VERSION "HNNBNNNYNNNNNNNNNNNNNNNNNNNNNNNNNNNNNNNNNN/4/%%%/4/'%**4NNN///"

NS_ :

BS_:

BU_: ADR_PAG_X2 BAP_Tester GW_App_PAG_PF GW_Routing_PAG_PF Klima_PAG_PF Klimakomp_Dash_PAG_PF Kombi_PAG_PF Miko_PAG_X2 OCU_PAG_PF RDK_High_PAG_PF

BO_ 1706 Kombi_12_PAG: 8 Kombi_PAG_PF
 SG_ KBI_STH_Std : 0|5@1+ (1,0) [0|23] "Unit_Hours"  GW_App_PAG_PF
 SG_ KBI_STH_Min : 5|6@1+ (1,0) [0|59] "Unit_Minut"  GW_App_PAG_PF
 SG_ KBI_STH_TT : 11|5@1+ (1,0) [1|31] "Unit_Day"  GW_App_PAG_PF
 SG_ KBI_STH_MM : 16|4@1+ (1,0) [1|12] "Unit_Month"  GW_App_PAG_PF
 SG_ KBI_STH_JJ : 20|7@1+ (1,0) [0|127] "Unit_Year"  GW_App_PAG_PF
 SG_ KBI_STH_Status : 27|2@1+ (1,0) [0|3] "" Vector__XXX
 SG_ KBI_STH_Timer_Status : 29|1@1+ (1,0) [0|1] ""  GW_App_PAG_PF
 SG_ KBI_STH_Betriebsdauer : 30|6@1+ (1,0) [0|60] "Unit_Minut" Vector__XXX
 SG_ KBI_Menu1_Pos1 : 40|1@1+ (1,0) [0|1] ""  Klima_PAG_PF
 SG_ KBI_Menu1_Pos2 : 41|1@1+ (1,0) [0|1] ""  Klima_PAG_PF
 SG_ KBI_Menu1_Pos3 : 42|1@1+ (1,0) [0|1] ""  Klima_PAG_PF
 SG_ KBI_Menu1_Pos4 : 43|1@1+ (1,0) [0|1] ""  Klima_PAG_PF
 SG_ KBI_Menu1_Pos5 : 44|1@1+ (1,0) [0|1] ""  Klima_PAG_PF
 SG_ KBI_Menu1_Pos6 : 45|1@1+ (1,0) [0|1] ""  Klima_PAG_PF
 SG_ KBI_Menu1_Pos7 : 46|1@1+ (1,0) [0|1] ""  Klima_PAG_PF
 SG_ KBI_Menu1_Pos8 : 47|1@1+ (1,0) [0|1] ""  Klima_PAG_PF
 SG_ KBI_Menu2_Pos1 : 48|1@1+ (1,0) [0|1] ""  Klima_PAG_PF
 SG_ KBI_Menu2_Pos2 : 49|1@1+ (1,0) [0|1] ""  Klima_PAG_PF
 SG_ KBI_Menu2_Pos3 : 50|1@1+ (1,0) [0|1] ""  Klima_PAG_PF
 SG_ KBI_Menu2_Pos4 : 51|1@1+ (1,0) [0|1] ""  Klima_PAG_PF
 SG_ KBI_Menu2_Pos5 : 52|1@1+ (1,0) [0|1] ""  Klima_PAG_PF
 SG_ KBI_Menu2_Pos6 : 53|1@1+ (1,0) [0|1] ""  Klima_PAG_PF
 SG_ KBI_Menu2_Pos7 : 54|1@1+ (1,0) [0|1] ""  Klima_PAG_PF
 SG_ KBI_Menu2_Pos8 : 55|1@1+ (1,0) [0|1] ""  Klima_PAG_PF
 SG_ KBI_Menu3_Pos1 : 56|1@1+ (1,0) [0|1] ""  Klima_PAG_PF
 SG_ KBI_Menu3_Pos2 : 57|1@1+ (1,0) [0|1] ""  Klima_PAG_PF
 SG_ KBI_Menu3_Pos3 : 58|1@1+ (1,0) [0|1] ""  Klima_PAG_PF
 SG_ KBI_Menu3_Pos4 : 59|1@1+ (1,0) [0|1] ""  Klima_PAG_PF
 SG_ KBI_Menu3_Pos5 : 60|1@1+ (1,0) [0|1] ""  Klima_PAG_PF
 SG_ KBI_Menu3_Pos6 : 61|1@1+ (1,0) [0|1] ""  Klima_PAG_PF
 SG_ KBI_Menu3_Pos7 : 62|1@1+ (1,0) [0|1] ""  Klima_PAG_PF
 SG_ KBI_Menu3_Pos8 : 63|1@1+ (1,0) [0|1] ""  Klima_PAG_PF

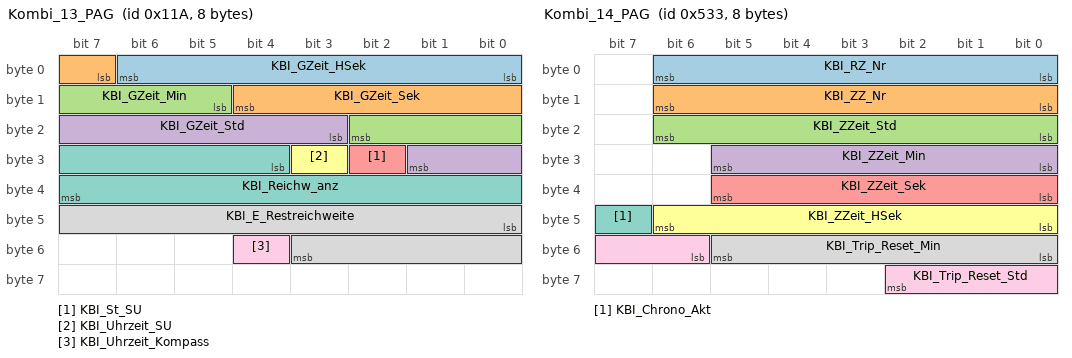
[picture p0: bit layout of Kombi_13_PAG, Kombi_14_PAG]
BO_ 282 Kombi_13_PAG: 8 Kombi_PAG_PF
 SG_ KBI_GZeit_HSek : 0|7@1+ (1,0) [0|99] ""  GW_Routing_PAG_PF
 SG_ KBI_GZeit_Sek : 7|6@1+ (1,0) [0|59] "Unit_Secon"  GW_Routing_PAG_PF
 SG_ KBI_GZeit_Min : 13|6@1+ (1,0) [0|59] "Unit_Minut"  GW_Routing_PAG_PF
 SG_ KBI_GZeit_Std : 19|7@1+ (1,0) [0|99] "Unit_Hours"  GW_Routing_PAG_PF
 SG_ KBI_St_SU : 26|1@1+ (1,0) [0|1] ""  GW_Routing_PAG_PF
 SG_ KBI_Uhrzeit_SU : 27|1@1+ (1,0) [0|1] ""  GW_Routing_PAG_PF
 SG_ KBI_Reichw_anz : 28|12@1+ (1,0) [0|4095] "Unit_KiloMeter"  ADR_PAG_X2,GW_Routing_PAG_PF,OCU_PAG_PF
 SG_ KBI_E_Restreichweite : 40|12@1+ (1,0) [0|4093] "Unit_KiloMeter"  ADR_PAG_X2,GW_Routing_PAG_PF,OCU_PAG_PF
 SG_ KBI_Uhrzeit_Kompass : 52|1@1+ (1,0) [0|1] ""  GW_Routing_PAG_PF

BO_ 1331 Kombi_14_PAG: 8 Kombi_PAG_PF
 SG_ KBI_RZ_Nr : 0|7@1+ (1,0) [0|99] ""  GW_Routing_PAG_PF
 SG_ KBI_ZZ_Nr : 8|7@1+ (1,0) [0|99] ""  GW_Routing_PAG_PF
 SG_ KBI_ZZeit_Std : 16|7@1+ (1,0) [0|99] "Unit_Hours"  GW_Routing_PAG_PF
 SG_ KBI_ZZeit_Min : 24|6@1+ (1,0) [0|59] "Unit_Minut"  GW_Routing_PAG_PF
 SG_ KBI_ZZeit_Sek : 32|6@1+ (1,0) [0|59] "Unit_Secon"  GW_Routing_PAG_PF
 SG_ KBI_ZZeit_HSek : 40|7@1+ (1,0) [0|99] ""  GW_Routing_PAG_PF
 SG_ KBI_Chrono_Akt : 47|1@1+ (1,0) [0|1] ""  GW_Routing_PAG_PF
 SG_ KBI_Trip_Reset_Min : 48|6@1+ (1,0) [0|63] ""  ADR_PAG_X2,GW_Routing_PAG_PF,OCU_PAG_PF
 SG_ KBI_Trip_Reset_Std : 54|5@1+ (1,0) [0|31] ""  ADR_PAG_X2,GW_Routing_PAG_PF,OCU_PAG_PF

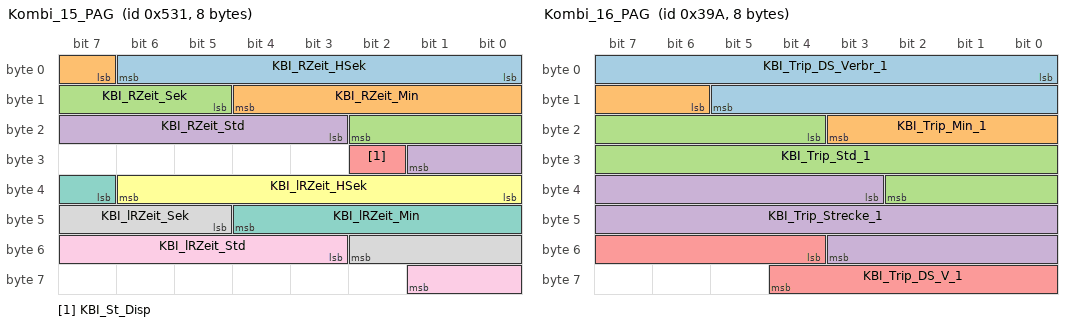
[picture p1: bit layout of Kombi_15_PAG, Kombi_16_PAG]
BO_ 1329 Kombi_15_PAG: 8 Kombi_PAG_PF
 SG_ KBI_RZeit_HSek : 0|7@1+ (1,0) [0|99] "" Vector__XXX
 SG_ KBI_RZeit_Min : 7|6@1+ (1,0) [0|59] "Unit_Minut" Vector__XXX
 SG_ KBI_RZeit_Sek : 13|6@1+ (1,0) [0|59] "Unit_Secon" Vector__XXX
 SG_ KBI_RZeit_Std : 19|7@1+ (1,0) [0|99] "Unit_Hours" Vector__XXX
 SG_ KBI_St_Disp : 26|1@1+ (1,0) [0|1] "" Vector__XXX
 SG_ KBI_lRZeit_HSek : 32|7@1+ (1,0) [0|99] "" Vector__XXX
 SG_ KBI_lRZeit_Min : 39|6@1+ (1,0) [0|59] "" Vector__XXX
 SG_ KBI_lRZeit_Sek : 45|6@1+ (1,0) [0|59] "" Vector__XXX
 SG_ KBI_lRZeit_Std : 51|7@1+ (1,0) [0|99] "Unit_Hours" Vector__XXX

BO_ 922 Kombi_16_PAG: 8 Kombi_PAG_PF
 SG_ KBI_Trip_DS_Verbr_1 : 0|14@1+ (0.01,0) [0|99.99] "Unit_LiterPer100Kilometer"  ADR_PAG_X2,GW_Routing_PAG_PF,OCU_PAG_PF
 SG_ KBI_Trip_Min_1 : 14|6@1+ (1,0) [0|59] "Unit_Minut"  ADR_PAG_X2,GW_Routing_PAG_PF,OCU_PAG_PF
 SG_ KBI_Trip_Std_1 : 20|15@1+ (1,0) [0|9999] "Unit_Hours"  ADR_PAG_X2,GW_Routing_PAG_PF,OCU_PAG_PF
 SG_ KBI_Trip_Strecke_1 : 35|17@1+ (0.1,0) [0|9999.9] "Unit_KiloMeter"  ADR_PAG_X2,GW_Routing_PAG_PF,OCU_PAG_PF
 SG_ KBI_Trip_DS_V_1 : 52|9@1+ (1,0) [0|399] "Unit_KiloMeterPerHour"  ADR_PAG_X2,GW_Routing_PAG_PF,OCU_PAG_PF

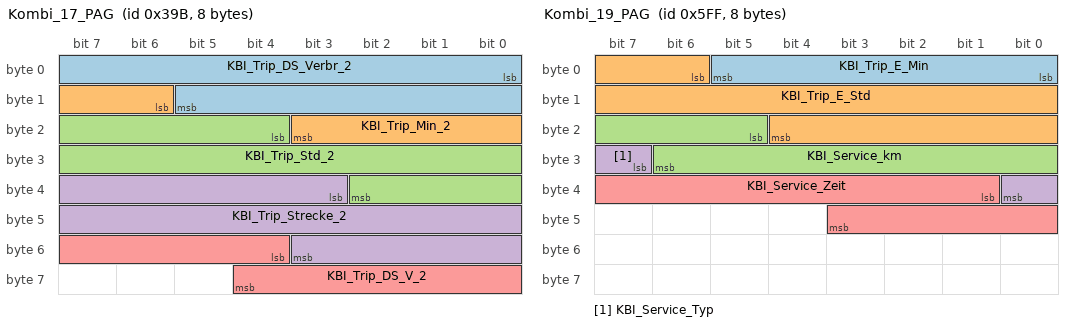
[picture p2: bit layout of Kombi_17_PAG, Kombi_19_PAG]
BO_ 923 Kombi_17_PAG: 8 Kombi_PAG_PF
 SG_ KBI_Trip_DS_Verbr_2 : 0|14@1+ (0.01,0) [0|99.99] "Unit_LiterPer100Kilometer"  ADR_PAG_X2,GW_Routing_PAG_PF,OCU_PAG_PF
 SG_ KBI_Trip_Min_2 : 14|6@1+ (1,0) [0|59] "Unit_Minut"  ADR_PAG_X2,GW_Routing_PAG_PF,OCU_PAG_PF
 SG_ KBI_Trip_Std_2 : 20|15@1+ (1,0) [0|9999] "Unit_Hours"  ADR_PAG_X2,GW_Routing_PAG_PF,OCU_PAG_PF
 SG_ KBI_Trip_Strecke_2 : 35|17@1+ (0.1,0) [0|9999.9] "Unit_KiloMeter"  ADR_PAG_X2,GW_Routing_PAG_PF,OCU_PAG_PF
 SG_ KBI_Trip_DS_V_2 : 52|9@1+ (1,0) [0|399] "Unit_KiloMeterPerHour"  ADR_PAG_X2,GW_Routing_PAG_PF,OCU_PAG_PF

BO_ 1534 Kombi_18_PAG: 8 ADR_PAG_X2
 SG_ KBI_Set_Timer_MUX M : 0|3@1+ (1,0) [0|7] ""  GW_Routing_PAG_PF
 SG_ KBI_Set_Timer_1_Jahr m1 : 3|7@1+ (1,2000) [2000|2125] "Unit_Year"  GW_Routing_PAG_PF
 SG_ KBI_Set_Timer_2_Jahr m2 : 3|7@1+ (1,2000) [2000|2125] "Unit_Year"  GW_Routing_PAG_PF
 SG_ KBI_Set_Timer_3_Jahr m3 : 3|7@1+ (1,2000) [2000|2125] "Unit_Year"  GW_Routing_PAG_PF
 SG_ KBI_Set_Timer_4_Jahr m4 : 3|7@1+ (1,2000) [2000|2125] "Unit_Year"  GW_Routing_PAG_PF
 SG_ KBI_Set_Timer_1_Minute m1 : 10|6@1+ (1,0) [0|59] "Unit_Minut"  GW_Routing_PAG_PF
 SG_ KBI_Set_Timer_2_Minute m2 : 10|6@1+ (1,0) [0|59] "Unit_Minut"  GW_Routing_PAG_PF
 SG_ KBI_Set_Timer_3_Minute m3 : 10|6@1+ (1,0) [0|0] "Unit_Minut"  GW_Routing_PAG_PF
 SG_ KBI_Set_Timer_4_Minute m4 : 10|6@1+ (1,0) [0|0] "Unit_Minut"  GW_Routing_PAG_PF
 SG_ KBI_Set_Timer_1_Monat m1 : 16|4@1+ (1,0) [1|12] "Unit_Month"  GW_Routing_PAG_PF
 SG_ KBI_Set_Timer_2_Monat m2 : 16|4@1+ (1,0) [1|12] "Unit_Month"  GW_Routing_PAG_PF
 SG_ KBI_Set_Timer_3_Monat m3 : 16|4@1+ (1,0) [1|12] "Unit_Month"  GW_Routing_PAG_PF
 SG_ KBI_Set_Timer_4_Monat m4 : 16|4@1+ (1,0) [1|12] "Unit_Month"  GW_Routing_PAG_PF
 SG_ KBI_Set_Timer_1_Stunde m1 : 20|5@1+ (1,0) [0|23] "Unit_Hours"  GW_Routing_PAG_PF
 SG_ KBI_Set_Timer_2_Stunde m2 : 20|5@1+ (1,0) [0|23] "Unit_Hours"  GW_Routing_PAG_PF
 SG_ KBI_Set_Timer_3_Stunde m3 : 20|5@1+ (1,0) [0|23] "Unit_Hours"  GW_Routing_PAG_PF
 SG_ KBI_Set_Timer_4_Stunde m4 : 20|5@1+ (1,0) [0|23] "Unit_Hours"  GW_Routing_PAG_PF
 SG_ KBI_Set_Timer_1_Tag m1 : 25|5@1+ (1,0) [1|31] "Unit_Day"  GW_Routing_PAG_PF
 SG_ KBI_Set_Timer_2_Tag m2 : 25|5@1+ (1,0) [1|31] "Unit_Day"  GW_Routing_PAG_PF
 SG_ KBI_Set_Timer_3_Tag m3 : 25|5@1+ (1,0) [1|31] "Unit_Day"  GW_Routing_PAG_PF
 SG_ KBI_Set_Timer_4_Tag m4 : 25|5@1+ (1,0) [1|31] "Unit_Day"  GW_Routing_PAG_PF
 SG_ KBI_Set_Timer_1_Laden m1 : 30|1@1+ (1,0) [0|1] ""  GW_Routing_PAG_PF
 SG_ KBI_Set_Timer_2_Laden m2 : 30|1@1+ (1,0) [0|1] ""  GW_Routing_PAG_PF
 SG_ KBI_Set_Timer_3_Laden m3 : 30|1@1+ (1,0) [0|1] ""  GW_Routing_PAG_PF
 SG_ KBI_Set_Timer_4_Laden m4 : 30|1@1+ (1,0) [0|1] ""  GW_Routing_PAG_PF
 SG_ KBI_Set_Timer_1_Vorklima m1 : 31|1@1+ (1,0) [0|1] ""  GW_Routing_PAG_PF
 SG_ KBI_Set_Timer_2_Vorklima m2 : 31|1@1+ (1,0) [0|1] ""  GW_Routing_PAG_PF
 SG_ KBI_Set_Timer_3_Vorklima m3 : 31|1@1+ (1,0) [0|1] ""  GW_Routing_PAG_PF
 SG_ KBI_Set_Timer_4_Vorklima m4 : 31|1@1+ (1,0) [0|1] ""  GW_Routing_PAG_PF
 SG_ KBI_Set_Timer_1_Zyklus_Mo m1 : 32|1@1+ (1,0) [0|1] ""  GW_Routing_PAG_PF
 SG_ KBI_Set_Timer_2_Zyklus_Mo m2 : 32|1@1+ (1,0) [0|1] ""  GW_Routing_PAG_PF
 SG_ KBI_Set_Timer_3_Zyklus_Mo m3 : 32|1@1+ (1,0) [0|1] ""  GW_Routing_PAG_PF
 SG_ KBI_Set_Timer_4_Zyklus_Mo m4 : 32|1@1+ (1,0) [0|1] ""  GW_Routing_PAG_PF
 SG_ KBI_Set_Timer_1_Zyklus_Di m1 : 33|1@1+ (1,0) [0|1] ""  GW_Routing_PAG_PF
 SG_ KBI_Set_Timer_2_Zyklus_Di m2 : 33|1@1+ (1,0) [0|1] ""  GW_Routing_PAG_PF
 SG_ KBI_Set_Timer_3_Zyklus_Di m3 : 33|1@1+ (1,0) [0|1] ""  GW_Routing_PAG_PF
 SG_ KBI_Set_Timer_4_Zyklus_Di m4 : 33|1@1+ (1,0) [0|1] ""  GW_Routing_PAG_PF
 SG_ KBI_Set_Timer_1_Zyklus_Mi m1 : 34|1@1+ (1,0) [0|1] ""  GW_Routing_PAG_PF
 SG_ KBI_Set_Timer_2_Zyklus_Mi m2 : 34|1@1+ (1,0) [0|1] ""  GW_Routing_PAG_PF
 SG_ KBI_Set_Timer_3_Zyklus_Mi m3 : 34|1@1+ (1,0) [0|1] ""  GW_Routing_PAG_PF
 SG_ KBI_Set_Timer_4_Zyklus_Mi m4 : 34|1@1+ (1,0) [0|1] ""  GW_Routing_PAG_PF
 SG_ KBI_Set_Timer_1_Zyklus_Do m1 : 35|1@1+ (1,0) [0|1] ""  GW_Routing_PAG_PF
 SG_ KBI_Set_Timer_2_Zyklus_Do m2 : 35|1@1+ (1,0) [0|1] ""  GW_Routing_PAG_PF
 SG_ KBI_Set_Timer_3_Zyklus_Do m3 : 35|1@1+ (1,0) [0|1] ""  GW_Routing_PAG_PF
 SG_ KBI_Set_Timer_4_Zyklus_Do m4 : 35|1@1+ (1,0) [0|1] ""  GW_Routing_PAG_PF
 SG_ KBI_Set_Timer_1_Zyklus_Fr m1 : 36|1@1+ (1,0) [0|1] ""  GW_Routing_PAG_PF
 SG_ KBI_Set_Timer_2_Zyklus_Fr m2 : 36|1@1+ (1,0) [0|1] ""  GW_Routing_PAG_PF
 SG_ KBI_Set_Timer_3_Zyklus_Fr m3 : 36|1@1+ (1,0) [0|1] ""  GW_Routing_PAG_PF
 SG_ KBI_Set_Timer_4_Zyklus_Fr m4 : 36|1@1+ (1,0) [0|1] ""  GW_Routing_PAG_PF
 SG_ KBI_Set_Timer_1_Zyklus_Sa m1 : 37|1@1+ (1,0) [0|1] ""  GW_Routing_PAG_PF
 SG_ KBI_Set_Timer_2_Zyklus_Sa m2 : 37|1@1+ (1,0) [0|1] ""  GW_Routing_PAG_PF
 SG_ KBI_Set_Timer_3_Zyklus_Sa m3 : 37|1@1+ (1,0) [0|1] ""  GW_Routing_PAG_PF
 SG_ KBI_Set_Timer_4_Zyklus_Sa m4 : 37|1@1+ (1,0) [0|1] ""  GW_Routing_PAG_PF
 SG_ KBI_Set_Timer_1_Zyklus_So m1 : 38|1@1+ (1,0) [0|1] ""  GW_Routing_PAG_PF
 SG_ KBI_Set_Timer_2_Zyklus_So m2 : 38|1@1+ (1,0) [0|1] ""  GW_Routing_PAG_PF
 SG_ KBI_Set_Timer_3_Zyklus_So m3 : 38|1@1+ (1,0) [0|1] ""  GW_Routing_PAG_PF
 SG_ KBI_Set_Timer_4_Zyklus_So m4 : 38|1@1+ (1,0) [0|1] ""  GW_Routing_PAG_PF
 SG_ KBI_Set_Timer_1_Zyklus_WH m1 : 39|1@1+ (1,0) [0|1] ""  GW_Routing_PAG_PF
 SG_ KBI_Set_Timer_2_Zyklus_WH m2 : 39|1@1+ (1,0) [0|1] ""  GW_Routing_PAG_PF
 SG_ KBI_Set_Timer_3_Zyklus_WH m3 : 39|1@1+ (1,0) [0|1] ""  GW_Routing_PAG_PF
 SG_ KBI_Set_Timer_4_Zyklus_WH m4 : 39|1@1+ (1,0) [0|1] ""  GW_Routing_PAG_PF

BO_ 1535 Kombi_19_PAG: 8 Kombi_PAG_PF
 SG_ KBI_Trip_E_Min : 0|6@1+ (1,0) [0|59] "Unit_Minut"  ADR_PAG_X2,GW_Routing_PAG_PF
 SG_ KBI_Trip_E_Std : 6|15@1+ (1,0) [0|9999] "Unit_Hours"  ADR_PAG_X2,GW_Routing_PAG_PF
 SG_ KBI_Service_km : 21|10@1+ (100,0) [0|102100] ""  GW_Routing_PAG_PF
 SG_ KBI_Service_Typ : 31|2@1+ (1,0) [0|3] ""  GW_Routing_PAG_PF
 SG_ KBI_Service_Zeit : 33|11@1+ (1,0) [0|2045] ""  GW_Routing_PAG_PF

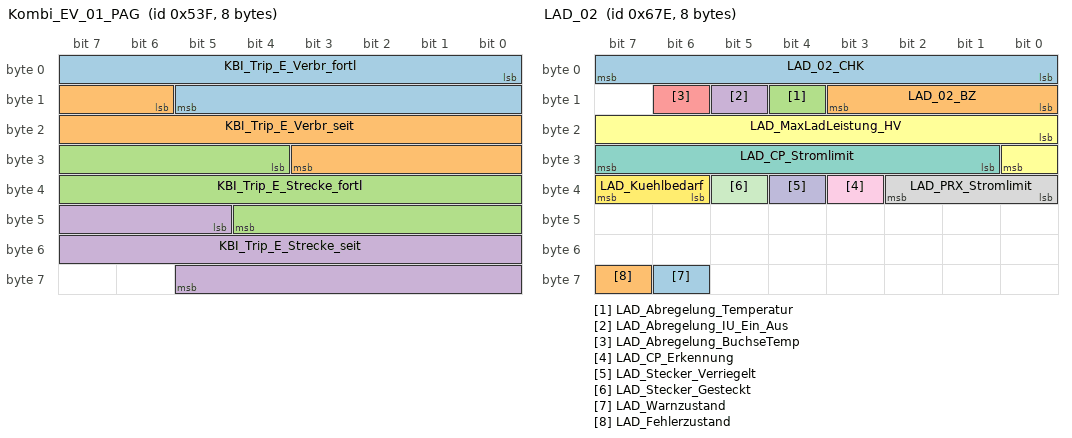
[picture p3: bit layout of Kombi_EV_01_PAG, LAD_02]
BO_ 1343 Kombi_EV_01_PAG: 8 Kombi_PAG_PF
 SG_ KBI_Trip_E_Verbr_fortl : 0|14@1+ (0.01,0) [0|100] "Unit_KiloWattHourPer100Kilometer"  ADR_PAG_X2,GW_Routing_PAG_PF,OCU_PAG_PF
 SG_ KBI_Trip_E_Verbr_seit : 14|14@1+ (0.01,0) [0|100] "Unit_KiloWattHourPer100Kilometer"  ADR_PAG_X2,GW_Routing_PAG_PF,OCU_PAG_PF
 SG_ KBI_Trip_E_Strecke_fortl : 28|17@1+ (0.1,0) [0|9999.9] "Unit_KiloMeter"  ADR_PAG_X2,GW_Routing_PAG_PF,OCU_PAG_PF
 SG_ KBI_Trip_E_Strecke_seit : 45|17@1+ (0.1,0) [0|9999.9] "Unit_KiloMeter"  ADR_PAG_X2,GW_Routing_PAG_PF,OCU_PAG_PF

BO_ 1662 LAD_02: 8 GW_Routing_PAG_PF
 SG_ LAD_02_CHK : 0|8@1+ (1,0) [0|255] "" Vector__XXX
 SG_ LAD_02_BZ : 8|4@1+ (1,0) [0|15] "" Vector__XXX
 SG_ LAD_Abregelung_Temperatur : 12|1@1+ (1,0) [0|1] "" Vector__XXX
 SG_ LAD_Abregelung_IU_Ein_Aus : 13|1@1+ (1,0) [0|1] "" Vector__XXX
 SG_ LAD_Abregelung_BuchseTemp : 14|1@1+ (1,0) [0|1] "" Vector__XXX
 SG_ LAD_MaxLadLeistung_HV : 16|9@1+ (100,0) [0|50900] "Unit_Watt" Vector__XXX
 SG_ LAD_CP_Stromlimit : 25|7@1+ (0.5,0) [0|62.5] "Unit_Amper" Vector__XXX
 SG_ LAD_PRX_Stromlimit : 32|3@1+ (1,0) [0|7] "" Vector__XXX
 SG_ LAD_CP_Erkennung : 35|1@1+ (1,0) [0|1] "" Vector__XXX
 SG_ LAD_Stecker_Verriegelt : 36|1@1+ (1,0) [0|1] "" Vector__XXX
 SG_ LAD_Stecker_Gesteckt : 37|1@1+ (1,0) [0|1] "" Vector__XXX
 SG_ LAD_Kuehlbedarf : 38|2@1+ (1,0) [0|3] "" Vector__XXX
 SG_ LAD_Warnzustand : 62|1@1+ (1,0) [0|1] ""  ADR_PAG_X2,Kombi_PAG_PF
 SG_ LAD_Fehlerzustand : 63|1@1+ (1,0) [0|1] ""  ADR_PAG_X2,Kombi_PAG_PF

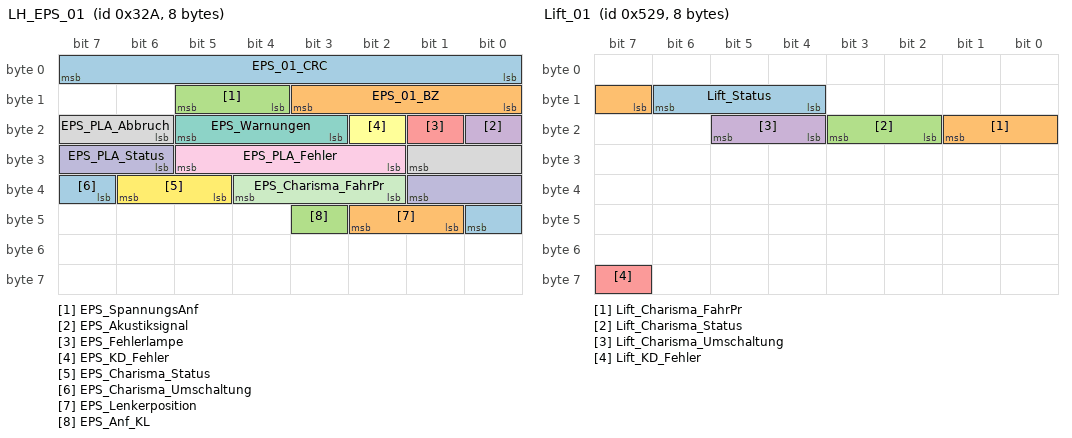
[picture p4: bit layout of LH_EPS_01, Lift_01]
BO_ 810 LH_EPS_01: 8 GW_Routing_PAG_PF
 SG_ EPS_01_CRC : 0|8@1+ (1,0) [0|255] "" Vector__XXX
 SG_ EPS_01_BZ : 8|4@1+ (1,0) [0|15] "" Vector__XXX
 SG_ EPS_SpannungsAnf : 12|2@1+ (1,0) [0|3] "" Vector__XXX
 SG_ EPS_Akustiksignal : 16|1@1+ (1,0) [0|1] "" Vector__XXX
 SG_ EPS_Fehlerlampe : 17|1@1+ (1,0) [0|1] "" Vector__XXX
 SG_ EPS_KD_Fehler : 18|1@1+ (1,0) [0|1] "" Vector__XXX
 SG_ EPS_Warnungen : 19|3@1+ (1,0) [0|7] ""  Kombi_PAG_PF
 SG_ EPS_PLA_Abbruch : 22|4@1+ (1,0) [0|15] "" Vector__XXX
 SG_ EPS_PLA_Fehler : 26|4@1+ (1,0) [0|15] "" Vector__XXX
 SG_ EPS_PLA_Status : 30|4@1+ (1,0) [0|15] "" Vector__XXX
 SG_ EPS_Charisma_FahrPr : 34|3@1+ (1,0) [0|7] "" Vector__XXX
 SG_ EPS_Charisma_Status : 37|2@1+ (1,0) [0|3] "" Vector__XXX
 SG_ EPS_Charisma_Umschaltung : 39|2@1+ (1,0) [0|3] "" Vector__XXX
 SG_ EPS_Lenkerposition : 41|2@1+ (1,0) [0|3] "" Vector__XXX
 SG_ EPS_Anf_KL : 43|1@1+ (1,0) [0|1] "" Vector__XXX

BO_ 1137 Licht_hinten_01: 8 GW_Routing_PAG_PF
 SG_ Licht_hinten_01_BZ : 0|4@1+ (1,0) [0|15] "" Vector__XXX
 SG_ BCM2_Bremsl_durch_ECD : 5|1@1+ (1,0) [0|1] "" Vector__XXX
 SG_ LH_Aussenlicht_def : 7|1@1+ (1,0) [0|1] "" Vector__XXX
 SG_ LH_Standlicht_H_aktiv : 8|1@1+ (1,0) [0|1] "" Vector__XXX
 SG_ LH_Parklicht_HL_aktiv : 9|1@1+ (1,0) [0|1] "" Vector__XXX
 SG_ LH_Parklicht_HR_aktiv : 10|1@1+ (1,0) [0|1] "" Vector__XXX
 SG_ LH_Bremslicht_H_aktiv : 11|1@1+ (1,0) [0|1] "" Vector__XXX
 SG_ LH_Nebelschluss_aktiv : 12|1@1+ (1,0) [0|1] "" Vector__XXX
 SG_ LH_Rueckfahrlicht_aktiv : 13|1@1+ (1,0) [0|1] "" Vector__XXX
 SG_ LH_Blinker_HL_akt : 14|1@1+ (1,0) [0|1] "" Vector__XXX
 SG_ LH_Blinker_HR_akt : 15|1@1+ (1,0) [0|1] "" Vector__XXX
 SG_ LH_Blinker_li_def : 16|1@1+ (1,0) [0|1] "" Vector__XXX
 SG_ LH_Bremsl_li_def : 17|1@1+ (1,0) [0|1] ""  Kombi_PAG_PF
 SG_ LH_Schlusslicht_li_def : 18|1@1+ (1,0) [0|1] ""  Kombi_PAG_PF
 SG_ LH_Rueckf_li_def : 19|1@1+ (1,0) [0|1] ""  Kombi_PAG_PF
 SG_ LH_Nebel_li_def : 20|1@1+ (1,0) [0|1] ""  Kombi_PAG_PF
 SG_ LH_Schluss_Brems_Nebel_li_def : 21|1@1+ (1,0) [0|1] ""  Kombi_PAG_PF
 SG_ LH_Schluss_Brems_Nebel_re_def : 22|1@1+ (1,0) [0|1] ""  Kombi_PAG_PF
 SG_ LH_Schluss_Brems_li_def : 24|1@1+ (1,0) [0|1] "" Vector__XXX
 SG_ LH_Schluss_Nebel_li_def : 25|1@1+ (1,0) [0|1] "" Vector__XXX
 SG_ LH_SL_BRL_BLK_li_def : 26|1@1+ (1,0) [0|1] "" Vector__XXX
 SG_ LH_Brems_Blk_li_def : 27|1@1+ (1,0) [0|1] "" Vector__XXX
 SG_ LH_Blinker_re_def : 32|1@1+ (1,0) [0|1] "" Vector__XXX
 SG_ LH_Bremsl_re_def : 33|1@1+ (1,0) [0|1] ""  Kombi_PAG_PF
 SG_ LH_Schlusslicht_re_def : 34|1@1+ (1,0) [0|1] ""  Kombi_PAG_PF
 SG_ LH_Rueckf_re_def : 35|1@1+ (1,0) [0|1] ""  Kombi_PAG_PF
 SG_ LH_Nebel_re_def : 36|1@1+ (1,0) [0|1] ""  Kombi_PAG_PF
 SG_ LH_Schluss_Brems_re_def : 40|1@1+ (1,0) [0|1] "" Vector__XXX
 SG_ LH_Schluss_Nebel_re_def : 41|1@1+ (1,0) [0|1] "" Vector__XXX
 SG_ LH_SL_BRL_BLK_re_def : 42|1@1+ (1,0) [0|1] "" Vector__XXX
 SG_ LH_Brems_Blk_re_def : 43|1@1+ (1,0) [0|1] "" Vector__XXX
 SG_ LH_Kennzl_def : 48|1@1+ (1,0) [0|1] ""  Kombi_PAG_PF
 SG_ LH_3_Bremsl_def : 49|1@1+ (1,0) [0|1] ""  Kombi_PAG_PF
 SG_ LH_Nebel_mi_def : 50|1@1+ (1,0) [0|1] "" Vector__XXX
 SG_ LH_Rueckf_mi_def : 51|1@1+ (1,0) [0|1] "" Vector__XXX
 SG_ LH_Bremsl_li_ges_def : 54|1@1+ (1,0) [0|1] "" Vector__XXX
 SG_ LH_Bremsl_re_ges_def : 55|1@1+ (1,0) [0|1] "" Vector__XXX

BO_ 1321 Lift_01: 8 GW_Routing_PAG_PF
 SG_ Lift_Status : 12|3@1+ (1,0) [0|7] ""  ADR_PAG_X2,Kombi_PAG_PF
 SG_ Lift_Charisma_FahrPr : 15|3@1+ (1,0) [0|7] "" Vector__XXX
 SG_ Lift_Charisma_Status : 18|2@1+ (1,0) [0|3] "" Vector__XXX
 SG_ Lift_Charisma_Umschaltung : 20|2@1+ (1,0) [0|3] "" Vector__XXX
 SG_ Lift_KD_Fehler : 63|1@1+ (1,0) [0|1] "" Vector__XXX

BO_ 917 LWR_AFS_01: 8 GW_Routing_PAG_PF
 SG_ AFS_Abbiegelicht_li_Anf : 0|1@1+ (1,0) [0|1] "" Vector__XXX
 SG_ AFS_Abbiegelicht_re_Anf : 1|1@1+ (1,0) [0|1] "" Vector__XXX
 SG_ AFS_Abbiegelicht_Dimm_Anf : 2|1@1+ (1,0) [0|1] "" Vector__XXX
 SG_ AFS_Verfuegbarkeit_GLW : 3|1@1+ (1,0) [0|1] "" Vector__XXX
 SG_ AFS_Status_adaptive_LV : 4|1@1+ (1,0) [0|1] "" Vector__XXX
 SG_ AFS_Fernlicht_li_defekt : 5|1@1+ (1,0) [0|1] "" Vector__XXX
 SG_ AFS_Fernlicht_re_defekt : 6|1@1+ (1,0) [0|1] "" Vector__XXX
 SG_ AFS_Fernlicht_Status : 7|1@1+ (1,0) [0|1] "" Vector__XXX
 SG_ LWR_AFS_01_BZ : 8|4@1+ (1,0) [0|15] "" Vector__XXX
 SG_ AFS_Lampe : 12|1@1+ (1,0) [0|1] "" Vector__XXX
 SG_ LWR_Lampe : 13|1@1+ (1,0) [0|1] "" Vector__XXX
 SG_ AFS_Fehlertext : 14|1@1+ (1,0) [0|1] "" Vector__XXX
 SG_ AFS_LED_Blinkmode : 15|1@1+ (1,0) [0|1] "" Vector__XXX
 SG_ LWR_Touristenmodus_aktiv : 16|1@1+ (1,0) [0|1] "" Vector__XXX
 SG_ AFS_Charisma_FahrPr : 17|3@1+ (1,0) [0|7] "" Vector__XXX
 SG_ AFS_Charisma_Status : 20|2@1+ (1,0) [0|3] "" Vector__XXX
 SG_ AFS_Charisma_Umschaltung : 22|2@1+ (1,0) [0|3] "" Vector__XXX
 SG_ AFS_Allwetterlicht : 24|1@1+ (1,0) [0|1] "" Vector__XXX
 SG_ LWR_Touristenmodus_verbaut : 25|1@1+ (1,0) [0|1] "" Vector__XXX
 SG_ AFS_adaptive_LV_verbaut : 26|1@1+ (1,0) [0|1] "" Vector__XXX
 SG_ LWR_Reisemodus_Texte : 27|2@1+ (1,0) [0|3] "" Vector__XXX
 SG_ GLW_Sensor_blockiert : 29|1@1+ (1,0) [0|1] "" Vector__XXX
 SG_ LWR_Pos_Schrittmotor : 32|8@1+ (0.4,0) [0|100] "Unit_PerCent" Vector__XXX
 SG_ LWR_Hoehenwert_VL : 40|8@1+ (1,-127) [-127|126] "" Vector__XXX
 SG_ LWR_Hoehenwert_HL : 48|8@1+ (1,-127) [-127|126] "" Vector__XXX
 SG_ AFS_Ersatzlicht_Links : 56|1@1+ (1,0) [0|1] "" Vector__XXX
 SG_ AFS_Ersatzlicht_Rechts : 57|1@1+ (1,0) [0|1] "" Vector__XXX
 SG_ LWR_AFS_Grundeinstellung : 58|1@1+ (1,0) [0|1] "" Vector__XXX
 SG_ LWR_AFS_Parametrisierung : 59|1@1+ (1,0) [0|1] "" Vector__XXX
 SG_ LWR_Initialisierungslauf : 60|1@1+ (1,0) [0|1] "" Vector__XXX
 SG_ LWR_Sicherheitsposition : 61|1@1+ (1,0) [0|1] "" Vector__XXX
 SG_ LWR_Modus : 62|1@1+ (1,0) [0|1] "" Vector__XXX
 SG_ LWR_KD_Fehler : 63|1@1+ (1,0) [0|1] ""  Kombi_PAG_PF

BO_ 1704 Mem_Kombi_01_PAG: 8 ADR_PAG_X2
 SG_ KBI_Aussenspiegel_absenken_auto : 0|1@1+ (1,0) [0|1] ""  GW_Routing_PAG_PF
 SG_ KBI_Aussenspiegel_einklapp_auto : 1|1@1+ (1,0) [0|1] ""  GW_Routing_PAG_PF
 SG_ KBI_Schaltpkt_Anz_ein : 2|1@1+ (1,0) [0|1] ""  GW_Routing_PAG_PF,Kombi_PAG_PF
 SG_ KBI_FULL_AFS_Tourist : 3|1@1+ (1,0) [0|1] ""  GW_Routing_PAG_PF
 SG_ KBI_Einstiegshilfe_aktiv : 4|1@1+ (1,0) [0|1] ""  GW_Routing_PAG_PF
 SG_ KBI_Schneekettenmodus_Aktiv : 5|1@1+ (1,0) [0|1] ""  GW_Routing_PAG_PF
 SG_ KBI_FLA_GLW_Aktiv : 6|1@1+ (1,0) [0|1] ""  GW_Routing_PAG_PF
 SG_ KBI_Dimmung_OriLicht : 8|7@1+ (1,0) [0|100] "Unit_PerCent"  GW_Routing_PAG_PF
 SG_ KBI_RS_d_akt : 15|1@1+ (1,0) [0|1] ""  GW_Routing_PAG_PF
 SG_ KBI_Nachleucht_IL : 16|5@1+ (10,0) [0|300] "Unit_Secon"  GW_Routing_PAG_PF
 SG_ KBI_Erw_BelueftFeld : 21|1@1+ (1,0) [0|1] ""  GW_Routing_PAG_PF,Klima_PAG_PF
 SG_ KBI_Auto_Umluft : 22|1@1+ (1,0) [0|1] ""  GW_Routing_PAG_PF,Klima_PAG_PF
 SG_ KBI_Heckrollo_b_R : 23|1@1+ (1,0) [0|1] ""  GW_Routing_PAG_PF
 SG_ KBI_Nachleucht : 24|5@1+ (5,0) [0|120] ""  GW_Routing_PAG_PF
 SG_ KBI_TFL_akt : 29|1@1+ (1,0) [0|1] ""  GW_Routing_PAG_PF
 SG_ KBI_Heckw_b_R : 30|2@1+ (1,0) [0|3] ""  GW_Routing_PAG_PF
 SG_ KBI_WV_Entr : 32|5@1+ (5,10) [10|100] ""  GW_Routing_PAG_PF
 SG_ KBI_Tuerentr_T : 37|1@1+ (1,0) [0|1] ""  GW_Routing_PAG_PF
 SG_ KBI_Carjack : 38|2@1+ (1,0) [0|3] ""  GW_Routing_PAG_PF
 SG_ KBI_WV_Entr_Kof : 40|4@1+ (1,0) [0|15] ""  GW_Routing_PAG_PF
 SG_ KBI_Automem_Inaktiv : 45|1@1+ (1,0) [0|1] ""  GW_Routing_PAG_PF,Klima_PAG_PF
 SG_ KBI_Jokerkey_Hupe_Aktiv : 46|1@1+ (1,0) [0|1] ""  GW_Routing_PAG_PF,Klima_PAG_PF
 SG_ KBI_LDW_aktiv : 47|1@1+ (1,0) [0|1] ""  GW_Routing_PAG_PF
 SG_ KBI_PTC_Zuheizer : 48|1@1+ (1,0) [0|1] ""  GW_Routing_PAG_PF,Klima_PAG_PF
 SG_ KBI_Steigerung_Luftmenge_Fond : 49|1@1+ (1,0) [0|1] ""  GW_Routing_PAG_PF
 SG_ KBI_Klimastyles : 51|2@1+ (1,0) [0|3] ""  GW_Routing_PAG_PF,Klima_PAG_PF
 SG_ KBI_Mittenduesentemp : 53|3@1+ (1,-4) [-4|3] ""  GW_Routing_PAG_PF,Klima_PAG_PF
 SG_ KBI_Dimmung_AmbLicht : 56|7@1+ (1,0) [0|100] "Unit_PerCent"  GW_Routing_PAG_PF
 SG_ KBI_Innenlicht_per_Tuerkontakt : 63|1@1+ (1,0) [0|1] ""  GW_Routing_PAG_PF,Miko_PAG_X2

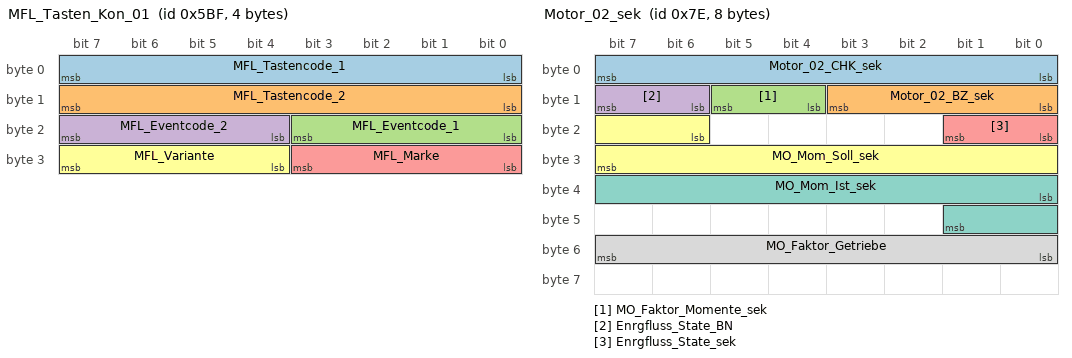
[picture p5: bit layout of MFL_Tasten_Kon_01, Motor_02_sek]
BO_ 1471 MFL_Tasten_Kon_01: 4 GW_Routing_PAG_PF
 SG_ MFL_Tastencode_1 : 0|8@1+ (1,0) [0|255] ""  ADR_PAG_X2,Klima_PAG_PF,Kombi_PAG_PF,Miko_PAG_X2
 SG_ MFL_Tastencode_2 : 8|8@1+ (1,0) [0|255] ""  ADR_PAG_X2,Klima_PAG_PF,Kombi_PAG_PF
 SG_ MFL_Eventcode_1 : 16|4@1+ (1,0) [0|15] ""  ADR_PAG_X2,Klima_PAG_PF,Kombi_PAG_PF
 SG_ MFL_Eventcode_2 : 20|4@1+ (1,0) [0|15] ""  ADR_PAG_X2,Klima_PAG_PF,Kombi_PAG_PF
 SG_ MFL_Marke : 24|4@1+ (1,0) [0|15] ""  ADR_PAG_X2,Klima_PAG_PF
 SG_ MFL_Variante : 28|4@1+ (1,0) [0|15] ""  ADR_PAG_X2,Klima_PAG_PF

BO_ 193 Miko_01_PAG: 8 Miko_PAG_X2
 SG_ Miko_KD_Fehler : 0|1@1+ (1,0) [0|1] "" Vector__XXX
 SG_ Miko_T_Defrost : 1|1@1+ (1,0) [0|1] "" Vector__XXX
 SG_ Miko_T_Auto : 2|1@1+ (1,0) [0|1] "" Vector__XXX
 SG_ Miko_T_Source : 3|1@1+ (1,0) [0|1] ""  ADR_PAG_X2
 SG_ Miko_T_AC_Menue : 4|1@1+ (1,0) [0|1] ""  ADR_PAG_X2
 SG_ Miko_T_Phone : 5|1@1+ (1,0) [0|1] ""  ADR_PAG_X2
 SG_ Miko_T_Media : 6|1@1+ (1,0) [0|1] ""  ADR_PAG_X2
 SG_ Miko_T_Tuner : 7|1@1+ (1,0) [0|1] ""  ADR_PAG_X2
 SG_ Miko_T_Back : 8|1@1+ (1,0) [0|1] ""  ADR_PAG_X2
 SG_ Miko_T_Option : 9|1@1+ (1,0) [0|1] ""  ADR_PAG_X2
 SG_ Miko_T_Car : 10|1@1+ (1,0) [0|1] ""  ADR_PAG_X2
 SG_ Miko_T_Info : 11|1@1+ (1,0) [0|1] ""  ADR_PAG_X2
 SG_ Miko_T_Navi : 12|1@1+ (1,0) [0|1] ""  ADR_PAG_X2
 SG_ Miko_T_Umluft : 13|1@1+ (1,0) [0|1] "" Vector__XXX
 SG_ Miko_T_AC : 14|1@1+ (1,0) [0|1] "" Vector__XXX
 SG_ Miko_T_Acmax : 15|1@1+ (1,0) [0|1] "" Vector__XXX
 SG_ Miko_Volume : 16|5@1+ (1,0) [0|32] ""  ADR_PAG_X2
 SG_ Miko_Volume_Err : 21|1@1+ (1,0) [0|1] ""  ADR_PAG_X2
 SG_ Miko_Volume_dir : 22|1@1+ (1,0) [0|1] ""  ADR_PAG_X2
 SG_ Miko_Volume_press : 23|2@1+ (1,0) [0|3] ""  ADR_PAG_X2
 SG_ Miko_MMI : 25|5@1+ (1,0) [0|32] ""  ADR_PAG_X2
 SG_ Miko_MMI_fast : 30|1@1+ (1,0) [0|1] ""  ADR_PAG_X2
 SG_ Miko_MMI_Err : 31|1@1+ (1,0) [0|1] ""  ADR_PAG_X2
 SG_ Miko_MMI_dir : 32|1@1+ (1,0) [0|1] ""  ADR_PAG_X2
 SG_ Miko_MMI_press : 33|2@1+ (1,0) [0|3] "" Vector__XXX
 SG_ Miko_Clima : 35|5@1+ (1,0) [0|32] "" Vector__XXX
 SG_ Miko_Clima_fast : 40|1@1+ (1,0) [0|1] "" Vector__XXX
 SG_ Miko_Clima_Err : 41|1@1+ (1,0) [0|1] "" Vector__XXX
 SG_ Miko_Clima_dir : 42|1@1+ (1,0) [0|1] "" Vector__XXX
 SG_ Miko_Clima_press : 43|2@1+ (1,0) [0|3] "" Vector__XXX
 SG_ Miko_ADR_Reset : 45|1@1+ (1,0) [0|1] ""  ADR_PAG_X2
 SG_ Miko_ADR_UltralongPress : 46|1@1+ (1,0) [0|1] ""  ADR_PAG_X2
 SG_ Miko_T_Blower : 47|1@1+ (1,0) [0|1] ""  Klima_PAG_PF
 SG_ Miko_T_Temp_left : 48|1@1+ (1,0) [0|1] ""  Klima_PAG_PF
 SG_ Miko_T_Temp_right : 49|1@1+ (1,0) [0|1] ""  Klima_PAG_PF

BO_ 126 Motor_02_sek: 8 GW_Routing_PAG_PF
 SG_ Motor_02_CHK_sek : 0|8@1+ (1,0) [0|255] "" Vector__XXX
 SG_ Motor_02_BZ_sek : 8|4@1+ (1,0) [0|15] "" Vector__XXX
 SG_ MO_Faktor_Momente_sek : 12|2@1+ (1,0) [0|3] "" Vector__XXX
 SG_ Enrgfluss_State_BN : 14|2@1+ (1,0) [0|3] ""  ADR_PAG_X2,Kombi_PAG_PF
 SG_ Enrgfluss_State_sek : 16|2@1+ (1,0) [0|3] ""  ADR_PAG_X2,Kombi_PAG_PF
 SG_ MO_Mom_Soll_sek : 22|10@1+ (1,0) [0|1021] "" Vector__XXX
 SG_ MO_Mom_Ist_sek : 32|10@1+ (1,0) [0|1021] "" Vector__XXX
 SG_ MO_Faktor_Getriebe : 48|8@1+ (0.4,0) [0|101.2] "Unit_PerCent" Vector__XXX

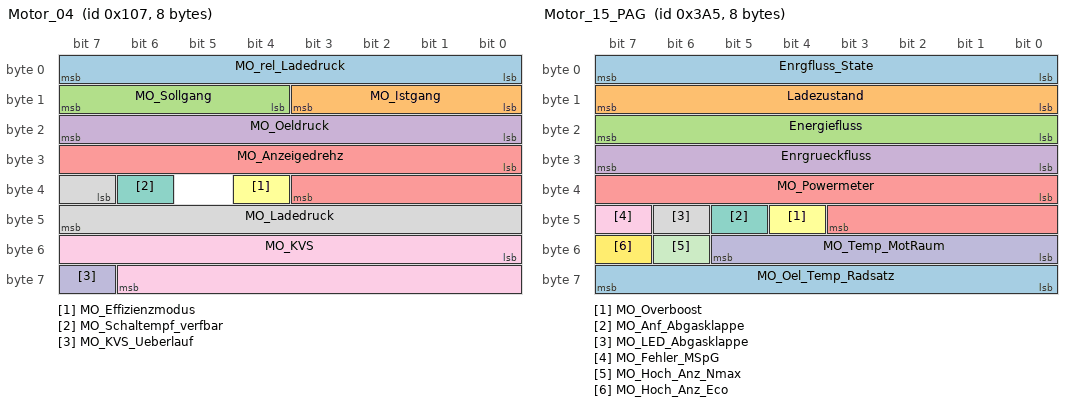
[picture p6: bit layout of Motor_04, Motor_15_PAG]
BO_ 263 Motor_04: 8 GW_Routing_PAG_PF
 SG_ MO_rel_Ladedruck : 0|8@1+ (0.4,0) [0|100] "Unit_PerCent" Vector__XXX
 SG_ MO_Istgang : 8|4@1+ (1,0) [0|15] "" Vector__XXX
 SG_ MO_Sollgang : 12|4@1+ (1,0) [0|15] "" Vector__XXX
 SG_ MO_Oeldruck : 16|8@1+ (0.04,0) [0|10] "Unit_Bar"  Kombi_PAG_PF
 SG_ MO_Anzeigedrehz : 24|12@1+ (3,0) [0|12282] "Unit_MinutInver"  Kombi_PAG_PF
 SG_ MO_Effizienzmodus : 36|1@1+ (1,0) [0|1] "" Vector__XXX
 SG_ MO_Schaltempf_verfbar : 38|1@1+ (1,0) [0|1] "" Vector__XXX
 SG_ MO_Ladedruck : 39|9@1+ (0.01,0) [0|5.1] "Unit_Bar" Vector__XXX
 SG_ MO_KVS : 48|15@1+ (1,0) [0|32767] "Unit_MicroLiter"  Kombi_PAG_PF
 SG_ MO_KVS_Ueberlauf : 63|1@1+ (1,0) [0|1] ""  Kombi_PAG_PF

BO_ 782 Motor_05: 8 GW_Routing_PAG_PF
 SG_ Motor_05_CHK : 0|8@1+ (1,0) [0|255] "" Vector__XXX
 SG_ Motor_05_BZ : 8|4@1+ (1,0) [0|15] "" Vector__XXX
 SG_ MO_EKlKomLeiRed : 12|2@1+ (1,0) [0|3] "" Vector__XXX
 SG_ MO_Freig_Reku : 14|2@1+ (1,0) [0|3] "" Vector__XXX
 SG_ MO_Klima_Eingr : 16|2@1+ (1,0) [0|3] ""  Klimakomp_Dash_PAG_PF
 SG_ MO_Status_Normalbetrieb_02 : 18|1@1+ (1,0) [0|1] "" Vector__XXX
 SG_ MO_Schaltbeeinfl_Leistungsbegr : 19|1@1+ (1,0) [0|1] "" Vector__XXX
 SG_ MO_Schaltbeeinfl_Partikelfilter : 20|1@1+ (1,0) [0|1] "" Vector__XXX
 SG_ MO_Prio_MIN_Wunschdrehzahl : 21|1@1+ (1,0) [0|1] "" Vector__XXX
 SG_ MO_Freig_Anlass : 22|1@1+ (1,0) [0|1] "" Vector__XXX
 SG_ MO_Aussp_Anlass : 23|1@1+ (1,0) [0|1] "" Vector__XXX
 SG_ MO_MAX_Wunschdrehzahl : 24|9@1+ (25,0) [0|12750] "Unit_MinutInver"  Kombi_PAG_PF
 SG_ MO_Prio_MAX_Wunschdrehzahl : 33|1@1+ (1,0) [0|1] "" Vector__XXX
 SG_ MO_Luftpfad_aktiv : 34|1@1+ (1,0) [0|1] "" Vector__XXX
 SG_ MO_v_Begrenz_Aktiv : 35|1@1+ (1,0) [0|1] "" Vector__XXX
 SG_ MO_v_Begrenz_Aktivierbar : 36|1@1+ (1,0) [0|1] "" Vector__XXX
 SG_ MO_Verbot_EKP : 37|1@1+ (1,0) [0|1] "" Vector__XXX
 SG_ MO_Anf_Pruefimpuls : 38|1@1+ (1,0) [0|1] "" Vector__XXX
 SG_ MO_Anf_KL75 : 39|1@1+ (1,0) [0|1] "" Vector__XXX
 SG_ MO_Charisma_FahrPr : 40|3@1+ (1,0) [0|7] "" Vector__XXX
 SG_ MO_Charisma_Status : 43|2@1+ (1,0) [0|3] "" Vector__XXX
 SG_ MO_Charisma_Umschaltung : 45|2@1+ (1,0) [0|3] "" Vector__XXX
 SG_ MO_Handshake_STH : 47|1@1+ (1,0) [0|1] "" Vector__XXX
 SG_ MO_MIN_Wunschdrehzahl : 48|8@1+ (25,0) [0|6350] "Unit_MinutInver" Vector__XXX
 SG_ MO_Drehzahlbeeinflussung : 56|8@1+ (0.39,0) [0|99.45] "Unit_PerCent" Vector__XXX

BO_ 1088 Motor_06: 8 GW_Routing_PAG_PF
 SG_ MO_Kuehlerluefter_MUX M : 0|1@1+ (1,0) [0|1] "" Vector__XXX
 SG_ MO_Kuehlerluefter_1 m0 : 1|7@1+ (1,0) [0|100] "Unit_PerCent" Vector__XXX
 SG_ MO_Kuehlerluefter_2 m1 : 1|7@1+ (1,0) [0|100] "Unit_PerCent" Vector__XXX
 SG_ MO_HYB_Status_HV_Ladung : 8|3@1+ (1,0) [0|7] "" Vector__XXX
 SG_ MO_ITM_Warnung_Pumpe : 11|1@1+ (1,0) [0|1] "" Vector__XXX
 SG_ WIV_Anzeige_aktiv : 12|1@1+ (1,0) [0|1] "" Vector__XXX
 SG_ WIV_Oelmin_Warn : 13|1@1+ (1,0) [0|1] ""  Kombi_PAG_PF
 SG_ WIV_Sensorfehler : 14|1@1+ (1,0) [0|1] ""  Kombi_PAG_PF
 SG_ WIV_Schieflage : 15|1@1+ (1,0) [0|1] "" Vector__XXX
 SG_ WIV_Oelstand : 16|4@1+ (12.5,0) [0|100] "Unit_PerCent"  Kombi_PAG_PF
 SG_ MO_Zustand_HWP : 20|2@1+ (1,0) [0|3] "" Vector__XXX
 SG_ MO_Kat_Warnung : 22|1@1+ (1,0) [0|1] "" Vector__XXX
 SG_ WIV_Oelsystem_aktiv : 24|1@1+ (1,0) [0|1] ""  Kombi_PAG_PF
 SG_ WIV_nicht_betriebswarm : 25|1@1+ (1,0) [0|1] "" Vector__XXX
 SG_ WIV_Ueberfuell_Warn : 26|1@1+ (1,0) [0|1] ""  Kombi_PAG_PF
 SG_ WIV_laufender_Motor : 27|1@1+ (1,0) [0|1] "" Vector__XXX
 SG_ MO_HYB_Text_1 : 28|1@1+ (1,0) [0|1] ""  Kombi_PAG_PF
 SG_ MO_HYB_Text_2 : 29|1@1+ (1,0) [0|1] ""  Kombi_PAG_PF
 SG_ MO_HYB_Text_3 : 30|1@1+ (1,0) [0|1] ""  Kombi_PAG_PF
 SG_ MO_HYB_Text_4 : 31|1@1+ (1,0) [0|1] ""  ADR_PAG_X2,Kombi_PAG_PF
 SG_ MO_Text_Motorstart : 32|4@1+ (1,0) [0|15] "" Vector__XXX
 SG_ MO_HYB_Text_5 : 36|1@1+ (1,0) [0|1] ""  Kombi_PAG_PF
 SG_ MO_HYB_Text_6 : 37|1@1+ (1,0) [0|1] ""  Kombi_PAG_PF
 SG_ MO_HYB_Text_7 : 38|1@1+ (1,0) [0|1] ""  Kombi_PAG_PF
 SG_ WIV_Oeldyn_avl : 39|1@1+ (1,0) [0|1] "" Vector__XXX
 SG_ MO_Text_MSG_Werkstatt : 40|1@1+ (1,0) [0|1] ""  Kombi_PAG_PF
 SG_ MO_Text_Partikelfil_Reg : 41|1@1+ (1,0) [0|1] "" Vector__XXX
 SG_ MO_Text_Fehler_Kraftstoffsys : 42|1@1+ (1,0) [0|1] "" Vector__XXX
 SG_ WIV_Oelmenge : 43|5@1+ (125,0) [0|3875] "Unit_MilliLiter" Vector__XXX
 SG_ MO_Systemlampe : 48|1@1+ (1,0) [0|1] "" Vector__XXX
 SG_ MO_OBD2_Lampe : 49|1@1+ (1,0) [0|1] ""  Kombi_PAG_PF
 SG_ MO_Heissleuchte : 50|1@1+ (1,0) [0|1] ""  Kombi_PAG_PF
 SG_ MO_Partikel_Lampe : 51|1@1+ (1,0) [0|1] "" Vector__XXX
 SG_ MO_Winterfahrprog : 52|1@1+ (1,0) [0|1] "" Vector__XXX
 SG_ WIV_Oelstand_nicht_vorhanden : 53|1@1+ (1,0) [0|1] ""  Kombi_PAG_PF
 SG_ WIV_nachfuellanzeige_ein : 54|1@1+ (1,0) [0|1] "" Vector__XXX
 SG_ WIV_Ueberfuell_deaktiv : 55|1@1+ (1,0) [0|1] "" Vector__XXX
 SG_ WIV_Unterfuell_Warn : 56|1@1+ (1,0) [0|1] ""  Kombi_PAG_PF
 SG_ MO_Tankdeckel_Lampe : 57|1@1+ (1,0) [0|1] ""  Kombi_PAG_PF
 SG_ MO_Text_Tankdeckelwarn : 58|1@1+ (1,0) [0|1] ""  Kombi_PAG_PF
 SG_ WIV_Enable_Oeldr_Motor : 59|1@1+ (1,0) [0|1] ""  Kombi_PAG_PF
 SG_ WIV_Oeldr_Warn_Motor : 60|1@1+ (1,0) [0|1] ""  Kombi_PAG_PF
 SG_ MO_Avus_Motorschutz : 61|2@1+ (1,0) [0|3] ""  Kombi_PAG_PF
 SG_ MO_HYB_Fahrbereitschaft : 63|1@1+ (1,0) [0|1] ""  Kombi_PAG_PF

BO_ 1600 Motor_07: 8 GW_Routing_PAG_PF
 SG_ MO_QBit_Ansaugluft_Temp : 0|1@1+ (1,0) [0|1] "" Vector__XXX
 SG_ MO_QBit_Oel_Temp : 1|1@1+ (1,0) [0|1] ""  Kombi_PAG_PF
 SG_ MO_QBit_Kuehlmittel_Temp : 2|1@1+ (1,0) [0|1] ""  Kombi_PAG_PF
 SG_ MO_HYB_Fehler_HV_Netz : 4|1@1+ (1,0) [0|1] "" Vector__XXX
 SG_ MO_aktives_Getriebeheizen : 5|1@1+ (1,0) [0|1] "" Vector__XXX
 SG_ MO_Absperrventil_oeffnen : 6|2@1+ (1,0) [0|3] ""  Klima_PAG_PF
 SG_ MO_Ansaugluft_Temp : 8|8@1+ (0.75,-48) [-48|141.75] "Unit_DegreCelsi" Vector__XXX
 SG_ MO_Oel_Temp : 16|8@1+ (1,-60) [-60|192] "Unit_DegreCelsi"  Kombi_PAG_PF
 SG_ MO_Kuehlmittel_Temp : 24|8@1+ (0.75,-48) [-48|141.75] "Unit_DegreCelsi"  Kombi_PAG_PF
 SG_ MO_Hoeheninfo : 32|8@1+ (0.00781,0) [0|1.98374] "" Vector__XXX
 SG_ MO_Kennfeldk : 40|1@1+ (1,0) [0|1] "" Vector__XXX
 SG_ MO_Versionsinfo : 41|6@1+ (1,0) [0|63] "" Vector__XXX
 SG_ MO_Getriebe_kuehlen : 47|1@1+ (1,0) [0|1] "" Vector__XXX
 SG_ MO_Mom_Traegheit_02 : 48|5@1+ (0.01,0) [0|0.31] "Unit_KiloGramMeterSquar" Vector__XXX
 SG_ MO_Heizungspumpenansteuerung : 53|4@1+ (10,0) [0|100] "Unit_PerCent" Vector__XXX
 SG_ MO_SpannungsAnf : 57|1@1+ (1,0) [0|1] "" Vector__XXX
 SG_ MO_Nachlaufzeit_Heizungspumpe : 58|6@1+ (15,0) [0|945] "Unit_Secon" Vector__XXX

BO_ 933 Motor_15_PAG: 8 GW_Routing_PAG_PF
 SG_ Enrgfluss_State : 0|8@1+ (1,0) [0|255] ""  ADR_PAG_X2,Kombi_PAG_PF
 SG_ Ladezustand : 8|8@1+ (1,0) [0|100] "Unit_PerCent"  ADR_PAG_X2,Kombi_PAG_PF
 SG_ Energiefluss : 16|8@1+ (1,-128) [-100|100] "Unit_PerCent"  Kombi_PAG_PF
 SG_ Enrgrueckfluss : 24|8@1+ (0.2,0) [0|50.8] ""  Kombi_PAG_PF
 SG_ MO_Powermeter : 32|12@1+ (1,0) [0|4092] "" Vector__XXX
 SG_ MO_Overboost : 44|1@1+ (1,0) [0|1] "" Vector__XXX
 SG_ MO_Anf_Abgasklappe : 45|1@1+ (1,0) [0|1] "" Vector__XXX
 SG_ MO_LED_Abgasklappe : 46|1@1+ (1,0) [0|1] ""  Klima_PAG_PF
 SG_ MO_Fehler_MSpG : 47|1@1+ (1,0) [0|1] "" Vector__XXX
 SG_ MO_Temp_MotRaum : 48|6@1+ (3,-48) [-48|141] "Unit_DegreCelsi" Vector__XXX
 SG_ MO_Hoch_Anz_Nmax : 54|1@1+ (1,0) [0|1] ""  Kombi_PAG_PF
 SG_ MO_Hoch_Anz_Eco : 55|1@1+ (1,0) [0|1] ""  Kombi_PAG_PF
 SG_ MO_Oel_Temp_Radsatz : 56|8@1+ (1,-60) [-60|193] "Unit_DegreCelsi" Vector__XXX

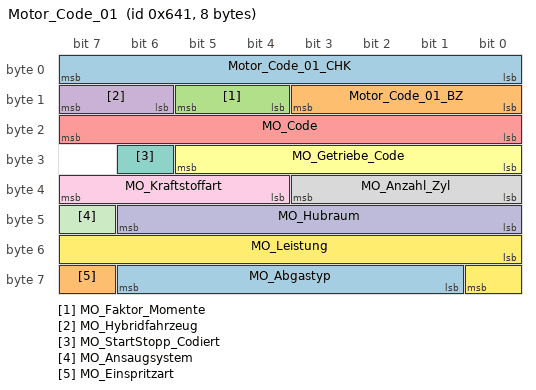
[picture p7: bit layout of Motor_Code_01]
BO_ 1601 Motor_Code_01: 8 GW_Routing_PAG_PF
 SG_ Motor_Code_01_CHK : 0|8@1+ (1,0) [0|255] "" Vector__XXX
 SG_ Motor_Code_01_BZ : 8|4@1+ (1,0) [0|15] "" Vector__XXX
 SG_ MO_Faktor_Momente : 12|2@1+ (1,0) [0|3] "" Vector__XXX
 SG_ MO_Hybridfahrzeug : 14|2@1+ (1,0) [0|3] "" Vector__XXX
 SG_ MO_Code : 16|8@1+ (1,0) [0|255] "" Vector__XXX
 SG_ MO_Getriebe_Code : 24|6@1+ (1,0) [0|63] "" Vector__XXX
 SG_ MO_StartStopp_Codiert : 30|1@1+ (1,0) [0|1] "" Vector__XXX
 SG_ MO_Anzahl_Zyl : 32|4@1+ (1,0) [0|15] "" Vector__XXX
 SG_ MO_Kraftstoffart : 36|4@1+ (1,0) [0|15] "" Vector__XXX
 SG_ MO_Hubraum : 40|7@1+ (0.1,0) [0|12.7] "Unit_Liter" Vector__XXX
 SG_ MO_Ansaugsystem : 47|1@1+ (1,0) [0|1] "" Vector__XXX
 SG_ MO_Leistung : 48|9@1+ (1,0) [0|511] "Unit_KiloWatt" Vector__XXX
 SG_ MO_Abgastyp : 57|6@1+ (1,0) [0|63] "" Vector__XXX
 SG_ MO_Einspritzart : 63|1@1+ (1,0) [0|1] "" Vector__XXX

BO_TX_BU_ 1704 : ADR_PAG_X2,Kombi_PAG_PF;
CM_ SG_ 1706 KBI_STH_Std "Standheizungs- Timer Stunden
";
CM_ SG_ 1706 KBI_STH_Min "Standheizungs- Timer Minuten
";
CM_ SG_ 1706 KBI_STH_TT "Standheizungs- Timer Tag
";
CM_ SG_ 1706 KBI_STH_MM "Standheizungs- Timer Monat
";
CM_ SG_ 1706 KBI_STH_JJ "Standheizungs- Timer Jahr
";
CM_ SG_ 1706 KBI_STH_Status "Standheizungs- Status
";
CM_ SG_ 1706 KBI_STH_Timer_Status "Standheizung Timer Status
";
CM_ SG_ 1706 KBI_STH_Betriebsdauer "Betriebsdauer der Standheizung
Audi-Format:
15, 30, 45, 60 MIN
Gateway sendet das Signal an STH
";
CM_ SG_ 1706 KBI_Menu1_Pos1 "Funktion 1 im Menü 1 durch Kunde gewählt/ nicht gewählt ";
CM_ SG_ 1706 KBI_Menu1_Pos2 "Funktion 2 im Menü 1 durch Kunde gewählt/nicht gewählt ";
CM_ SG_ 1706 KBI_Menu1_Pos3 "Funktion 3 im Menü 1 durch Kunde gewählt/nicht gewählt ";
CM_ SG_ 1706 KBI_Menu1_Pos4 "Funktion 4 im Menü 1 durch Kunde gewählt/nicht gewählt ";
CM_ SG_ 1706 KBI_Menu1_Pos5 "Funktion 5 im Menü 1 durch Kunde gewählt/nicht gewählt ";
CM_ SG_ 1706 KBI_Menu1_Pos6 "Funktion 6 im Menü 1 durch Kunde gewählt/nicht gewählt ";
CM_ SG_ 1706 KBI_Menu1_Pos7 "Funktion 7 im Menü 1 durch Kunde gewählt/nicht gewählt ";
CM_ SG_ 1706 KBI_Menu1_Pos8 "Funktion 8 im Menü 1 durch Kunde gewählt/nicht gewählt ";
CM_ SG_ 1706 KBI_Menu2_Pos1 "Funktion 1 im Menü 2 durch Kunde gewählt/nicht gewählt ";
CM_ SG_ 1706 KBI_Menu2_Pos2 "Funktion 2 im Menü 2 durch Kunde gewählt/nicht gewählt ";
CM_ SG_ 1706 KBI_Menu2_Pos3 "Funktion 3 im Menü 2 durch Kunde gewählt/nicht gewählt ";
CM_ SG_ 1706 KBI_Menu2_Pos4 "Funktion 4 im Menü 2 durch Kunde gewählt/nicht gewählt ";
CM_ SG_ 1706 KBI_Menu2_Pos5 "Funktion 5 im Menü 2 durch Kunde gewählt/nicht gewählt ";
CM_ SG_ 1706 KBI_Menu2_Pos6 "Funktion 6 im Menü 2 durch Kunde gewählt/nicht gewählt ";
CM_ SG_ 1706 KBI_Menu2_Pos7 "Funktion 7 im Menü 2 durch Kunde gewählt/nicht gewählt ";
CM_ SG_ 1706 KBI_Menu2_Pos8 "Funktion 8 im Menü 2 durch Kunde gewählt/nicht gewählt ";
CM_ SG_ 1706 KBI_Menu3_Pos1 "Funktion 1 im Menü 3 durch Kunde gewählt/nicht gewählt ";
CM_ SG_ 1706 KBI_Menu3_Pos2 "Funktion 2 im Menü 3 durch Kunde gewählt/nicht gewählt ";
CM_ SG_ 1706 KBI_Menu3_Pos3 "Funktion 3 im Menü 3 durch Kunde gewählt/nicht gewählt ";
CM_ SG_ 1706 KBI_Menu3_Pos4 "Funktion 4 im Menü 3 durch Kunde gewählt/nicht gewählt ";
CM_ SG_ 1706 KBI_Menu3_Pos5 "Funktion 5 im Menü 3 durch Kunde gewählt/nicht gewählt ";
CM_ SG_ 1706 KBI_Menu3_Pos6 "Funktion 6 im Menü 3 durch Kunde gewählt/nicht gewählt ";
CM_ SG_ 1706 KBI_Menu3_Pos7 "Funktion 7 im Menü 3 durch Kunde gewählt/nicht gewählt ";
CM_ SG_ 1706 KBI_Menu3_Pos8 "Funktion 8 im Menü 3 durch Kunde gewählt/nicht gewählt ";
CM_ SG_ 282 KBI_GZeit_HSek "Stoppuhr-Gesamtzeit laufend - 1/100 Sekunden
";
CM_ SG_ 282 KBI_GZeit_Sek "Stoppuhr-Gesamtzeit laufend - Sekunden
";
CM_ SG_ 282 KBI_GZeit_Min "Stoppuhr-Gesamtzeit laufend Minuten
";
CM_ SG_ 282 KBI_GZeit_Std "Stoppuhr-Gesamtzeit laufend - Stunden
";
CM_ SG_ 282 KBI_St_SU "Status Stoppuhr laeuft/steht
0: Stoppuhr steht
1: Stoppuhr laeuf
";
CM_ SG_ 282 KBI_Uhrzeit_SU "Uhrzeitanzeige in der Uhr (Mittelkonsole)
(1=Bedingungen im Kombi (kein SportChrono-Menue / Uhr-Anzeige) sind erfüllt)
";
CM_ SG_ 282 KBI_Reichw_anz "Reichweite angezeigt";
CM_ SG_ 282 KBI_E_Restreichweite "Elektrische Restreichweite, die dem Fahrer angezeigt wird";
CM_ SG_ 282 KBI_Uhrzeit_Kompass "Uhrzeitanzeige im Kompass";
CM_ SG_ 1331 KBI_RZ_Nr "Nr. der aktuellen Runde
";
CM_ SG_ 1331 KBI_ZZ_Nr "Nr. der letzten Zwischenzeit
";
CM_ SG_ 1331 KBI_ZZeit_Std "Stoppuhr - Zwischenzeit - Stunden";
CM_ SG_ 1331 KBI_ZZeit_Min "Stoppuhr - Zwischenzeit - Minuten
";
CM_ SG_ 1331 KBI_ZZeit_Sek "Stoppuhr - Zwischenzeit - Sekunden
";
CM_ SG_ 1331 KBI_ZZeit_HSek "Stoppuhr - Zwischenzeit - 1/100 Sekunden
";
CM_ SG_ 1331 KBI_Chrono_Akt "Chrono aktiv
";
CM_ SG_ 1331 KBI_Trip_Reset_Min "Uhrzeit Minuten, zu welcher der Trip-Satz 2 (Kurzzeit) zurückgesetzt wurde.";
CM_ SG_ 1331 KBI_Trip_Reset_Std "Uhrzeit Stunden, zu welcher der Trip-Satz 2 (Kurzzeit) zurückgesetzt wurde.";
CM_ SG_ 1329 KBI_RZeit_HSek "Stoppuhr -Rundenzeit - 1/100 Sekunden";
CM_ SG_ 1329 KBI_RZeit_Min "Stoppuhr - Rundenzeit - Minuten
";
CM_ SG_ 1329 KBI_RZeit_Sek "Stoppuhr - Rundenzeit - Sekunden
";
CM_ SG_ 1329 KBI_RZeit_Std "Stoppuhr - Rundenzeit - Stunden";
CM_ SG_ 1329 KBI_St_Disp "Kombi Displaystatus
";
CM_ SG_ 1329 KBI_lRZeit_HSek "Stoppuhr - letzte Rundenzeit (statisch) - 1/100 Sekunden";
CM_ SG_ 1329 KBI_lRZeit_Min "Stoppuhr - letzte Rundenzeit (statisch) - Minuten
";
CM_ SG_ 1329 KBI_lRZeit_Sek "Stoppuhr - letzte Rundenzeit (statisch) - Sekunden
";
CM_ SG_ 1329 KBI_lRZeit_Std "Stoppuhr - letzte Rundenzeit (statisch) - Stunden
";
CM_ SG_ 922 KBI_Trip_DS_Verbr_1 "Trip-Daten(fortlaufend): Durchschnittsverbrauch
fortlaufender Satz. 0x3FFF = Wert ungueltig (Keine Fehlerspeicherung!) 

";
CM_ SG_ 922 KBI_Trip_Min_1 "Trip-Daten(fortlaufend): Minuten
";
CM_ SG_ 922 KBI_Trip_Std_1 "Trip-Daten(fortlaufend): Stunden
";
CM_ SG_ 922 KBI_Trip_Strecke_1 "Trip-Daten(fortlaufend): Wegstrecke
fortlaufender Satz. 0x1FFFF = Wert ungueltig (Keine Fehlerspeicherung!) 
";
CM_ SG_ 922 KBI_Trip_DS_V_1 "Trip-Daten(fortlaufend): Durchschnittsgeschwindigkeit
fortlaufender Satz. 0x1FF = Wert ungueltig (Keine Fehlerspeicherung!) ";
CM_ SG_ 923 KBI_Trip_DS_Verbr_2 "Trip-Daten(seit): Durchschnittsverbrauch
Kurzzeitzähler / Fahrdaten seit hh::mm ; 0x3FFF = Wert ungueltig (Keine Fehlerspeicherung!) ";
CM_ SG_ 923 KBI_Trip_Min_2 "Trip-Daten(seit): Minuten
";
CM_ SG_ 923 KBI_Trip_Std_2 "Trip-Daten(seit): Stunden
";
CM_ SG_ 923 KBI_Trip_Strecke_2 "Trip-Daten(seit): Wegstrecke
Kurzzeitzähler / Fahrdaten seit hh::mm ; 0x1FFFF = Wert ungueltig (Keine Fehlerspeicherung!) ";
CM_ SG_ 923 KBI_Trip_DS_V_2 "Trip-Daten(seit): Durchschnittsgeschwindigkeit
Kurzzeitzähler / Fahrdaten seit hh::mm ; 0x1FF = Wert ungueltig (Keine Fehlerspeicherung!) ";
CM_ SG_ 1534 KBI_Set_Timer_MUX "Multiplexor zur Anzeige des aktuell übertragenden und zu setzenden Timers";
CM_ SG_ 1534 KBI_Set_Timer_1_Jahr "Status Timer 1 gesetztes Datum -> Jahr";
CM_ SG_ 1534 KBI_Set_Timer_2_Jahr "Status Timer 2 gesetztes Datum -> Jahr";
CM_ SG_ 1534 KBI_Set_Timer_3_Jahr "Status Timer 3 gesetztes Datum -> Jahr";
CM_ SG_ 1534 KBI_Set_Timer_4_Jahr "Status Timer 4 gesetztes Datum -> Jahr";
CM_ SG_ 1534 KBI_Set_Timer_1_Minute "Status Timer 1 gesetztes Datum -> Minute";
CM_ SG_ 1534 KBI_Set_Timer_2_Minute "Status Timer 2 gesetztes Datum -> Minute";
CM_ SG_ 1534 KBI_Set_Timer_3_Minute "Status Timer 3 gesetztes Datum -> Minute";
CM_ SG_ 1534 KBI_Set_Timer_4_Minute "Status Timer 4 gesetztes Datum -> Minute";
CM_ SG_ 1534 KBI_Set_Timer_1_Monat "Status Timer 1 gesetztes Datum -> Monat";
CM_ SG_ 1534 KBI_Set_Timer_2_Monat "Status Timer 2 gesetztes Datum -> Monat";
CM_ SG_ 1534 KBI_Set_Timer_3_Monat "Status Timer 3 gesetztes Datum -> Monat";
CM_ SG_ 1534 KBI_Set_Timer_4_Monat "Status Timer 4 gesetztes Datum -> Monat";
CM_ SG_ 1534 KBI_Set_Timer_1_Stunde "Status Timer 1 gesetztes Datum -> Stunde";
CM_ SG_ 1534 KBI_Set_Timer_2_Stunde "Status Timer 2 gesetztes Datum -> Stunde";
CM_ SG_ 1534 KBI_Set_Timer_3_Stunde "Status Timer 3 gesetztes Datum -> Stunde";
CM_ SG_ 1534 KBI_Set_Timer_4_Stunde "Status Timer 4 gesetztes Datum -> Stunde";
CM_ SG_ 1534 KBI_Set_Timer_1_Tag "Status Timer 1 gesetztes Datum -> Tag";
CM_ SG_ 1534 KBI_Set_Timer_2_Tag "Status Timer 2 gesetztes Datum -> Tag";
CM_ SG_ 1534 KBI_Set_Timer_3_Tag "Status Timer 3 gesetztes Datum -> Tag";
CM_ SG_ 1534 KBI_Set_Timer_4_Tag "Status Timer 4 gesetztes Datum -> Tag";
CM_ SG_ 1534 KBI_Set_Timer_1_Laden "Setzen des Ladetimers 1";
CM_ SG_ 1534 KBI_Set_Timer_2_Laden "Setzen des Ladetimers 2";
CM_ SG_ 1534 KBI_Set_Timer_3_Laden "Setzen des Ladetimers 3";
CM_ SG_ 1534 KBI_Set_Timer_4_Laden "Setzen des Ladetimers 4";
CM_ SG_ 1534 KBI_Set_Timer_1_Vorklima "Setzen des Vorklimatisierungs-Timers 1";
CM_ SG_ 1534 KBI_Set_Timer_2_Vorklima "Setzen des Vorklimatisierungs-Timers 2";
CM_ SG_ 1534 KBI_Set_Timer_3_Vorklima "Setzen des Vorklimatisierungs-Timers 3";
CM_ SG_ 1534 KBI_Set_Timer_4_Vorklima "Setzen des Vorklimatisierungs-Timers 4";
CM_ SG_ 1534 KBI_Set_Timer_1_Zyklus_Mo "Timer 1 für Wochentag gesetzt";
CM_ SG_ 1534 KBI_Set_Timer_2_Zyklus_Mo "Timer 2 für Wochentag gesetzt";
CM_ SG_ 1534 KBI_Set_Timer_3_Zyklus_Mo "Timer 3 für Wochentag gesetzt";
CM_ SG_ 1534 KBI_Set_Timer_4_Zyklus_Mo "Timer 4 für Wochentag gesetzt";
CM_ SG_ 1534 KBI_Set_Timer_1_Zyklus_Di "Timer 1 für Wochentag gesetzt";
CM_ SG_ 1534 KBI_Set_Timer_2_Zyklus_Di "Timer 2 für Wochentag gesetzt";
CM_ SG_ 1534 KBI_Set_Timer_3_Zyklus_Di "Timer 3 für Wochentag gesetzt";
CM_ SG_ 1534 KBI_Set_Timer_4_Zyklus_Di "Timer 4 für Wochentag gesetzt";
CM_ SG_ 1534 KBI_Set_Timer_1_Zyklus_Mi "Timer 1 für Wochentag gesetzt";
CM_ SG_ 1534 KBI_Set_Timer_2_Zyklus_Mi "Timer 2 für Wochentag gesetzt";
CM_ SG_ 1534 KBI_Set_Timer_3_Zyklus_Mi "Timer 3 für Wochentag gesetzt";
CM_ SG_ 1534 KBI_Set_Timer_4_Zyklus_Mi "Timer 4 für Wochentag gesetzt";
CM_ SG_ 1534 KBI_Set_Timer_1_Zyklus_Do "Timer 1 für Wochentag gesetzt";
CM_ SG_ 1534 KBI_Set_Timer_2_Zyklus_Do "Timer 2 für Wochentag gesetzt";
CM_ SG_ 1534 KBI_Set_Timer_3_Zyklus_Do "Timer 3 für Wochentag gesetzt";
CM_ SG_ 1534 KBI_Set_Timer_4_Zyklus_Do "Timer 4 für Wochentag gesetzt";
CM_ SG_ 1534 KBI_Set_Timer_1_Zyklus_Fr "Timer 1 für Wochentag gesetzt";
CM_ SG_ 1534 KBI_Set_Timer_2_Zyklus_Fr "Timer 2 für Wochentag gesetzt";
CM_ SG_ 1534 KBI_Set_Timer_3_Zyklus_Fr "Timer 3 für Wochentag gesetzt";
CM_ SG_ 1534 KBI_Set_Timer_4_Zyklus_Fr "Timer 4 für Wochentag gesetzt";
CM_ SG_ 1534 KBI_Set_Timer_1_Zyklus_Sa "Timer 1 für Wochentag gesetzt";
CM_ SG_ 1534 KBI_Set_Timer_2_Zyklus_Sa "Timer 2 für Wochentag gesetzt";
CM_ SG_ 1534 KBI_Set_Timer_3_Zyklus_Sa "Timer 3 für Wochentag gesetzt";
CM_ SG_ 1534 KBI_Set_Timer_4_Zyklus_Sa "Timer 4 für Wochentag gesetzt";
CM_ SG_ 1534 KBI_Set_Timer_1_Zyklus_So "Timer 1 für Wochentag gesetzt";
CM_ SG_ 1534 KBI_Set_Timer_2_Zyklus_So "Timer 2 für Wochentag gesetzt";
CM_ SG_ 1534 KBI_Set_Timer_3_Zyklus_So "Timer 3 für Wochentag gesetzt";
CM_ SG_ 1534 KBI_Set_Timer_4_Zyklus_So "Timer 4 für Wochentag gesetzt";
CM_ SG_ 1534 KBI_Set_Timer_1_Zyklus_WH "Timer 1 ist zur einmaligen Auslösung gestezt oder wiederholt sich";
CM_ SG_ 1534 KBI_Set_Timer_2_Zyklus_WH "Timer 2 ist zur einmaligen Auslösung gestezt oder wiederholt sich";
CM_ SG_ 1534 KBI_Set_Timer_3_Zyklus_WH "Timer 3 ist zur einmaligen Auslösung gestezt oder wiederholt sich";
CM_ SG_ 1534 KBI_Set_Timer_4_Zyklus_WH "Timer 4 ist zur einmaligen Auslösung gestezt oder wiederholt sich";
CM_ SG_ 1535 KBI_Trip_E_Min "Trip-Daten(seit): Minuten
";
CM_ SG_ 1535 KBI_Trip_E_Std "Trip-Daten(seit): Stunden
";
CM_ SG_ 1535 KBI_Service_km "Anzeige der verbleibenden km bis zum nächsten Service
";
CM_ SG_ 1535 KBI_Service_Typ "Anzeige, ob nächster Service eine Zwischen-, Hauptwartung oder ein Ölservice ist
";
CM_ SG_ 1535 KBI_Service_Zeit "Anzeige der verbleibenden Zeit bis zum nächsten Service
";
CM_ SG_ 1343 KBI_Trip_E_Verbr_fortl "Elektrischer Durchschnittsverbrauch seit Rücksetzen, die dem Fahrer angezeigt wird";
CM_ SG_ 1343 KBI_Trip_E_Verbr_seit "Elektrischer Durchschnittsverbrauch seit Kl.15 EIN, die dem Fahrer angezeigt wird";
CM_ SG_ 1343 KBI_Trip_E_Strecke_fortl "zurückgelegte Strecke elektrisch seit Rücksetzen, die dem Fahrer angezeigt wird";
CM_ SG_ 1343 KBI_Trip_E_Strecke_seit "zurückgelegte STrecke elektrisch seit Kl.15 EIN, die dem Fahrer angezeigt wird";
CM_ SG_ 1662 LAD_02_CHK "Berechnung siehe Konzern-Lastenheft A-CAN V4.2a
Checksummenendwert = 0x00";
CM_ SG_ 1662 LAD_02_BZ "freilaufender Botschaftszähler";
CM_ SG_ 1662 LAD_Abregelung_Temperatur "Abregelung aufgrund interner Übertemperatur im Ladegerät";
CM_ SG_ 1662 LAD_Abregelung_IU_Ein_Aus "Abregelung aufgrund Strom oder Spannung am Eingang oder Ausgang";
CM_ SG_ 1662 LAD_Abregelung_BuchseTemp "Reduzierung aufgrund zu hoher Temperatur der Ladebuchse";
CM_ SG_ 1662 LAD_MaxLadLeistung_HV "Maximale Leistung Ladegerät bezogen auf die maximale Leistung Infrastruktur (Kabel, Ladestation) und Berücksichtigung des Ladegerät-Wirkungsgrades";
CM_ SG_ 1662 LAD_CP_Stromlimit "AC-Stromlimit aufgrund des CP Duty Cycles";
CM_ SG_ 1662 LAD_PRX_Stromlimit "AC-Stromlimit aufgrund der PRX Kabelkodierung";
CM_ SG_ 1662 LAD_CP_Erkennung "Status Control Pilot Überwachung (Erkennung des Control Pilot Duty-Cycles)";
CM_ SG_ 1662 LAD_Stecker_Verriegelt "Status Steckerverriegelung (Rücklesekontakt des Verrieglungsaktors)";
CM_ SG_ 1662 LAD_Stecker_Gesteckt "Status Steckererkennung";
CM_ SG_ 1662 LAD_Kuehlbedarf "Kühlbedarf des Ladegerätes";
CM_ SG_ 1662 LAD_Warnzustand "Sammelwarnung Ladegerät
0 keine Warnbedingung aktiv
1 Warnbedingung aktiv, evtl. eingeschränkte Leistungsfähigkeit";
CM_ SG_ 1662 LAD_Fehlerzustand "Sammelfehler Ladegerät - kein Laden möglich";
CM_ SG_ 810 EPS_01_CRC "Für MLB:
'Berechnung siehe Lastenheft 'Kommunikationsabsicherung für FlexRay und CAN''

Ab MQB und MLBevo:
'Berechnung siehe Lastenheft 'End-to-End Kommunikationsabsicherung''

Endwerte siehe Begleitdokument 'S-PDU Kennungsfolgen'
";
CM_ SG_ 810 EPS_SpannungsAnf "Forderung des EPS-SG's zur Spannungsanhebung.";
CM_ SG_ 810 EPS_Akustiksignal "Ansteuerung eines Akustiksignals im Kombi";
CM_ SG_ 810 EPS_Fehlerlampe "Steuert direkt die Fehlerlampe Lenkhilfe (gelb); kein Aufprüfen bei Neustart, keine Rückleseinformation in Kombi-Botschaft (nur für VW526 Hybrid)";
CM_ SG_ 810 EPS_Warnungen "Diese Bits werden verwendet, um im Kombi Texte, Lampen oder Bilder für die Lenkhilfe darzustellen
Audi:
Text_1: Lenkung defekt (Prio 1)
Text_2: Lenkung Systemstörung (Prio 2)
VW526:
Text_1 (ID_TXT_1026.1): Ausfall Lenkunterstützung
Text_2 (ID_TXT_10";
CM_ SG_ 810 EPS_PLA_Abbruch "Art des Fehlers ohne Eintrag, 16 Werte möglich (siehe LH EPS/PLA)";
CM_ SG_ 810 EPS_PLA_Fehler "Art des Fehlers ohne Eintrag, 16 Werte möglich (siehe LH EPS/PLA)";
CM_ SG_ 810 EPS_PLA_Status "16 Statuswerte (siehe LH PLA/EPS)";
CM_ SG_ 810 EPS_Charisma_FahrPr "Rückmeldung des aktuellen Charisma-Status der EPS";
CM_ SG_ 810 EPS_Charisma_Status "Rückmeldung an den Charisma-Master

Wert 0x3 ist nur für Fahrzeuge ab MQB relevant";
CM_ SG_ 810 EPS_Charisma_Umschaltung "Rückmeldung an den Charisma-Master";
CM_ SG_ 810 EPS_Lenkerposition "Position des Lenkers im Fahrzeug";
CM_ SG_ 810 EPS_Anf_KL "Nach Überschreiten einer oberen Grenztemperatur innerhalb des Steuergerätes der Lenkhilfe fordert die EPS die Zuschaltung einer externen Kühlung durch den Kühlerlüfter an.
Es besteht kein technischer Zusammenhang mit einer Batterie_ab - Erkennung in der ";
CM_ BO_ 1137 "MLB";
CM_ SG_ 1137 Licht_hinten_01_BZ "überlaufender 4bit Botschaftszaehler; wird in jeder Sendebotschaft inkrementiert";
CM_ SG_ 1137 BCM2_Bremsl_durch_ECD "Bremslicht (ECD-Bremsung)
";
CM_ SG_ 1137 LH_Aussenlicht_def "Aussenlicht kann nicht mehr korrekt angesteuert werden (EEPROM Codierung kann nicht mehr ausgelesen werden)
";
CM_ SG_ 1137 LH_Standlicht_H_aktiv "Standlicht hinten
";
CM_ SG_ 1137 LH_Parklicht_HL_aktiv "Parklicht hinten links 
";
CM_ SG_ 1137 LH_Parklicht_HR_aktiv "Parklicht hinten rechts 
";
CM_ SG_ 1137 LH_Bremslicht_H_aktiv "Bremslicht hinten
";
CM_ SG_ 1137 LH_Nebelschluss_aktiv "Nebelschlusslicht
";
CM_ SG_ 1137 LH_Rueckfahrlicht_aktiv "Rueckfahrlicht
";
CM_ SG_ 1137 LH_Blinker_HL_akt "Blinker hinten links
";
CM_ SG_ 1137 LH_Blinker_HR_akt "Blinker hinten rechts
";
CM_ SG_ 1137 LH_Blinker_li_def "Fehlerstatus Blinker hinten links
";
CM_ SG_ 1137 LH_Bremsl_li_def "Fehlerstatus Bremslicht hinten links (Detektion Einzelausfall)
";
CM_ SG_ 1137 LH_Schlusslicht_li_def "Fehlererkennung Schlusslicht hinten links
";
CM_ SG_ 1137 LH_Rueckf_li_def "Fehlererkennung Rückfahrlicht hinten links
";
CM_ SG_ 1137 LH_Nebel_li_def "Fehlererkennung Nebelschlusslicht hinten links
";
CM_ SG_ 1137 LH_Schluss_Brems_Nebel_li_def "Signal wird gesetzt, wenn eine Unterbrechung oder  ein Kurzschluss am Lampenausgang für Schluss_Brems_Nebelschlusslicht erkannt wird.";
CM_ SG_ 1137 LH_Schluss_Brems_Nebel_re_def "Signal wird gesetzt, wenn eine Unterbrechung oder  ein Kurzschluss am Lampenausgang für Schluss_Brems_Nebelschlusslicht erkannt wird.";
CM_ SG_ 1137 LH_Schluss_Brems_li_def "Konfiguration SL+ BRL + PL links und SL+ BRL  links
";
CM_ SG_ 1137 LH_Schluss_Nebel_li_def "Konfiguration SL + NSL links oder SL + NSL + PL links
";
CM_ SG_ 1137 LH_SL_BRL_BLK_li_def "Konfiguration SL + BRL + BLK links oder SL + BRL + BLK + PL links
";
CM_ SG_ 1137 LH_Brems_Blk_li_def "Konfiguration BRL + BLK links 
";
CM_ SG_ 1137 LH_Blinker_re_def "Fehlerstatus Blinker hinten rechts
";
CM_ SG_ 1137 LH_Bremsl_re_def "Fehlerstatus Bremslicht hinten rechts  (Detektion Einzelausfall)
";
CM_ SG_ 1137 LH_Schlusslicht_re_def "Fehlererkennung Schlusslicht hinten rechts
";
CM_ SG_ 1137 LH_Rueckf_re_def "Fehlererkennung Rückfahrlicht hinten rechts
";
CM_ SG_ 1137 LH_Nebel_re_def "Fehlererkennung Nebelschlusslicht hinten rechts
";
CM_ SG_ 1137 LH_Schluss_Brems_re_def "Konfiguration SL+ BRL + PL rechts und SL+ BRL  rechts
";
CM_ SG_ 1137 LH_Schluss_Nebel_re_def "Konfiguration SL + NSL rechts oder SL + NSL + PL rechts
";
CM_ SG_ 1137 LH_SL_BRL_BLK_re_def "Konfiguration SL + BRL + BLK rechts oder SL + BRL + BLK + PL rechts
";
CM_ SG_ 1137 LH_Brems_Blk_re_def "Konfiguration BRL + BLK rechts
";
CM_ SG_ 1137 LH_Kennzl_def "Fehlerstatus Kennzeichenbeleuchtung hinten
";
CM_ SG_ 1137 LH_3_Bremsl_def "Fehlerstatus 3. Bremsleuchte
";
CM_ SG_ 1137 LH_Nebel_mi_def "Fehlererkennung Nebelschlusslicht hinten Mitte


";
CM_ SG_ 1137 LH_Rueckf_mi_def "Fehlererkennung Rückfahrlicht Mitte
";
CM_ SG_ 1137 LH_Bremsl_li_ges_def "Fehlerstatus Bremslicht hinten links (Detektion Totalausfall)
";
CM_ SG_ 1137 LH_Bremsl_re_ges_def "Fehlerstatus Bremslicht hinten links (Detektion Totalausfall)
";
CM_ SG_ 1321 Lift_Status "Status der Vorderachsanhebung (Lift)";
CM_ SG_ 1321 Lift_Charisma_FahrPr "


";
CM_ SG_ 1321 Lift_Charisma_Status "Systemstatus des Charismateilnehmers

";
CM_ SG_ 1321 Lift_Charisma_Umschaltung "Erkennung Umschaltaufforderung des Charisma-Teilnehmers";
CM_ BO_ 917 "MLB";
CM_ SG_ 917 AFS_Abbiegelicht_li_Anf "Anforderung das Abbiegelicht links einzuschalten";
CM_ SG_ 917 AFS_Abbiegelicht_re_Anf "Anforderung das Abbiegelicht rechts einzuschalten";
CM_ SG_ 917 AFS_Abbiegelicht_Dimm_Anf "Beschreibt ob das Abbiegelicht gedimmt oder hart einschalten werden soll. Dimmkurve ist Empfänger hinterlegt.";
CM_ SG_ 917 AFS_Verfuegbarkeit_GLW "Beschreibt die Verfügbarkeit der Gleitenden Leuchtweite / Fernlichtassistenz - Verfügbarkeit bedeutet, dass die Funktion Gleitende Leuchtweite möglich ist";
CM_ SG_ 917 AFS_Status_adaptive_LV "Gibt den Status der adaptiven Lichtverteilung an";
CM_ SG_ 917 AFS_Fernlicht_li_defekt "Beschreibt ob das Fernlicht des linken Scheinwerfers defekt ist";
CM_ SG_ 917 AFS_Fernlicht_re_defekt "Beschreibt ob das Fernlicht des rechten Scheinwerfers defekt ist";
CM_ SG_ 917 AFS_Fernlicht_Status "Beschreibt ob das Fernlicht aktiv oder inaktiv ist";
CM_ SG_ 917 AFS_Lampe "Status der Fehlerlampe: aktuell anliegender Fehlerzustand des dynamischen oder statischen Kurvenlichtes";
CM_ SG_ 917 LWR_Lampe "Status der Fehlerlampe: aktuell anliegender Fehlerzustand";
CM_ SG_ 917 AFS_Fehlertext "Fehlertext wird im Kombi angezeigt (z.Zt nur bei VW)";
CM_ SG_ 917 AFS_LED_Blinkmode "Lampe soll im Warnfall mit 1Hz blinken, wenn das Bit gesetzt ist (z.Zt nur bei VW)";
CM_ SG_ 917 LWR_Touristenmodus_aktiv "Über MMI sendet BCM1 eine Anforderung Touristenmodus an die LWR. Diese sendet als Rückmeldung an BCM1, dass der Touristenmodus aktiv geschaltet wurde";
CM_ SG_ 917 AFS_Charisma_FahrPr "Aktuelles Fahrprogramm des Charisma-Teilnehmers

Achtung neue Modusnamen (wie im MMI):

0x1 = Komfort = Comfort
0x2 = Dynamik = Auto
0x3 = Sport = Dynamic";
CM_ SG_ 917 AFS_Charisma_Status "Charisma Systemstatus des Charisma-Teilnehmers

Wert 0x3 ist nur für Fahrzeuge ab MQB relevant";
CM_ SG_ 917 AFS_Charisma_Umschaltung "Erkennung  Umschaltaufforderung des Charisma-Teilnehmers";
CM_ SG_ 917 AFS_Allwetterlicht "Status ¿Allwetterlicht¿ - Licht für schlechte Sichtverhältnisse
(bei Defekt -> nicht aktiv)";
CM_ SG_ 917 LWR_Touristenmodus_verbaut "Verfügbarkeit der Touristenfunktion im AFS/LWR-SG.
(Das BCM steuert mit diesem Signal die Einblendung des entsprechenden Menüs)";
CM_ SG_ 917 AFS_adaptive_LV_verbaut "Verfügbarkeit der adaptiven Lichtverteilung im AFS-SG.
(Das BCM steuert mit diesem Signal die Einblendung des entsprechenden Menüs)";
CM_ SG_ 917 LWR_Reisemodus_Texte "Anzeige der eingestellten Verkehrsart bei aktivem Touristenlicht";
CM_ SG_ 917 GLW_Sensor_blockiert "Das Signal zeigt an, dass die Kamera zur Zeit keine Sicht hat. 
Verhalten wie Fernlichassisten. 
Weiterleitung des Signals vom BCM an das KOMBI";
CM_ SG_ 917 LWR_Pos_Schrittmotor "Position des Aktuators in Prozent des maximalen Stellweges; vor dem Initialisierungslauf (Motorstart) wird der Initwert ausgegeben: 
0% : tiefste Stellung (auf Block) des Schrittmotors;
100% : maximaler Verstellweg des Schrittmotors (nicht die Grenze de";
CM_ SG_ 917 LWR_Hoehenwert_VL "Aktueller Höhensensorwert Vorne Links

0x7F = 0 mm";
CM_ SG_ 917 LWR_Hoehenwert_HL "Aktueller Höhensensorwert Hinten Links

0x7F = 0 mm
";
CM_ SG_ 917 AFS_Ersatzlicht_Links "Bei aktivierter Ersatzlichtfunktion wird das Abblendlicht ausgeschaltet und eine Ersatzlichtquelle eingeschaltet (z.Zt. B7)";
CM_ SG_ 917 AFS_Ersatzlicht_Rechts "Bei aktivierter Ersatzlichtfunktion wird das Abblendlicht ausgeschaltet und eine Ersatzlichtquelle eingeschaltet (z.Zt. B7)";
CM_ SG_ 917 LWR_AFS_Grundeinstellung "Grundeinstellung des Abblendlichtes am Lichteinstellkasten im Service oder Bandende mit Tester erfolgt! (auch für das dynamische Kurvernlicht)";
CM_ SG_ 917 LWR_AFS_Parametrisierung "Parametrisierung wählt die Fahrzeugvariante und die AFS-Variante aus";
CM_ SG_ 917 LWR_Initialisierungslauf "Initialisierungslauf der Schrittmotoren, erfolgt defaultmäßig beim Motorstart";
CM_ SG_ 917 LWR_Sicherheitsposition "LWR Sicherheitsposition beider Scheinwerfers";
CM_ SG_ 917 LWR_Modus "Schnelle oder langsame Regelart der LWR";
CM_ SG_ 917 LWR_KD_Fehler "Bei gesetztem Bit ist mindestens ein Kundendienstfehler eingetragen";
CM_ SG_ 1704 KBI_Aussenspiegel_absenken_auto "Automatisches Absenken des Aussenspiegels beim Rückwärtsgang eingelegt
";
CM_ SG_ 1704 KBI_Aussenspiegel_einklapp_auto "Automatisches Einklappen des Ausseinspiegels beim Verreigeln des Fahrzeugs
";
CM_ SG_ 1704 KBI_Schaltpkt_Anz_ein "Schaltpunktanzeige am Multifunktionslenkrad ein/aus
";
CM_ SG_ 1704 KBI_FULL_AFS_Tourist "Basiscodierung wird invertiert
";
CM_ SG_ 1704 KBI_Einstiegshilfe_aktiv "Einstiegshilfe aktiv
";
CM_ SG_ 1704 KBI_Schneekettenmodus_Aktiv "Signal setzt den Status, ob Schneeketten angelegt sind oder nicht. Die (De-)Aktivierung der Funktion wird im Kombi vom Kunden vorgenommen.";
CM_ SG_ 1704 KBI_FLA_GLW_Aktiv "Fernlichtassistent / Gleitende Leuchtweitenregulierung Akiv / Inakiv";
CM_ SG_ 1704 KBI_Dimmung_OriLicht "Dimmung Orientierungslicht 0-100% (vom PCM)
Bei Fehlerwert kein Fehlercode ablegen!

";
CM_ SG_ 1704 KBI_RS_d_akt "Regensensor aktiv (nach Zündung ein)
Voraussetzung: Wischerhebel in Intervallstellung
";
CM_ SG_ 1704 KBI_Nachleucht_IL "Nachleuchtzeit Innenlicht";
CM_ SG_ 1704 KBI_Erw_BelueftFeld "Einstellung Klima Erw. Belüftungsfeld
";
CM_ SG_ 1704 KBI_Auto_Umluft "automatische Umluft
";
CM_ SG_ 1704 KBI_Heckrollo_b_R "Heckrollo absenken bei Rückwärtsfahrt
";
CM_ SG_ 1704 KBI_Nachleucht "Nachleuchtzeit Coming-/Leaving Home Beleuchtung
";
CM_ SG_ 1704 KBI_TFL_akt "Tagfahrlicht aktiv
";
CM_ SG_ 1704 KBI_Heckw_b_R "Heckwischer bei Rückwärtsgang";
CM_ SG_ 1704 KBI_WV_Entr "Wiederverriegelungszeit bei Entriegeln mit Fernbedienung ohne Türöffnung
";
CM_ SG_ 1704 KBI_Tuerentr_T "Türentriegelung bei einem Tastendruck
";
CM_ SG_ 1704 KBI_Carjack "Carjacking Funktion Verriegelung
";
CM_ SG_ 1704 KBI_WV_Entr_Kof "Wiederverriegelungszeit der Türen bei Entriegeln des Kofferraums über Fernbedienung
";
CM_ SG_ 1704 KBI_Automem_Inaktiv "Signal setzt den Status, ob das automatische Memory-Speichern beim Verriegeln des Fahrzeugs aktiv ist oder nicht. Die (De-)Aktivierung der Funktion kann im Kombi vorgenommen werden.";
CM_ SG_ 1704 KBI_Jokerkey_Hupe_Aktiv "Hupe per Jokerkey-Betätigung Aktiv/Inaktiv";
CM_ SG_ 1704 KBI_LDW_aktiv "LDW aktiv
";
CM_ SG_ 1704 KBI_Klimastyles "Einstellung des Klimastyles
";
CM_ SG_ 1704 KBI_Mittenduesentemp "Einstellung Klima Mittenduesentemperatur (-2,-1,0,1,2)
";
CM_ SG_ 1704 KBI_Innenlicht_per_Tuerkontakt "Türkontaktfunktion ein / aus (Licht an/aus)
[Bit steuert Innenlicht bei Tür auf, wenn Funktion im Kombi-Menü freigeschaltet]";
CM_ SG_ 1471 MFL_Tastencode_1 "0x00 = No key pressed / key released
0x01 = Menu
0x02 = Menu Up / Next Screen
0x03 = Menu Down / Previous Screen
0x04 = Up
0x05 = Down
0x06 = Up / Down ThumbWheel
0x07 = OK (ThumbWheel-Button)
0x08 = Cancel / Escape
0x09..0x0F = reserved for furt";
CM_ SG_ 1471 MFL_Tastencode_2 "0x00 = No key pressed / key released
0x01 = Menu
0x02 = Menu Up / Next Screen
0x03 = Menu Down / Previous Screen
0x04 = Up
0x05 = Down
0x06 = Up / Down ThumbWheel
0x07 = OK (ThumbWheel-Button)
0x08 = Cancel / Escape
0x09..0x0F = reserved for furt";
CM_ SG_ 1471 MFL_Variante "Markenspezifische Variantennummer des MFL";
CM_ BO_ 193 "Mittelkonsole - nur 918";
CM_ SG_ 193 Miko_KD_Fehler "Status Kundendienst-Fehlerspeicher";
CM_ SG_ 193 Miko_T_Defrost "Taste Defrost";
CM_ SG_ 193 Miko_T_Auto "Taste Auto";
CM_ SG_ 193 Miko_T_Source "Taste Source";
CM_ SG_ 193 Miko_T_AC_Menue "Taste AC-Menü";
CM_ SG_ 193 Miko_T_Phone "Taste Phone-Menü";
CM_ SG_ 193 Miko_T_Media "Taste Media-Menü";
CM_ SG_ 193 Miko_T_Tuner "Taste Tuner-Menü";
CM_ SG_ 193 Miko_T_Back "Taste Back";
CM_ SG_ 193 Miko_T_Option "Mi_T_Option";
CM_ SG_ 193 Miko_T_Car "Taste Car";
CM_ SG_ 193 Miko_T_Info "Taste Info";
CM_ SG_ 193 Miko_T_Navi "Taste Navi";
CM_ SG_ 193 Miko_T_Umluft "Taste Umluft";
CM_ SG_ 193 Miko_T_AC "Taste AC";
CM_ SG_ 193 Miko_T_Acmax "Taste Acmax";
CM_ SG_ 193 Miko_Volume "Tick/100ms";
CM_ SG_ 193 Miko_Volume_Err "Lautstärkeverstellung Fehler";
CM_ SG_ 193 Miko_Volume_dir "Lautstärke vergrößern / verkleinern";
CM_ SG_ 193 Miko_Volume_press "Push-Funktion Volume-Drehsteller";
CM_ SG_ 193 Miko_MMI "Tick/100ms";
CM_ SG_ 193 Miko_MMI_fast "Menüverstellung im Fast-Mode (z.B. Faktor 2)";
CM_ SG_ 193 Miko_MMI_Err "Menüverstellung Fehler";
CM_ SG_ 193 Miko_MMI_dir "Menü rechts / links, aus/ab";
CM_ SG_ 193 Miko_MMI_press "Push-Funktion Menüdrehsteller";
CM_ SG_ 193 Miko_Clima "Tick/100ms";
CM_ SG_ 193 Miko_Clima_fast "Climaverstellung im Fast-Mode (z.B. Faktor 2)";
CM_ SG_ 193 Miko_Clima_Err "Climaverstellung Fehler";
CM_ SG_ 193 Miko_Clima_dir "Clima rechts / links, auf/ab";
CM_ SG_ 193 Miko_Clima_press "Push-Funktion Clima-Drehsteller";
CM_ SG_ 193 Miko_ADR_Reset "Manueller Reset ADR über Tastendruck Miko";
CM_ SG_ 193 Miko_ADR_UltralongPress "Stromsparmodus Infotainment";
CM_ SG_ 193 Miko_T_Blower "Taste Temperaturr echts";
CM_ SG_ 193 Miko_T_Temp_left "Taste Temperatur links";
CM_ SG_ 193 Miko_T_Temp_right "Taste Temperaturr echts";
CM_ BO_ 126 "Verwendung nur im 918 Spyder";
CM_ SG_ 126 Motor_02_CHK_sek "Berechnung siehe Lastenheft 'Kommunikationsabsicherung für FlexRay und CAN'
Endwerte siehe 'Kommunikationsabsicherung für FlexRay und CAN / Anhang C: Tabelle S-PDU Kennungen' Botschaft 'Motor_02'";
CM_ SG_ 126 MO_Faktor_Momente_sek "Dieses Bit schaltet den Wertebereich aller Momente vom Motor, Getriebe, TSK, ESP ... um! Die Momente besitzen somit einen variablen Wertebereich, weil sich durch den Faktor die Momente sowohl in Auflösung als auch Maximalwerten ändert.

Faktor für Momen";
CM_ SG_ 126 Enrgfluss_State_BN "Anzeige des Energiefluss zum Bordnetz";
CM_ SG_ 126 Enrgfluss_State_sek "Anzeige des Energiefluss an der zweiten, elektrisch angetriebenen Achse";
CM_ SG_ 126 MO_Mom_Soll_sek "Achtung:
Einheitenloser CAN-Wert.
Faktor in Motor_02_sek:MO_Faktor_Momente_sek beachten!

Sollmoment ohne P und D Anteil des Leerlaufreglers, ohne Antiruckelfunktion und ohne Getriebeeingriff";
CM_ SG_ 126 MO_Mom_Ist_sek "Achtung:
Einheitenloser CAN-Wert.
Faktor in Motor_02_sek:MO_Faktor_Momente_sek beachten!

Istmoment ohne P und D Anteil des Leerlaufreglers, ohne Antiruckelfunktion und ohne Getriebeeingriff";
CM_ SG_ 126 MO_Faktor_Getriebe "Anteil der Momentenaufteilung für Getriebe";
CM_ SG_ 263 MO_rel_Ladedruck "relativer Ladedruck (für Boostanzeige)";
CM_ SG_ 263 MO_Istgang "Aktueller Gang für Anzeige Hochschaltempfehlung (gültig, wenn MO_Schaltempf_verfbar = 1).

Anzeige im Kombi:
Sollgang == Istgang         ==> Anzeige Istgang
Sollgang !=   Istgang         ==> Schaltempfehlung
Sollgang == Istgang == 0 ==> keine Anzeige";
CM_ SG_ 263 MO_Sollgang "Motor sendet den Sollgang in den der Fahrer schalten soll. Wird im Kombi als Hochschaltempfehlung hervorgehoben (gültig, wenn MO_Schaltempf_verfbar = 1).

Anzeige im Kombi:
Sollgang == Istgang          ==> Anzeige Istgang
Sollgang !=  Istgang         ";
CM_ SG_ 263 MO_Oeldruck "Öldruck analog zur Anzeige";
CM_ SG_ 263 MO_Anzeigedrehz "Optimierte Anzeigedrehzahl wegen sportlicherem Drehzahlmesser im Kombi. 
Bei Parallelhybrid: Anzeige VKM- Drehzahl nach Anzeigekonzept";
CM_ SG_ 263 MO_Effizienzmodus "Bei Handschaltern wird  das Fahrprogramm Effizienz signalisiert. 
Bei Automatikgetrieben wird das Fahrprogramm 'D' durch 'E' ersetzt.";
CM_ SG_ 263 MO_Schaltempf_verfbar "Info, ob Schaltempfehlung im Fzg. verfügbar. Statischer Wert, ändert sich für ein Fzg. nicht!";
CM_ SG_ 263 MO_Ladedruck "absoluter Ladedruck";
CM_ SG_ 263 MO_KVS "Motorsteuergerätinterner Verbrauchszähler, der vom Kombi zyklisch ausgelesen wird, um die Einspritzmenge zur Verbrauchsmessung aufzusummieren; aus diesem Zählerstand werden Momentan- und Durchschnittsverbrauch berechnet; das Überlauf-Bit ist zu berücksich";
CM_ SG_ 263 MO_KVS_Ueberlauf "Der motorsteuergeräteinterne Verbrauchszähler ist mindestens einmal übergelaufen. Dieses Bit wird genutzt, um erkennen zu können, daß das Motorsteuergerät aus dem Reset-Zustand hochläuft.";
CM_ SG_ 782 Motor_05_CHK "Berechnung siehe Lastenheft 'Kommunikationsabsicherung für FlexRay und CAN'
Endwerte siehe 'Kommunikationsabsicherung für FlexRay und CAN / Anhang C: Tabelle S-PDU Kennungen'";
CM_ SG_ 782 MO_EKlKomLeiRed "Anforderung an die Klimasteuerung, die Leistungsaufnahme des E-Kompressors bei schlechtem SOC und in bestimmten Fahrsituationen zu begrenzen. (Das bereits bestehende Signal 'Klimakompressor aus' als stets umzusetzende Anforderung bleibt unverändert besteh";
CM_ SG_ 782 MO_Freig_Reku "Empfehlung des Motor-SG's zur Spannungsabsenkung/-anhebung für den Rekuperationsbetrieb";
CM_ SG_ 782 MO_Klima_Eingr "Eingriffe des Motor bei der Klima";
CM_ SG_ 782 MO_Status_Normalbetrieb_02 "Signal ausschließlich für AUDI B8.
Auch im B8 nur GSG Empfänger dieses Signales.
Alle weiteren Fahrzeuge verwenden das Signal in Motor_02.

Das Motorsteuergerät sendet das Informationsbit, wenn die Initialisierungsphase des Steuergerätes abgeschlossen";
CM_ SG_ 782 MO_Schaltbeeinfl_Leistungsbegr "Schaltbeeinflussung an das Getriebe wegen Leistungsbegrenzung";
CM_ SG_ 782 MO_Schaltbeeinfl_Partikelfilter "Schaltbeeinflussung an das Getriebe wegen Partikelfilter-Regeneration
";
CM_ SG_ 782 MO_Prio_MIN_Wunschdrehzahl "Prioritätsbit der Motorwunschdrehzahl als MIN";
CM_ SG_ 782 MO_Freig_Anlass "Bit wird gesetzt, wenn der Motor beim Automatikstart gestartet werden darf (Motorstillstand, Emissionsmaßnahmen sind erfüllt).";
CM_ SG_ 782 MO_Aussp_Anlass "Das Signal zeigt an, ob die Wiederholstartsperre aktiv ist. D. h. eine Ansteuerung des Anlassers wird auch bei erfüllten Startvoraussetzungen (HS: Interlock betätigt bzw. AT: P/N eingelegt und Bremse betätigt) nicht erfolgen.";
CM_ SG_ 782 MO_MAX_Wunschdrehzahl "maximale Motorwunschdrehzahl aufgrund Systemfehlern, Temperatur oder Verbrauchs/ Abgas Optimum, die vom Getriebe nicht überschritten werden darf";
CM_ SG_ 782 MO_Prio_MAX_Wunschdrehzahl "Prioritätsbit der Motorwunschdrehzahl  als MAX";
CM_ SG_ 782 MO_Luftpfad_aktiv "Getriebeeingriff wird zusätzlich zum Zündungspfad auch über den Luftpfad umgesetzt, kommt zu MLB neu in die PL48-Getriebe";
CM_ SG_ 782 MO_v_Begrenz_Aktiv "Motor begrenzt aktuell die Geschwindigkeit des Fahrzeugs; Reaktion auf externe oder interne Anforderung";
CM_ SG_ 782 MO_v_Begrenz_Aktivierbar "Fehlerbit wird vom Motor-SG gesetzt, wenn dieses nicht in dieGeschwindigkeits-begrenzung gehen kann, ein Fehler während der v-Begrenzung auftritt oder v > v_Begrenzung - v_Delta";
CM_ SG_ 782 MO_Verbot_EKP "Es gilt: Signalspec MO_Verbot_EKP V1.1

MSG sendet Verbot der EKP-Ansteuerung an das BCM";
CM_ SG_ 782 MO_Anf_Pruefimpuls "Es gilt: Signalspec MO_Anf_Pruefimpuls v1.1

Anforderung des MSG an das BCM  zum Senden eines Prüfimpulses zur Diagnose der Wakeup-Leitung auf Dauerlow";
CM_ SG_ 782 MO_Anf_KL75 "Information wann die Kl. 75 während des Startvorgangs abgeschaltet werden soll. Umsetzung durch BCM2.";
CM_ SG_ 782 MO_Charisma_FahrPr "Aktuelles Fahrprogramm des Charisma-Teilnehmers

Achtung neue Modusnamen (wie im MMI):

0x1 = Komfort = Comfort
0x2 = Dynamik = Auto
0x3 = Sport = Dynamic";
CM_ SG_ 782 MO_Charisma_Status "Charisma Systemstatus des Charisma-Teilnehmers

Wert 0x3 ist nur für Fahrzeuge ab MQB relevant";
CM_ SG_ 782 MO_Charisma_Umschaltung "Erkennung  Umschaltaufforderung des Charisma-Teilnehmers";
CM_ SG_ 782 MO_Handshake_STH "Es gilt: Signalspec MO_Handshake v1.0

Handshake zwischen MSG und STH. Wenn das MSG die EKP aufgrund einer STH-Anforderung ansteuert und kein Fehlereintrag bzgl. EKP/KPE/NDR vorliegt, wird das Bit gesetzt.";
CM_ SG_ 782 MO_MIN_Wunschdrehzahl "minimale Motorwunschdrehzahl aufgrund Regeneration, die vom Getriebe nicht unterschritten werden darf";
CM_ SG_ 782 MO_Drehzahlbeeinflussung "Mit diesem Faktor kann das Motorsteuergerät die vom CVT-Getriebe einzustellende Sollmotodrehzahl beeinflussen. Im CVT-Steuergerät ist ein verbrauchsoptimales Kennfeld und ein abgasoptimiertes Kennfeld abgelegt. Mit dem Wert von 0-100% wird zwischen diesen";
CM_ SG_ 1088 MO_Kuehlerluefter_MUX "Multiplexer für das Signal 'MO_Kuehlerlüfter'";
CM_ SG_ 1088 MO_Kuehlerluefter_1 "Ansteuertastverhaeltnis (PWM) der Kuehlerluefterendstufe 1";
CM_ SG_ 1088 MO_Kuehlerluefter_2 "Ansteuertastverhaeltnis (PWM) der Kuehlerluefterendstufe 2";
CM_ SG_ 1088 MO_HYB_Status_HV_Ladung "Statusanzeige für Funktion HV-Ladung über 12V-Seite";
CM_ SG_ 1088 MO_ITM_Warnung_Pumpe "Textanzeige: 'Motor sofort abstellen, geschaltete Wasserpumpe defekt / klemmt'";
CM_ SG_ 1088 WIV_Anzeige_aktiv "Peilstabsanzeigefunktion aktiv";
CM_ SG_ 1088 WIV_Oelmin_Warn "Signal gibt an wenn der Ölstand die Min-Schwelle unterschritten hat";
CM_ SG_ 1088 WIV_Sensorfehler "Ölstand/Öltemperatursensor (TOG) defekt";
CM_ SG_ 1088 WIV_Schieflage "Fahrzeug steht nicht waagerecht, Messung ungenau";
CM_ SG_ 1088 WIV_Oelstand "8 Segmente zur Balkenanzeige des Ölstands";
CM_ SG_ 1088 MO_Zustand_HWP "Rückmeldung des  Ansteuerzustand der Hauptwasserpumpe an das Klima-SG .
Der Zustand 'HWP fördert' wird übermittelt, wenn die Schaufeln der Hauptwasserpumpe frei drehen können und die Motordrehzahl und damit die Wasserpumpendrehzahl größer als Null ist. B";
CM_ SG_ 1088 MO_Kat_Warnung "Das Signal lässt im Kombi des LB83x eine Warnlampe angehen um eine Überhitzung   des Katalysators zu signalisieren";
CM_ SG_ 1088 WIV_Oelsystem_aktiv "Gesamtölsystem aktiv (entspricht Ölsensor verbaut) und das Ölstand-Untermenu im MMI aktiv";
CM_ SG_ 1088 WIV_nicht_betriebswarm "Motor nicht betriebswarm, Messung ungenau";
CM_ SG_ 1088 WIV_Ueberfuell_Warn "Ölstand hat die Überfüllschwelle überschritten";
CM_ SG_ 1088 WIV_laufender_Motor "Messung bei laufendem Motor nicht möglich";
CM_ SG_ 1088 MO_HYB_Text_1 "Textanzeige: Fehler Hybridsystem
bitte Fahrzeug an sicherem Ort anhalten";
CM_ SG_ 1088 MO_HYB_Text_2 "Textanzeige: Fehler Hybridystem
bitte Werkstatt aufsuchen";
CM_ SG_ 1088 MO_HYB_Text_3 "Textanzeige: Bitte Motor erneut starten";
CM_ SG_ 1088 MO_HYB_Text_4 "Textanzeige: E-Mode unterbrochen (passiv)";
CM_ SG_ 1088 MO_Text_Motorstart "Anzeigetexte für Start/Stopp und Motor-Start";
CM_ SG_ 1088 MO_HYB_Text_5 "Textanzeige: Hybrid-Funktionen nicht verfügbar";
CM_ SG_ 1088 MO_HYB_Text_6 "Textanzeige: Elektrisches Fahren zur Zeit nicht möglich";
CM_ SG_ 1088 MO_HYB_Text_7 "Textanzeige: Traktionsbatterie wird geladen bitte Motor nicht abstellen";
CM_ SG_ 1088 WIV_Oeldyn_avl "Ölstand aus dynamischer Messung vorhanden";
CM_ SG_ 1088 MO_Text_MSG_Werkstatt "Über dieses Bit wird im Kombi ein Fehlerklartextanzeige erzeugt werden: 'Motorsteuergerät Werkstatt'.
";
CM_ SG_ 1088 MO_Text_Partikelfil_Reg "Über dieses Bit im Kombi wird ein Klartextanzeige erzeugt werden: 'Partikelfilter benötigt Regeneration'.
";
CM_ SG_ 1088 MO_Text_Fehler_Kraftstoffsys "Über dieses Bit wird im Kombi ein Fehlerklartextanzeige erzeugt wird: 'Fehler im Kraftstoffsystem'.	
";
CM_ SG_ 1088 WIV_Oelmenge "Ölmenge zwischen Min und Max";
CM_ SG_ 1088 MO_Systemlampe "EGas Systemlampe (EPC) oder Vorglühlampe im Kombi, Kombi steuert immer gleiche
LED an, nur über Ziffernblatt wird die EPC von der Vorglühlampe differenziert";
CM_ SG_ 1088 MO_OBD2_Lampe "OBD bzw. MIL-Lampe wird vom Motorsteuergerät angesteuert, die Information im Signal GE_OBD_Status wird vom Motorsteuergerät an das Kombi weitergereicht";
CM_ SG_ 1088 MO_Heissleuchte "Ansteuerung der Kühlwassertemperatur-Heißleuchte (Sensor nur noch am Motorsteuergerät): Temperaturschaltschwellen mit Hysterese (bei VW D1/Colorado Kombi derzeit noch nicht genutzt).";
CM_ SG_ 1088 MO_Partikel_Lampe "Partikelfilter-Lampe wird eingeschaltet";
CM_ SG_ 1088 WIV_Oelstand_nicht_vorhanden "Kein aktueller Ölstand vorhanden";
CM_ SG_ 1088 WIV_nachfuellanzeige_ein "Steuert das Aufblenden der Nachfüllanzeige im Kombi, nach Klemme 15 ein und geöffneter Motorhaube";
CM_ SG_ 1088 WIV_Ueberfuell_deaktiv "Unterdrückung der Warnung im Kombi die durch Signal WIV_Ueberfuel_Warn ausgelöst wird";
CM_ SG_ 1088 WIV_Unterfuell_Warn "Ölstand hat die Unterfüllschwelle unterschritten";
CM_ SG_ 1088 MO_Tankdeckel_Lampe "Ansteuerung Tankdeckel-Warnlampe Kombiinstrument (nur Ottomotoren) z.Zt. Vorhalt VW";
CM_ SG_ 1088 MO_Text_Tankdeckelwarn "Textbit der Tankdeckelwarnung, z.Zt. Vorhalt VW";
CM_ SG_ 1088 WIV_Enable_Oeldr_Motor "Schaltet die interne Öldruckauswertung im Kombiinstrument ab und aktiviert die Auswertung des Bits 'WIV_Oeldr_Warn_Motor'";
CM_ SG_ 1088 WIV_Oeldr_Warn_Motor "Löst im Kombiinstrument die rote Prio1-Öldruckwarnung (inkl. 3xBeep) aus.
nur MLB: die Warnauslösung erfolgt nur bei gleichzeitig gesetztem 'WIV_Enable_Oeldr_Motor'";
CM_ SG_ 1088 MO_Avus_Motorschutz "Warntexten zum Kombi für den Fall des Avus-Notlauf. Priowarnung, kann parallel mit anderen Warnungen 
im Mitteldisplay angezeigt werden.";
CM_ SG_ 1088 MO_HYB_Fahrbereitschaft "Signal steuert u.a. in der Lenkhilfe zusammen mit weiteren Informationen den Modewechsel in den 'Drivemode'
Grüne Anzeige im Kombiinstrument zur Signalisierung der Bereitschaft des Hybridsystems.";
CM_ SG_ 1600 MO_QBit_Ansaugluft_Temp "
";
CM_ SG_ 1600 MO_QBit_Kuehlmittel_Temp "
";
CM_ SG_ 1600 MO_HYB_Fehler_HV_Netz "Im HV-Bordnetz ist fehlerbedingt kein generatorischer Betrieb möglich. Das 12V-Bordnetz wird über den DC/DC-Wandler allein aus der Traktionsbatterie gespeist. Um diesen Zustand möglichst lange aufrechterhalten zu können, sollten Komfort-Verbraucher abgesc";
CM_ SG_ 1600 MO_aktives_Getriebeheizen "Information für Getriebe, ob ein Ventil für Getriebheizen angesteuert werden muss";
CM_ SG_ 1600 MO_Absperrventil_oeffnen "Signal an Klima-SG das Absperrrventil anzusteuern. Ab D4 auch 0x3 Ventil_schließen.

Im MQB wird hier der Soll-Status des Absperrventils ausgegeben.
Achtung: bei z. B. klemmendem Ventil entspricht das Signal nicht dem tatsächlichen Status!";
CM_ SG_ 1600 MO_Ansaugluft_Temp "In Fahrzeugen ohne Außentemperatur vom Kombi kann aus der Ansauglufttemperatur auf die Außentemperatur geschlossen werden. Beim SDI ist das mit einer gewissen Genauigkeit gegeben. Genutzt wird es vom ASG.";
CM_ SG_ 1600 MO_Oel_Temp "Realer Meßbereich ca. -40..150 Grad";
CM_ SG_ 1600 MO_Kuehlmittel_Temp "Kuehlmitteltemperatur";
CM_ SG_ 1600 MO_Hoeheninfo "Korrekturfaktor Höhe (1 entspricht 1013 mbar)";
CM_ SG_ 1600 MO_Kennfeldk "Die Kennfeldkühlung ist in diesem Fahrzeug verbaut und hat keinen Systemfehler";
CM_ SG_ 1600 MO_Versionsinfo "Versioninformation vom Motor zur Steuerung bei inkompatiblen KMatrix-Änderung bzw. Einführung von neuen Funktionen, die in den Empfängern verriegelt werden müssen. Zu jedem Ereignis wird ein fixer Zählerstand zugeordnet, um dem Empfänger die funktionale Ä";
CM_ SG_ 1600 MO_Getriebe_kuehlen "Anforderung Getriebekühlventilansteuerung";
CM_ SG_ 1600 MO_Mom_Traegheit_02 "Massenträgheit des Motors (J) in kgm²
Bei Handschaltern wird das Zweimassenschwungrad mit berücksichtigt.
Bei eingebautem Getriebesteuergerät wird nur das Motorträgheitsmoment angegeben (Ohne Anteile des Massenschwungrades).";
CM_ SG_ 1600 MO_Heizungspumpenansteuerung "Anforderung Heizungspumpenansteuerung
MQB und Hybrid: Status der Heizungsunterstützungspumpe am MSG
";
CM_ SG_ 1600 MO_SpannungsAnf "Forderung des Motor-SGs zur Spannungsanhebung";
CM_ SG_ 1600 MO_Nachlaufzeit_Heizungspumpe "Nachlaufzeit für Heizungspumpe für Turboladerschutz";
CM_ SG_ 933 Enrgfluss_State "Energiefluss zwischen den Achsen, Batterie, Elektromotor und Verbrennungsmotor";
CM_ SG_ 933 Ladezustand "Ladezustand der Batterie
";
CM_ SG_ 933 Energiefluss "Die %-Werte ergeben sich aus dem momentanen Moment der E-Maschine bezogen auf das im aktuellen Arbeitspunkt maximal mögliche Moment der E-Maschine (generatorisch = negativ / motorisch = positiv )";
CM_ SG_ 933 Enrgrueckfluss "Frei laufender Zähler für die rückgewonnene Energie";
CM_ SG_ 933 MO_Powermeter "Anzeigewerte im Kombi
0       = Unteres Ende Bremsen/grau;
340   = Unteres Ende CHARGE;
1020 = READY;
1870 = Oberes Ende EFFICIENCY;
3400 = 100%;
4080 = MAX;";
CM_ SG_ 933 MO_Overboost "Nur Turbo. Anzeige eines Overboostpfeils im Kombi während Overboostzustand der Ladedruckregelung.";
CM_ SG_ 933 MO_Anf_Abgasklappe "Der Motor fordert das BCM2 auf das elektropneumatische Umschaltventil der Sportabgasklappe anzusteuern.";
CM_ SG_ 933 MO_LED_Abgasklappe "Der Motor quitiert der Klima (BKE) die Tasteranforderung Sportabgasklappe. Die Klima (BKE) schaltet die LED im Taster Sportabgasklappe ein.";
CM_ SG_ 933 MO_Fehler_MSpG "Wenn das Motorraumspülgebläse defekt ist, oder die Motorraumtemperatur zu hoch sendet die DME Info ans Kombiinstrument. Dieses gibt Textmeldung aus. Und blinkende Heissleuchte.";
CM_ SG_ 933 MO_Temp_MotRaum "Der Motor sendet dem BCM2 die Temperatur im Motorraum in °C.";
CM_ SG_ 933 MO_Hoch_Anz_Nmax "Hochschaltempfehlung der Motorsteuerung vor Erreichen der Abstellerdrehzahl, gangabhängig. Hochschaltpfeil im Kombi, oder Schaltblitz, auch mit Automat.";
CM_ SG_ 933 MO_Hoch_Anz_Eco "Hochschaltempfehlung der Motorsteuerung für günstigen Kraftstoffverbrauch. Hochschaltpfeil im Kombi. Auch mit Automat.";
CM_ SG_ 933 MO_Oel_Temp_Radsatz "Öltemperatur in PDK Radsatz ";
CM_ BO_ 1601 "MLB";
CM_ SG_ 1601 Motor_Code_01_CHK "Berechnung siehe Lastenheft 'Kommunikationsabsicherung für FlexRay und CAN'
Endwerte siehe 'Kommunikationsabsicherung für FlexRay und CAN / Anhang C: Tabelle S-PDU Kennungen'


";
CM_ SG_ 1601 MO_Faktor_Momente "Dieses Bit schaltet den Wertebereich aller Momente vom Motor, Getriebe, TSK, ESP ... um! Die Momente besitzen somit einen variablen Wertebereich, weil sich durch den Faktor die Momente sowohl in Auflösung als auch Maximalwerten ändert.

Defaultwert ist ";
CM_ SG_ 1601 MO_Hybridfahrzeug "Anhand dieses Signals plausibilisiert die Lenkhilfe das Bit Fahrbereitschaft";
CM_ SG_ 1601 MO_Code "Motorcodierinformation für Getriebe. Überwachung auf Falschverbau.






";
CM_ SG_ 1601 MO_Getriebe_Code "Getriebecodierung des Motors 
";
CM_ SG_ 1601 MO_StartStopp_Codiert "Funktion StartStopp im aktuellen Klemmenzyklus verbaut";
CM_ SG_ 1601 MO_Anzahl_Zyl "Zylinderzahl des Verbrennungsmotors";
CM_ SG_ 1601 MO_Kraftstoffart "Primärkraftstoff zum Antrieb des Fahrzeugs";
CM_ SG_ 1601 MO_Hubraum "Hubraum des Verbrennungsmotors";
CM_ SG_ 1601 MO_Ansaugsystem "Art des Ansaugsystems des Verbrennungsmotors";
CM_ SG_ 1601 MO_Leistung "Nennleistung des Verbrennungsmotors";
CM_ SG_ 1601 MO_Abgastyp "Bit 0:
0x0 = kein EOBD
0x1 = EOBD

Bit 1:
0x0 = kein OBD (US-Norm)
0x1 = OBD (US-Norm)

Bit 2: 
0x0 = kein DPF verbaut
0x1 = DPF verbaut

Bit 5: 
0x0 = DPF regeneriert nicht
0x1 = DPF regeneriert
";
BA_DEF_ BO_  "DiagRequest" ENUM  "No","Yes";
BA_DEF_ BO_  "DiagResponse" ENUM  "No","Yes";
BA_DEF_ BO_  "DiagState" ENUM  "No","Yes";
BA_DEF_ BO_  "GenMsgChkConstant" HEX 0 4095;
BA_DEF_ BO_  "GenMsgCycleTime" INT 0 65535;
BA_DEF_ BO_  "GenMsgCycleTimeFast" INT 0 65535;
BA_DEF_ BO_  "GenMsgDelayTime" INT 0 100000;
BA_DEF_ BO_  "GenMsgILSupport" ENUM  "No","Yes";
BA_DEF_ BO_  "GenMsgNrOfRepetition" INT 0 100;
BA_DEF_ BO_  "GenMsgPDUConstants" STRING ;
BA_DEF_ BO_  "GenMsgSendType" ENUM  "Cyclic","not_used","not_used","not_used","not_used","not_used","not_used","IfActive","NoMsgSendType";
BA_DEF_ BO_  "GenMsgStartDelayTime" INT 0 100000;
BA_DEF_ BO_  "NmMessage" ENUM  "No","Yes";
BA_DEF_ BO_  "NmhMessage" ENUM  "No","Yes";
BA_DEF_ BO_  "MsgType" ENUM  "Application","NM ","NMH","TP2.0","ISO-TP ","BAP","EID";
BA_DEF_ BO_  "VAGTP20_API" HEX 0 255;
BA_DEF_ BO_  "VAGTP20_DynConnection" ENUM  "No","Yes";
BA_DEF_ BO_  "VAGTP20_DynSetup" ENUM  "No","Yes";
BA_DEF_ BO_  "VAGTP20_StatConnection" ENUM  "No","Yes";
BA_DEF_ SG_  "GenSigActiveRepetitions" INT -2147483648 2147483647;
BA_DEF_ SG_  "GenSigInactiveValue" INT -2147483648 2147483647;
BA_DEF_ SG_  "GenSigSendType" ENUM  "Cyclic","OnWrite","OnWriteWithRepetition","OnChange","OnChangeWithRepetition","IfActive","IfActiveWithRepetition","NoSigSendType","OnChangeAndIfActive","OnChangeAndIfActiveWithRepetition";
BA_DEF_ SG_  "GenSigStartValue" INT -2147483648 2147483647;
BA_DEF_ SG_  "NWM-WakeupAllowed" ENUM  "No","Yes";
BA_DEF_ SG_  "GenSigFuncType" ENUM  "NoFunction","MsgCounter","CRC-8","XOR","XOR-2","DatedBit","SW-Kl15","CHK","Constant","Protocol","CRC-8-SAE_J1850";
BA_DEF_ SG_  "GenSigSwitchedByIgnition" ENUM  "No","Yes";
BA_DEF_ SG_  "Fehlerwert" HEX 0 2147483647;
BA_DEF_ SG_  "GenSigMissingSourceValue" HEX 0 2147483647;
BA_DEF_REL_ BU_SG_REL_  "GenSigTimeoutTime" INT 0 65535;
BA_DEF_DEF_REL_ "GenSigTimeoutTime" 0;
BA_DEF_DEF_  "DiagRequest" "No";
BA_DEF_DEF_  "DiagResponse" "No";
BA_DEF_DEF_  "DiagState" "No";
BA_DEF_DEF_  "GenMsgChkConstant" 0;
BA_DEF_DEF_  "GenMsgCycleTime" 0;
BA_DEF_DEF_  "GenMsgCycleTimeFast" 0;
BA_DEF_DEF_  "GenMsgDelayTime" 0;
BA_DEF_DEF_  "GenMsgILSupport" "No";
BA_DEF_DEF_  "GenMsgNrOfRepetition" 0;
BA_DEF_DEF_  "GenMsgPDUConstants" "";
BA_DEF_DEF_  "GenMsgSendType" "NoMsgSendType";
BA_DEF_DEF_  "GenMsgStartDelayTime" 0;
BA_DEF_DEF_  "NmMessage" "No";
BA_DEF_DEF_  "NmhMessage" "No";
BA_DEF_DEF_  "MsgType" "Application";
BA_DEF_DEF_  "VAGTP20_API" 0;
BA_DEF_DEF_  "VAGTP20_DynConnection" "No";
BA_DEF_DEF_  "VAGTP20_DynSetup" "No";
BA_DEF_DEF_  "VAGTP20_StatConnection" "No";
BA_DEF_DEF_  "GenSigActiveRepetitions" 0;
BA_DEF_DEF_  "GenSigInactiveValue" 0;
BA_DEF_DEF_  "GenSigSendType" "NoSigSendType";
BA_DEF_DEF_  "GenSigStartValue" 0;
BA_DEF_DEF_  "NWM-WakeupAllowed" "No";
BA_DEF_DEF_  "GenSigFuncType" "NoFunction";
BA_DEF_DEF_  "GenSigSwitchedByIgnition" "Yes";
BA_DEF_DEF_  "Fehlerwert" 0;
BA_DEF_DEF_  "GenSigMissingSourceValue" 0;
BA_ "GenMsgSendType" BO_ 1706 0;
BA_ "GenMsgILSupport" BO_ 1706 1;
BA_ "GenMsgDelayTime" BO_ 1706 100;
BA_ "GenMsgCycleTime" BO_ 1706 1000;
BA_ "GenMsgSendType" BO_ 282 0;
BA_ "GenMsgILSupport" BO_ 282 1;
BA_ "GenMsgCycleTime" BO_ 282 20;
BA_ "GenMsgSendType" BO_ 1331 0;
BA_ "GenMsgILSupport" BO_ 1331 1;
BA_ "GenMsgCycleTime" BO_ 1331 250;
BA_ "GenMsgSendType" BO_ 1329 0;
BA_ "GenMsgILSupport" BO_ 1329 1;
BA_ "GenMsgDelayTime" BO_ 1329 50;
BA_ "GenMsgCycleTime" BO_ 1329 250;
BA_ "GenMsgSendType" BO_ 922 0;
BA_ "GenMsgILSupport" BO_ 922 1;
BA_ "GenMsgCycleTime" BO_ 922 100;
BA_ "GenMsgSendType" BO_ 923 0;
BA_ "GenMsgILSupport" BO_ 923 1;
BA_ "GenMsgCycleTime" BO_ 923 100;
BA_ "GenMsgSendType" BO_ 1534 0;
BA_ "GenMsgILSupport" BO_ 1534 1;
BA_ "GenMsgCycleTime" BO_ 1534 1000;
BA_ "GenMsgSendType" BO_ 1535 0;
BA_ "GenMsgILSupport" BO_ 1535 1;
BA_ "GenMsgCycleTime" BO_ 1535 1000;
BA_ "GenMsgSendType" BO_ 1343 0;
BA_ "GenMsgILSupport" BO_ 1343 1;
BA_ "GenMsgCycleTime" BO_ 1343 100;
BA_ "GenMsgSendType" BO_ 1662 0;
BA_ "GenMsgPDUConstants" BO_ 1662 "0x25,0x25,0x25,0x25,0x25,0x25,0x25,0x25,0x25,0x25,0x25,0x25,0x25,0x25,0x25,0x25";
BA_ "GenMsgILSupport" BO_ 1662 1;
BA_ "GenMsgDelayTime" BO_ 1662 50;
BA_ "GenMsgCycleTime" BO_ 1662 1000;
BA_ "GenMsgSendType" BO_ 810 0;
BA_ "GenMsgPDUConstants" BO_ 810 "0x29,0x29,0x29,0x29,0x29,0x29,0x29,0x29,0x29,0x29,0x29,0x29,0x29,0x29,0x29,0x29";
BA_ "GenMsgILSupport" BO_ 810 1;
BA_ "GenMsgCycleTime" BO_ 810 40;
BA_ "GenMsgChkConstant" BO_ 810 41;
BA_ "GenMsgSendType" BO_ 1137 0;
BA_ "GenMsgILSupport" BO_ 1137 1;
BA_ "GenMsgCycleTime" BO_ 1137 100;
BA_ "GenMsgSendType" BO_ 1321 0;
BA_ "GenMsgILSupport" BO_ 1321 1;
BA_ "GenMsgDelayTime" BO_ 1321 20;
BA_ "GenMsgCycleTime" BO_ 1321 200;
BA_ "GenMsgSendType" BO_ 917 0;
BA_ "GenMsgILSupport" BO_ 917 1;
BA_ "GenMsgCycleTime" BO_ 917 100;
BA_ "GenMsgSendType" BO_ 1704 0;
BA_ "GenMsgILSupport" BO_ 1704 1;
BA_ "GenMsgDelayTime" BO_ 1704 100;
BA_ "GenMsgCycleTime" BO_ 1704 1000;
BA_ "GenMsgNrOfRepetition" BO_ 1471 5;
BA_ "GenMsgILSupport" BO_ 1471 1;
BA_ "GenMsgDelayTime" BO_ 1471 30;
BA_ "GenMsgCycleTimeFast" BO_ 1471 1000;
BA_ "GenMsgSendType" BO_ 193 0;
BA_ "GenMsgNrOfRepetition" BO_ 193 3;
BA_ "GenMsgILSupport" BO_ 193 1;
BA_ "GenMsgDelayTime" BO_ 193 10;
BA_ "GenMsgCycleTimeFast" BO_ 193 100;
BA_ "GenMsgCycleTime" BO_ 193 500;
BA_ "GenMsgSendType" BO_ 126 0;
BA_ "GenMsgILSupport" BO_ 126 1;
BA_ "GenMsgCycleTime" BO_ 126 20;
BA_ "GenMsgChkConstant" BO_ 126 129;
BA_ "GenMsgSendType" BO_ 263 0;
BA_ "GenMsgILSupport" BO_ 263 1;
BA_ "GenMsgCycleTime" BO_ 263 20;
BA_ "GenMsgSendType" BO_ 782 0;
BA_ "GenMsgILSupport" BO_ 782 1;
BA_ "GenMsgCycleTime" BO_ 782 50;
BA_ "GenMsgChkConstant" BO_ 782 13;
BA_ "GenMsgSendType" BO_ 1088 0;
BA_ "GenMsgILSupport" BO_ 1088 1;
BA_ "GenMsgCycleTime" BO_ 1088 100;
BA_ "GenMsgSendType" BO_ 1600 0;
BA_ "GenMsgILSupport" BO_ 1600 1;
BA_ "GenMsgCycleTime" BO_ 1600 500;
BA_ "GenMsgSendType" BO_ 933 0;
BA_ "GenMsgILSupport" BO_ 933 1;
BA_ "GenMsgDelayTime" BO_ 933 50;
BA_ "GenMsgCycleTime" BO_ 933 100;
BA_ "GenMsgSendType" BO_ 1601 0;
BA_ "GenMsgILSupport" BO_ 1601 1;
BA_ "GenMsgCycleTime" BO_ 1601 1000;
BA_ "GenMsgChkConstant" BO_ 1601 71;
BA_ "GenSigSwitchedByIgnition" SG_ 1706 KBI_STH_Std 0;
BA_ "GenSigSendType" SG_ 1706 KBI_STH_Std 0;
BA_ "GenSigSwitchedByIgnition" SG_ 1706 KBI_STH_Min 0;
BA_ "GenSigSendType" SG_ 1706 KBI_STH_Min 0;
BA_ "GenSigSwitchedByIgnition" SG_ 1706 KBI_STH_TT 0;
BA_ "GenSigSendType" SG_ 1706 KBI_STH_TT 0;
BA_ "GenSigSwitchedByIgnition" SG_ 1706 KBI_STH_MM 0;
BA_ "GenSigStartValue" SG_ 1706 KBI_STH_MM 1;
BA_ "GenSigSendType" SG_ 1706 KBI_STH_MM 0;
BA_ "GenSigSwitchedByIgnition" SG_ 1706 KBI_STH_JJ 0;
BA_ "GenSigSendType" SG_ 1706 KBI_STH_JJ 0;
BA_ "GenSigSwitchedByIgnition" SG_ 1706 KBI_STH_Status 0;
BA_ "GenSigSendType" SG_ 1706 KBI_STH_Status 0;
BA_ "GenSigSwitchedByIgnition" SG_ 1706 KBI_STH_Timer_Status 0;
BA_ "GenSigSendType" SG_ 1706 KBI_STH_Timer_Status 0;
BA_ "GenSigSwitchedByIgnition" SG_ 1706 KBI_STH_Betriebsdauer 0;
BA_ "GenSigSendType" SG_ 1706 KBI_STH_Betriebsdauer 0;
BA_ "GenSigSwitchedByIgnition" SG_ 1706 KBI_Menu1_Pos1 0;
BA_ "GenSigSendType" SG_ 1706 KBI_Menu1_Pos1 3;
BA_ "GenSigSwitchedByIgnition" SG_ 1706 KBI_Menu1_Pos2 0;
BA_ "GenSigSendType" SG_ 1706 KBI_Menu1_Pos2 3;
BA_ "GenSigSwitchedByIgnition" SG_ 1706 KBI_Menu1_Pos3 0;
BA_ "GenSigSendType" SG_ 1706 KBI_Menu1_Pos3 3;
BA_ "GenSigSwitchedByIgnition" SG_ 1706 KBI_Menu1_Pos4 0;
BA_ "GenSigSendType" SG_ 1706 KBI_Menu1_Pos4 3;
BA_ "GenSigSwitchedByIgnition" SG_ 1706 KBI_Menu1_Pos5 0;
BA_ "GenSigSendType" SG_ 1706 KBI_Menu1_Pos5 3;
BA_ "GenSigSwitchedByIgnition" SG_ 1706 KBI_Menu1_Pos6 0;
BA_ "GenSigSendType" SG_ 1706 KBI_Menu1_Pos6 3;
BA_ "GenSigSwitchedByIgnition" SG_ 1706 KBI_Menu1_Pos7 0;
BA_ "GenSigSendType" SG_ 1706 KBI_Menu1_Pos7 3;
BA_ "GenSigSwitchedByIgnition" SG_ 1706 KBI_Menu1_Pos8 0;
BA_ "GenSigSendType" SG_ 1706 KBI_Menu1_Pos8 3;
BA_ "GenSigSwitchedByIgnition" SG_ 1706 KBI_Menu2_Pos1 0;
BA_ "GenSigSendType" SG_ 1706 KBI_Menu2_Pos1 3;
BA_ "GenSigSwitchedByIgnition" SG_ 1706 KBI_Menu2_Pos2 0;
BA_ "GenSigSendType" SG_ 1706 KBI_Menu2_Pos2 3;
BA_ "GenSigSwitchedByIgnition" SG_ 1706 KBI_Menu2_Pos3 0;
BA_ "GenSigSendType" SG_ 1706 KBI_Menu2_Pos3 3;
BA_ "GenSigSwitchedByIgnition" SG_ 1706 KBI_Menu2_Pos4 0;
BA_ "GenSigSendType" SG_ 1706 KBI_Menu2_Pos4 3;
BA_ "GenSigSwitchedByIgnition" SG_ 1706 KBI_Menu2_Pos5 0;
BA_ "GenSigSendType" SG_ 1706 KBI_Menu2_Pos5 3;
BA_ "GenSigSwitchedByIgnition" SG_ 1706 KBI_Menu2_Pos6 0;
BA_ "GenSigSendType" SG_ 1706 KBI_Menu2_Pos6 3;
BA_ "GenSigSwitchedByIgnition" SG_ 1706 KBI_Menu2_Pos7 0;
BA_ "GenSigSendType" SG_ 1706 KBI_Menu2_Pos7 3;
BA_ "GenSigSwitchedByIgnition" SG_ 1706 KBI_Menu2_Pos8 0;
BA_ "GenSigSendType" SG_ 1706 KBI_Menu2_Pos8 3;
BA_ "GenSigSwitchedByIgnition" SG_ 1706 KBI_Menu3_Pos1 0;
BA_ "GenSigSendType" SG_ 1706 KBI_Menu3_Pos1 3;
BA_ "GenSigSwitchedByIgnition" SG_ 1706 KBI_Menu3_Pos2 0;
BA_ "GenSigSendType" SG_ 1706 KBI_Menu3_Pos2 3;
BA_ "GenSigSwitchedByIgnition" SG_ 1706 KBI_Menu3_Pos3 0;
BA_ "GenSigSendType" SG_ 1706 KBI_Menu3_Pos3 3;
BA_ "GenSigSwitchedByIgnition" SG_ 1706 KBI_Menu3_Pos4 0;
BA_ "GenSigSendType" SG_ 1706 KBI_Menu3_Pos4 3;
BA_ "GenSigSwitchedByIgnition" SG_ 1706 KBI_Menu3_Pos5 0;
BA_ "GenSigSendType" SG_ 1706 KBI_Menu3_Pos5 3;
BA_ "GenSigSwitchedByIgnition" SG_ 1706 KBI_Menu3_Pos6 0;
BA_ "GenSigSendType" SG_ 1706 KBI_Menu3_Pos6 3;
BA_ "GenSigSwitchedByIgnition" SG_ 1706 KBI_Menu3_Pos7 0;
BA_ "GenSigSendType" SG_ 1706 KBI_Menu3_Pos7 3;
BA_ "GenSigSwitchedByIgnition" SG_ 1706 KBI_Menu3_Pos8 0;
BA_ "GenSigSendType" SG_ 1706 KBI_Menu3_Pos8 3;
BA_ "GenSigSwitchedByIgnition" SG_ 282 KBI_GZeit_HSek 0;
BA_ "GenSigSendType" SG_ 282 KBI_GZeit_HSek 0;
BA_ "GenSigSwitchedByIgnition" SG_ 282 KBI_GZeit_Sek 0;
BA_ "GenSigSendType" SG_ 282 KBI_GZeit_Sek 0;
BA_ "GenSigSwitchedByIgnition" SG_ 282 KBI_GZeit_Min 0;
BA_ "GenSigSendType" SG_ 282 KBI_GZeit_Min 0;
BA_ "GenSigSwitchedByIgnition" SG_ 282 KBI_GZeit_Std 0;
BA_ "GenSigSendType" SG_ 282 KBI_GZeit_Std 0;
BA_ "GenSigSwitchedByIgnition" SG_ 282 KBI_St_SU 0;
BA_ "GenSigSendType" SG_ 282 KBI_St_SU 0;
BA_ "GenSigSwitchedByIgnition" SG_ 282 KBI_Uhrzeit_SU 0;
BA_ "GenSigSendType" SG_ 282 KBI_Uhrzeit_SU 0;
BA_ "GenSigSwitchedByIgnition" SG_ 282 KBI_Reichw_anz 0;
BA_ "GenSigSendType" SG_ 282 KBI_Reichw_anz 0;
BA_ "Fehlerwert" SG_ 282 KBI_E_Restreichweite 4095;
BA_ "GenSigSwitchedByIgnition" SG_ 282 KBI_E_Restreichweite 0;
BA_ "GenSigStartValue" SG_ 282 KBI_E_Restreichweite 4094;
BA_ "GenSigSendType" SG_ 282 KBI_E_Restreichweite 0;
BA_ "GenSigSwitchedByIgnition" SG_ 282 KBI_Uhrzeit_Kompass 0;
BA_ "GenSigSendType" SG_ 282 KBI_Uhrzeit_Kompass 0;
BA_ "GenSigSwitchedByIgnition" SG_ 1331 KBI_RZ_Nr 0;
BA_ "GenSigSendType" SG_ 1331 KBI_RZ_Nr 0;
BA_ "GenSigSwitchedByIgnition" SG_ 1331 KBI_ZZ_Nr 0;
BA_ "GenSigSendType" SG_ 1331 KBI_ZZ_Nr 0;
BA_ "GenSigSwitchedByIgnition" SG_ 1331 KBI_ZZeit_Std 0;
BA_ "GenSigSendType" SG_ 1331 KBI_ZZeit_Std 0;
BA_ "GenSigSwitchedByIgnition" SG_ 1331 KBI_ZZeit_Min 0;
BA_ "GenSigSendType" SG_ 1331 KBI_ZZeit_Min 0;
BA_ "GenSigSwitchedByIgnition" SG_ 1331 KBI_ZZeit_Sek 0;
BA_ "GenSigSendType" SG_ 1331 KBI_ZZeit_Sek 0;
BA_ "GenSigSwitchedByIgnition" SG_ 1331 KBI_ZZeit_HSek 0;
BA_ "GenSigSendType" SG_ 1331 KBI_ZZeit_HSek 0;
BA_ "GenSigSwitchedByIgnition" SG_ 1331 KBI_Chrono_Akt 0;
BA_ "GenSigSendType" SG_ 1331 KBI_Chrono_Akt 0;
BA_ "Fehlerwert" SG_ 1331 KBI_Trip_Reset_Min 63;
BA_ "GenSigSwitchedByIgnition" SG_ 1331 KBI_Trip_Reset_Min 0;
BA_ "NWM-WakeupAllowed" SG_ 1331 KBI_Trip_Reset_Min 1;
BA_ "GenSigStartValue" SG_ 1331 KBI_Trip_Reset_Min 62;
BA_ "GenSigSendType" SG_ 1331 KBI_Trip_Reset_Min 0;
BA_ "Fehlerwert" SG_ 1331 KBI_Trip_Reset_Std 31;
BA_ "GenSigSwitchedByIgnition" SG_ 1331 KBI_Trip_Reset_Std 0;
BA_ "NWM-WakeupAllowed" SG_ 1331 KBI_Trip_Reset_Std 1;
BA_ "GenSigStartValue" SG_ 1331 KBI_Trip_Reset_Std 30;
BA_ "GenSigSendType" SG_ 1331 KBI_Trip_Reset_Std 0;
BA_ "GenSigSwitchedByIgnition" SG_ 1329 KBI_RZeit_HSek 0;
BA_ "GenSigSendType" SG_ 1329 KBI_RZeit_HSek 0;
BA_ "GenSigSwitchedByIgnition" SG_ 1329 KBI_RZeit_Min 0;
BA_ "GenSigSendType" SG_ 1329 KBI_RZeit_Min 0;
BA_ "GenSigSwitchedByIgnition" SG_ 1329 KBI_RZeit_Sek 0;
BA_ "GenSigSendType" SG_ 1329 KBI_RZeit_Sek 0;
BA_ "GenSigSwitchedByIgnition" SG_ 1329 KBI_RZeit_Std 0;
BA_ "GenSigSendType" SG_ 1329 KBI_RZeit_Std 0;
BA_ "GenSigSwitchedByIgnition" SG_ 1329 KBI_St_Disp 0;
BA_ "GenSigSendType" SG_ 1329 KBI_St_Disp 3;
BA_ "GenSigSwitchedByIgnition" SG_ 1329 KBI_lRZeit_HSek 0;
BA_ "GenSigSendType" SG_ 1329 KBI_lRZeit_HSek 0;
BA_ "GenSigSwitchedByIgnition" SG_ 1329 KBI_lRZeit_Min 0;
BA_ "GenSigSendType" SG_ 1329 KBI_lRZeit_Min 0;
BA_ "GenSigSwitchedByIgnition" SG_ 1329 KBI_lRZeit_Sek 0;
BA_ "GenSigSendType" SG_ 1329 KBI_lRZeit_Sek 0;
BA_ "GenSigSwitchedByIgnition" SG_ 1329 KBI_lRZeit_Std 0;
BA_ "GenSigSendType" SG_ 1329 KBI_lRZeit_Std 0;
BA_ "GenSigSwitchedByIgnition" SG_ 922 KBI_Trip_DS_Verbr_1 0;
BA_ "GenSigSendType" SG_ 922 KBI_Trip_DS_Verbr_1 0;
BA_ "GenSigSwitchedByIgnition" SG_ 922 KBI_Trip_Min_1 0;
BA_ "GenSigSendType" SG_ 922 KBI_Trip_Min_1 0;
BA_ "GenSigSwitchedByIgnition" SG_ 922 KBI_Trip_Std_1 0;
BA_ "GenSigSendType" SG_ 922 KBI_Trip_Std_1 0;
BA_ "GenSigSwitchedByIgnition" SG_ 922 KBI_Trip_Strecke_1 0;
BA_ "GenSigSendType" SG_ 922 KBI_Trip_Strecke_1 0;
BA_ "GenSigSwitchedByIgnition" SG_ 922 KBI_Trip_DS_V_1 0;
BA_ "GenSigSendType" SG_ 922 KBI_Trip_DS_V_1 0;
BA_ "GenSigSwitchedByIgnition" SG_ 923 KBI_Trip_DS_Verbr_2 0;
BA_ "GenSigSendType" SG_ 923 KBI_Trip_DS_Verbr_2 0;
BA_ "GenSigSwitchedByIgnition" SG_ 923 KBI_Trip_Min_2 0;
BA_ "GenSigSendType" SG_ 923 KBI_Trip_Min_2 0;
BA_ "GenSigSwitchedByIgnition" SG_ 923 KBI_Trip_Std_2 0;
BA_ "GenSigSendType" SG_ 923 KBI_Trip_Std_2 0;
BA_ "GenSigSwitchedByIgnition" SG_ 923 KBI_Trip_Strecke_2 0;
BA_ "GenSigSendType" SG_ 923 KBI_Trip_Strecke_2 0;
BA_ "GenSigSwitchedByIgnition" SG_ 923 KBI_Trip_DS_V_2 0;
BA_ "GenSigSendType" SG_ 923 KBI_Trip_DS_V_2 0;
BA_ "GenSigSwitchedByIgnition" SG_ 1534 KBI_Set_Timer_MUX 0;
BA_ "GenSigSendType" SG_ 1534 KBI_Set_Timer_MUX 0;
BA_ "GenSigSwitchedByIgnition" SG_ 1534 KBI_Set_Timer_1_Jahr 0;
BA_ "GenSigStartValue" SG_ 1534 KBI_Set_Timer_1_Jahr 126;
BA_ "GenSigSwitchedByIgnition" SG_ 1534 KBI_Set_Timer_2_Jahr 0;
BA_ "GenSigStartValue" SG_ 1534 KBI_Set_Timer_2_Jahr 126;
BA_ "GenSigSwitchedByIgnition" SG_ 1534 KBI_Set_Timer_3_Jahr 0;
BA_ "GenSigStartValue" SG_ 1534 KBI_Set_Timer_3_Jahr 126;
BA_ "GenSigSwitchedByIgnition" SG_ 1534 KBI_Set_Timer_4_Jahr 0;
BA_ "GenSigStartValue" SG_ 1534 KBI_Set_Timer_4_Jahr 126;
BA_ "Fehlerwert" SG_ 1534 KBI_Set_Timer_1_Minute 63;
BA_ "GenSigSwitchedByIgnition" SG_ 1534 KBI_Set_Timer_1_Minute 0;
BA_ "GenSigStartValue" SG_ 1534 KBI_Set_Timer_1_Minute 62;
BA_ "Fehlerwert" SG_ 1534 KBI_Set_Timer_2_Minute 63;
BA_ "GenSigSwitchedByIgnition" SG_ 1534 KBI_Set_Timer_2_Minute 0;
BA_ "GenSigStartValue" SG_ 1534 KBI_Set_Timer_2_Minute 62;
BA_ "GenSigSwitchedByIgnition" SG_ 1534 KBI_Set_Timer_3_Minute 0;
BA_ "GenSigSwitchedByIgnition" SG_ 1534 KBI_Set_Timer_4_Minute 0;
BA_ "Fehlerwert" SG_ 1534 KBI_Set_Timer_1_Monat 15;
BA_ "GenSigSwitchedByIgnition" SG_ 1534 KBI_Set_Timer_1_Monat 0;
BA_ "Fehlerwert" SG_ 1534 KBI_Set_Timer_2_Monat 15;
BA_ "GenSigSwitchedByIgnition" SG_ 1534 KBI_Set_Timer_2_Monat 0;
BA_ "Fehlerwert" SG_ 1534 KBI_Set_Timer_3_Monat 15;
BA_ "GenSigSwitchedByIgnition" SG_ 1534 KBI_Set_Timer_3_Monat 0;
BA_ "Fehlerwert" SG_ 1534 KBI_Set_Timer_4_Monat 15;
BA_ "GenSigSwitchedByIgnition" SG_ 1534 KBI_Set_Timer_4_Monat 0;
BA_ "Fehlerwert" SG_ 1534 KBI_Set_Timer_1_Stunde 31;
BA_ "GenSigSwitchedByIgnition" SG_ 1534 KBI_Set_Timer_1_Stunde 0;
BA_ "GenSigStartValue" SG_ 1534 KBI_Set_Timer_1_Stunde 30;
BA_ "Fehlerwert" SG_ 1534 KBI_Set_Timer_2_Stunde 31;
BA_ "GenSigSwitchedByIgnition" SG_ 1534 KBI_Set_Timer_2_Stunde 0;
BA_ "GenSigStartValue" SG_ 1534 KBI_Set_Timer_2_Stunde 30;
BA_ "Fehlerwert" SG_ 1534 KBI_Set_Timer_3_Stunde 31;
BA_ "GenSigSwitchedByIgnition" SG_ 1534 KBI_Set_Timer_3_Stunde 0;
BA_ "GenSigStartValue" SG_ 1534 KBI_Set_Timer_3_Stunde 30;
BA_ "Fehlerwert" SG_ 1534 KBI_Set_Timer_4_Stunde 31;
BA_ "GenSigSwitchedByIgnition" SG_ 1534 KBI_Set_Timer_4_Stunde 0;
BA_ "GenSigStartValue" SG_ 1534 KBI_Set_Timer_4_Stunde 30;
BA_ "GenSigSwitchedByIgnition" SG_ 1534 KBI_Set_Timer_1_Tag 0;
BA_ "GenSigSwitchedByIgnition" SG_ 1534 KBI_Set_Timer_2_Tag 0;
BA_ "GenSigSwitchedByIgnition" SG_ 1534 KBI_Set_Timer_3_Tag 0;
BA_ "GenSigSwitchedByIgnition" SG_ 1534 KBI_Set_Timer_4_Tag 0;
BA_ "GenSigSwitchedByIgnition" SG_ 1534 KBI_Set_Timer_1_Laden 0;
BA_ "GenSigSwitchedByIgnition" SG_ 1534 KBI_Set_Timer_2_Laden 0;
BA_ "GenSigSwitchedByIgnition" SG_ 1534 KBI_Set_Timer_3_Laden 0;
BA_ "GenSigSwitchedByIgnition" SG_ 1534 KBI_Set_Timer_4_Laden 0;
BA_ "GenSigSwitchedByIgnition" SG_ 1534 KBI_Set_Timer_1_Vorklima 0;
BA_ "GenSigSwitchedByIgnition" SG_ 1534 KBI_Set_Timer_2_Vorklima 0;
BA_ "GenSigSwitchedByIgnition" SG_ 1534 KBI_Set_Timer_3_Vorklima 0;
BA_ "GenSigSwitchedByIgnition" SG_ 1534 KBI_Set_Timer_4_Vorklima 0;
BA_ "GenSigSwitchedByIgnition" SG_ 1534 KBI_Set_Timer_1_Zyklus_Mo 0;
BA_ "GenSigSwitchedByIgnition" SG_ 1534 KBI_Set_Timer_2_Zyklus_Mo 0;
BA_ "GenSigSwitchedByIgnition" SG_ 1534 KBI_Set_Timer_3_Zyklus_Mo 0;
BA_ "GenSigSwitchedByIgnition" SG_ 1534 KBI_Set_Timer_4_Zyklus_Mo 0;
BA_ "GenSigSwitchedByIgnition" SG_ 1534 KBI_Set_Timer_1_Zyklus_Di 0;
BA_ "GenSigSwitchedByIgnition" SG_ 1534 KBI_Set_Timer_2_Zyklus_Di 0;
BA_ "GenSigSwitchedByIgnition" SG_ 1534 KBI_Set_Timer_3_Zyklus_Di 0;
BA_ "GenSigSwitchedByIgnition" SG_ 1534 KBI_Set_Timer_4_Zyklus_Di 0;
BA_ "GenSigSwitchedByIgnition" SG_ 1534 KBI_Set_Timer_1_Zyklus_Mi 0;
BA_ "GenSigSwitchedByIgnition" SG_ 1534 KBI_Set_Timer_2_Zyklus_Mi 0;
BA_ "GenSigSwitchedByIgnition" SG_ 1534 KBI_Set_Timer_3_Zyklus_Mi 0;
BA_ "GenSigSwitchedByIgnition" SG_ 1534 KBI_Set_Timer_4_Zyklus_Mi 0;
BA_ "GenSigSwitchedByIgnition" SG_ 1534 KBI_Set_Timer_1_Zyklus_Do 0;
BA_ "GenSigSwitchedByIgnition" SG_ 1534 KBI_Set_Timer_2_Zyklus_Do 0;
BA_ "GenSigSwitchedByIgnition" SG_ 1534 KBI_Set_Timer_3_Zyklus_Do 0;
BA_ "GenSigSwitchedByIgnition" SG_ 1534 KBI_Set_Timer_4_Zyklus_Do 0;
BA_ "GenSigSwitchedByIgnition" SG_ 1534 KBI_Set_Timer_1_Zyklus_Fr 0;
BA_ "GenSigSwitchedByIgnition" SG_ 1534 KBI_Set_Timer_2_Zyklus_Fr 0;
BA_ "GenSigSwitchedByIgnition" SG_ 1534 KBI_Set_Timer_3_Zyklus_Fr 0;
BA_ "GenSigSwitchedByIgnition" SG_ 1534 KBI_Set_Timer_4_Zyklus_Fr 0;
BA_ "GenSigSwitchedByIgnition" SG_ 1534 KBI_Set_Timer_1_Zyklus_Sa 0;
BA_ "GenSigSwitchedByIgnition" SG_ 1534 KBI_Set_Timer_2_Zyklus_Sa 0;
BA_ "GenSigSwitchedByIgnition" SG_ 1534 KBI_Set_Timer_3_Zyklus_Sa 0;
BA_ "GenSigSwitchedByIgnition" SG_ 1534 KBI_Set_Timer_4_Zyklus_Sa 0;
BA_ "GenSigSwitchedByIgnition" SG_ 1534 KBI_Set_Timer_1_Zyklus_So 0;
BA_ "GenSigSwitchedByIgnition" SG_ 1534 KBI_Set_Timer_2_Zyklus_So 0;
BA_ "GenSigSwitchedByIgnition" SG_ 1534 KBI_Set_Timer_3_Zyklus_So 0;
BA_ "GenSigSwitchedByIgnition" SG_ 1534 KBI_Set_Timer_4_Zyklus_So 0;
BA_ "GenSigSwitchedByIgnition" SG_ 1534 KBI_Set_Timer_1_Zyklus_WH 0;
BA_ "GenSigSwitchedByIgnition" SG_ 1534 KBI_Set_Timer_2_Zyklus_WH 0;
BA_ "GenSigSwitchedByIgnition" SG_ 1534 KBI_Set_Timer_3_Zyklus_WH 0;
BA_ "GenSigSwitchedByIgnition" SG_ 1534 KBI_Set_Timer_4_Zyklus_WH 0;
BA_ "GenSigSwitchedByIgnition" SG_ 1535 KBI_Trip_E_Min 0;
BA_ "GenSigSendType" SG_ 1535 KBI_Trip_E_Min 0;
BA_ "GenSigSwitchedByIgnition" SG_ 1535 KBI_Trip_E_Std 0;
BA_ "GenSigSendType" SG_ 1535 KBI_Trip_E_Std 0;
BA_ "Fehlerwert" SG_ 1535 KBI_Service_km 1023;
BA_ "GenSigSwitchedByIgnition" SG_ 1535 KBI_Service_km 0;
BA_ "GenSigStartValue" SG_ 1535 KBI_Service_km 1022;
BA_ "GenSigSendType" SG_ 1535 KBI_Service_km 0;
BA_ "GenSigSwitchedByIgnition" SG_ 1535 KBI_Service_Typ 0;
BA_ "GenSigSendType" SG_ 1535 KBI_Service_Typ 0;
BA_ "Fehlerwert" SG_ 1535 KBI_Service_Zeit 2047;
BA_ "GenSigSwitchedByIgnition" SG_ 1535 KBI_Service_Zeit 0;
BA_ "GenSigStartValue" SG_ 1535 KBI_Service_Zeit 2046;
BA_ "GenSigSendType" SG_ 1535 KBI_Service_Zeit 0;
BA_ "Fehlerwert" SG_ 1343 KBI_Trip_E_Verbr_fortl 1023;
BA_ "GenSigSwitchedByIgnition" SG_ 1343 KBI_Trip_E_Verbr_fortl 0;
BA_ "GenSigStartValue" SG_ 1343 KBI_Trip_E_Verbr_fortl 1022;
BA_ "GenSigSendType" SG_ 1343 KBI_Trip_E_Verbr_fortl 0;
BA_ "Fehlerwert" SG_ 1343 KBI_Trip_E_Verbr_seit 1023;
BA_ "GenSigSwitchedByIgnition" SG_ 1343 KBI_Trip_E_Verbr_seit 0;
BA_ "GenSigStartValue" SG_ 1343 KBI_Trip_E_Verbr_seit 1022;
BA_ "GenSigSendType" SG_ 1343 KBI_Trip_E_Verbr_seit 0;
BA_ "Fehlerwert" SG_ 1343 KBI_Trip_E_Strecke_fortl 131071;
BA_ "GenSigSwitchedByIgnition" SG_ 1343 KBI_Trip_E_Strecke_fortl 0;
BA_ "GenSigStartValue" SG_ 1343 KBI_Trip_E_Strecke_fortl 131070;
BA_ "GenSigSendType" SG_ 1343 KBI_Trip_E_Strecke_fortl 0;
BA_ "Fehlerwert" SG_ 1343 KBI_Trip_E_Strecke_seit 131071;
BA_ "GenSigSwitchedByIgnition" SG_ 1343 KBI_Trip_E_Strecke_seit 0;
BA_ "GenSigStartValue" SG_ 1343 KBI_Trip_E_Strecke_seit 131070;
BA_ "GenSigSendType" SG_ 1343 KBI_Trip_E_Strecke_seit 0;
BA_ "GenSigSwitchedByIgnition" SG_ 1662 LAD_02_CHK 0;
BA_ "GenSigFuncType" SG_ 1662 LAD_02_CHK 3;
BA_ "GenSigSendType" SG_ 1662 LAD_02_CHK 0;
BA_ "GenSigSwitchedByIgnition" SG_ 1662 LAD_02_BZ 0;
BA_ "GenSigFuncType" SG_ 1662 LAD_02_BZ 1;
BA_ "GenSigSendType" SG_ 1662 LAD_02_BZ 0;
BA_ "GenSigSwitchedByIgnition" SG_ 1662 LAD_Abregelung_Temperatur 0;
BA_ "GenSigSendType" SG_ 1662 LAD_Abregelung_Temperatur 0;
BA_ "GenSigSwitchedByIgnition" SG_ 1662 LAD_Abregelung_IU_Ein_Aus 0;
BA_ "GenSigSendType" SG_ 1662 LAD_Abregelung_IU_Ein_Aus 0;
BA_ "GenSigSwitchedByIgnition" SG_ 1662 LAD_Abregelung_BuchseTemp 0;
BA_ "GenSigSendType" SG_ 1662 LAD_Abregelung_BuchseTemp 0;
BA_ "Fehlerwert" SG_ 1662 LAD_MaxLadLeistung_HV 511;
BA_ "GenSigSwitchedByIgnition" SG_ 1662 LAD_MaxLadLeistung_HV 0;
BA_ "GenSigStartValue" SG_ 1662 LAD_MaxLadLeistung_HV 510;
BA_ "GenSigSendType" SG_ 1662 LAD_MaxLadLeistung_HV 0;
BA_ "Fehlerwert" SG_ 1662 LAD_CP_Stromlimit 127;
BA_ "GenSigSwitchedByIgnition" SG_ 1662 LAD_CP_Stromlimit 0;
BA_ "GenSigStartValue" SG_ 1662 LAD_CP_Stromlimit 126;
BA_ "GenSigSendType" SG_ 1662 LAD_CP_Stromlimit 0;
BA_ "Fehlerwert" SG_ 1662 LAD_PRX_Stromlimit 7;
BA_ "GenSigSwitchedByIgnition" SG_ 1662 LAD_PRX_Stromlimit 0;
BA_ "GenSigStartValue" SG_ 1662 LAD_PRX_Stromlimit 6;
BA_ "GenSigSendType" SG_ 1662 LAD_PRX_Stromlimit 0;
BA_ "GenSigSwitchedByIgnition" SG_ 1662 LAD_CP_Erkennung 0;
BA_ "GenSigSendType" SG_ 1662 LAD_CP_Erkennung 3;
BA_ "GenSigSwitchedByIgnition" SG_ 1662 LAD_Stecker_Verriegelt 0;
BA_ "GenSigSendType" SG_ 1662 LAD_Stecker_Verriegelt 0;
BA_ "GenSigSwitchedByIgnition" SG_ 1662 LAD_Stecker_Gesteckt 0;
BA_ "GenSigSendType" SG_ 1662 LAD_Stecker_Gesteckt 3;
BA_ "GenSigSwitchedByIgnition" SG_ 1662 LAD_Kuehlbedarf 0;
BA_ "GenSigSendType" SG_ 1662 LAD_Kuehlbedarf 0;
BA_ "GenSigSwitchedByIgnition" SG_ 1662 LAD_Warnzustand 0;
BA_ "GenSigSendType" SG_ 1662 LAD_Warnzustand 0;
BA_ "GenSigSwitchedByIgnition" SG_ 1662 LAD_Fehlerzustand 0;
BA_ "GenSigSendType" SG_ 1662 LAD_Fehlerzustand 0;
BA_ "GenSigSwitchedByIgnition" SG_ 810 EPS_01_CRC 0;
BA_ "GenSigFuncType" SG_ 810 EPS_01_CRC 2;
BA_ "GenSigSendType" SG_ 810 EPS_01_CRC 0;
BA_ "GenSigSwitchedByIgnition" SG_ 810 EPS_01_BZ 0;
BA_ "GenSigFuncType" SG_ 810 EPS_01_BZ 1;
BA_ "GenSigSendType" SG_ 810 EPS_01_BZ 0;
BA_ "GenSigSwitchedByIgnition" SG_ 810 EPS_SpannungsAnf 0;
BA_ "GenSigSendType" SG_ 810 EPS_SpannungsAnf 0;
BA_ "GenSigSwitchedByIgnition" SG_ 810 EPS_Akustiksignal 0;
BA_ "GenSigSendType" SG_ 810 EPS_Akustiksignal 0;
BA_ "GenSigSwitchedByIgnition" SG_ 810 EPS_Fehlerlampe 0;
BA_ "GenSigSendType" SG_ 810 EPS_Fehlerlampe 0;
BA_ "GenSigSwitchedByIgnition" SG_ 810 EPS_KD_Fehler 0;
BA_ "GenSigSendType" SG_ 810 EPS_KD_Fehler 0;
BA_ "GenSigSwitchedByIgnition" SG_ 810 EPS_Warnungen 0;
BA_ "GenSigSendType" SG_ 810 EPS_Warnungen 0;
BA_ "GenSigSwitchedByIgnition" SG_ 810 EPS_PLA_Abbruch 0;
BA_ "GenSigSendType" SG_ 810 EPS_PLA_Abbruch 0;
BA_ "GenSigSwitchedByIgnition" SG_ 810 EPS_PLA_Fehler 0;
BA_ "GenSigSendType" SG_ 810 EPS_PLA_Fehler 0;
BA_ "GenSigSwitchedByIgnition" SG_ 810 EPS_PLA_Status 0;
BA_ "GenSigSendType" SG_ 810 EPS_PLA_Status 0;
BA_ "GenSigSwitchedByIgnition" SG_ 810 EPS_Charisma_FahrPr 0;
BA_ "GenSigSendType" SG_ 810 EPS_Charisma_FahrPr 0;
BA_ "GenSigSwitchedByIgnition" SG_ 810 EPS_Charisma_Status 0;
BA_ "GenSigSendType" SG_ 810 EPS_Charisma_Status 0;
BA_ "GenSigSwitchedByIgnition" SG_ 810 EPS_Charisma_Umschaltung 0;
BA_ "GenSigSendType" SG_ 810 EPS_Charisma_Umschaltung 0;
BA_ "GenSigSwitchedByIgnition" SG_ 810 EPS_Lenkerposition 0;
BA_ "GenSigFuncType" SG_ 810 EPS_Lenkerposition 8;
BA_ "GenSigSendType" SG_ 810 EPS_Lenkerposition 0;
BA_ "GenSigSwitchedByIgnition" SG_ 810 EPS_Anf_KL 0;
BA_ "GenSigSendType" SG_ 810 EPS_Anf_KL 0;
BA_ "GenSigSwitchedByIgnition" SG_ 1137 Licht_hinten_01_BZ 0;
BA_ "GenSigFuncType" SG_ 1137 Licht_hinten_01_BZ 1;
BA_ "GenSigSendType" SG_ 1137 Licht_hinten_01_BZ 0;
BA_ "GenSigSwitchedByIgnition" SG_ 1137 BCM2_Bremsl_durch_ECD 0;
BA_ "GenSigSendType" SG_ 1137 BCM2_Bremsl_durch_ECD 0;
BA_ "GenSigSwitchedByIgnition" SG_ 1137 LH_Aussenlicht_def 0;
BA_ "GenSigSendType" SG_ 1137 LH_Aussenlicht_def 0;
BA_ "GenSigSwitchedByIgnition" SG_ 1137 LH_Standlicht_H_aktiv 0;
BA_ "GenSigSendType" SG_ 1137 LH_Standlicht_H_aktiv 0;
BA_ "GenSigSwitchedByIgnition" SG_ 1137 LH_Parklicht_HL_aktiv 0;
BA_ "GenSigSendType" SG_ 1137 LH_Parklicht_HL_aktiv 0;
BA_ "GenSigSwitchedByIgnition" SG_ 1137 LH_Parklicht_HR_aktiv 0;
BA_ "GenSigSendType" SG_ 1137 LH_Parklicht_HR_aktiv 0;
BA_ "GenSigSwitchedByIgnition" SG_ 1137 LH_Bremslicht_H_aktiv 0;
BA_ "GenSigSendType" SG_ 1137 LH_Bremslicht_H_aktiv 0;
BA_ "GenSigSwitchedByIgnition" SG_ 1137 LH_Nebelschluss_aktiv 0;
BA_ "GenSigSendType" SG_ 1137 LH_Nebelschluss_aktiv 0;
BA_ "GenSigSwitchedByIgnition" SG_ 1137 LH_Rueckfahrlicht_aktiv 0;
BA_ "GenSigSendType" SG_ 1137 LH_Rueckfahrlicht_aktiv 0;
BA_ "GenSigSwitchedByIgnition" SG_ 1137 LH_Blinker_HL_akt 0;
BA_ "GenSigSendType" SG_ 1137 LH_Blinker_HL_akt 0;
BA_ "GenSigSwitchedByIgnition" SG_ 1137 LH_Blinker_HR_akt 0;
BA_ "GenSigSendType" SG_ 1137 LH_Blinker_HR_akt 0;
BA_ "GenSigSwitchedByIgnition" SG_ 1137 LH_Blinker_li_def 0;
BA_ "GenSigSendType" SG_ 1137 LH_Blinker_li_def 0;
BA_ "GenSigSwitchedByIgnition" SG_ 1137 LH_Bremsl_li_def 0;
BA_ "GenSigSendType" SG_ 1137 LH_Bremsl_li_def 0;
BA_ "GenSigSwitchedByIgnition" SG_ 1137 LH_Schlusslicht_li_def 0;
BA_ "GenSigSendType" SG_ 1137 LH_Schlusslicht_li_def 0;
BA_ "GenSigSwitchedByIgnition" SG_ 1137 LH_Rueckf_li_def 0;
BA_ "GenSigSendType" SG_ 1137 LH_Rueckf_li_def 0;
BA_ "GenSigSwitchedByIgnition" SG_ 1137 LH_Nebel_li_def 0;
BA_ "GenSigSendType" SG_ 1137 LH_Nebel_li_def 0;
BA_ "GenSigSwitchedByIgnition" SG_ 1137 LH_Schluss_Brems_Nebel_li_def 0;
BA_ "GenSigSendType" SG_ 1137 LH_Schluss_Brems_Nebel_li_def 0;
BA_ "GenSigSwitchedByIgnition" SG_ 1137 LH_Schluss_Brems_Nebel_re_def 0;
BA_ "GenSigSendType" SG_ 1137 LH_Schluss_Brems_Nebel_re_def 0;
BA_ "GenSigSwitchedByIgnition" SG_ 1137 LH_Schluss_Brems_li_def 0;
BA_ "GenSigSendType" SG_ 1137 LH_Schluss_Brems_li_def 0;
BA_ "GenSigSwitchedByIgnition" SG_ 1137 LH_Schluss_Nebel_li_def 0;
BA_ "GenSigSendType" SG_ 1137 LH_Schluss_Nebel_li_def 0;
BA_ "GenSigSwitchedByIgnition" SG_ 1137 LH_SL_BRL_BLK_li_def 0;
BA_ "GenSigSendType" SG_ 1137 LH_SL_BRL_BLK_li_def 0;
BA_ "GenSigSwitchedByIgnition" SG_ 1137 LH_Brems_Blk_li_def 0;
BA_ "GenSigSendType" SG_ 1137 LH_Brems_Blk_li_def 0;
BA_ "GenSigSwitchedByIgnition" SG_ 1137 LH_Blinker_re_def 0;
BA_ "GenSigSendType" SG_ 1137 LH_Blinker_re_def 0;
BA_ "GenSigSwitchedByIgnition" SG_ 1137 LH_Bremsl_re_def 0;
BA_ "GenSigSendType" SG_ 1137 LH_Bremsl_re_def 0;
BA_ "GenSigSwitchedByIgnition" SG_ 1137 LH_Schlusslicht_re_def 0;
BA_ "GenSigSendType" SG_ 1137 LH_Schlusslicht_re_def 0;
BA_ "GenSigSwitchedByIgnition" SG_ 1137 LH_Rueckf_re_def 0;
BA_ "GenSigSendType" SG_ 1137 LH_Rueckf_re_def 0;
BA_ "GenSigSwitchedByIgnition" SG_ 1137 LH_Nebel_re_def 0;
BA_ "GenSigSendType" SG_ 1137 LH_Nebel_re_def 0;
BA_ "GenSigSwitchedByIgnition" SG_ 1137 LH_Schluss_Brems_re_def 0;
BA_ "GenSigSendType" SG_ 1137 LH_Schluss_Brems_re_def 0;
BA_ "GenSigSwitchedByIgnition" SG_ 1137 LH_Schluss_Nebel_re_def 0;
BA_ "GenSigSendType" SG_ 1137 LH_Schluss_Nebel_re_def 0;
BA_ "GenSigSwitchedByIgnition" SG_ 1137 LH_SL_BRL_BLK_re_def 0;
BA_ "GenSigSendType" SG_ 1137 LH_SL_BRL_BLK_re_def 0;
BA_ "GenSigSwitchedByIgnition" SG_ 1137 LH_Brems_Blk_re_def 0;
BA_ "GenSigSendType" SG_ 1137 LH_Brems_Blk_re_def 0;
BA_ "GenSigSwitchedByIgnition" SG_ 1137 LH_Kennzl_def 0;
BA_ "GenSigSendType" SG_ 1137 LH_Kennzl_def 0;
BA_ "GenSigSwitchedByIgnition" SG_ 1137 LH_3_Bremsl_def 0;
BA_ "GenSigSendType" SG_ 1137 LH_3_Bremsl_def 0;
BA_ "GenSigSwitchedByIgnition" SG_ 1137 LH_Nebel_mi_def 0;
BA_ "GenSigSendType" SG_ 1137 LH_Nebel_mi_def 0;
BA_ "GenSigSwitchedByIgnition" SG_ 1137 LH_Rueckf_mi_def 0;
BA_ "GenSigSendType" SG_ 1137 LH_Rueckf_mi_def 0;
BA_ "GenSigSwitchedByIgnition" SG_ 1137 LH_Bremsl_li_ges_def 0;
BA_ "GenSigSendType" SG_ 1137 LH_Bremsl_li_ges_def 0;
BA_ "GenSigSwitchedByIgnition" SG_ 1137 LH_Bremsl_re_ges_def 0;
BA_ "GenSigSendType" SG_ 1137 LH_Bremsl_re_ges_def 0;
BA_ "Fehlerwert" SG_ 1321 Lift_Status 7;
BA_ "GenSigSendType" SG_ 1321 Lift_Status 3;
BA_ "GenSigSwitchedByIgnition" SG_ 1321 Lift_Charisma_FahrPr 0;
BA_ "GenSigSendType" SG_ 1321 Lift_Charisma_FahrPr 3;
BA_ "GenSigSwitchedByIgnition" SG_ 1321 Lift_Charisma_Status 0;
BA_ "GenSigSendType" SG_ 1321 Lift_Charisma_Status 0;
BA_ "GenSigSwitchedByIgnition" SG_ 1321 Lift_Charisma_Umschaltung 0;
BA_ "GenSigSendType" SG_ 1321 Lift_Charisma_Umschaltung 3;
BA_ "GenSigSendType" SG_ 1321 Lift_KD_Fehler 0;
BA_ "GenSigSendType" SG_ 917 AFS_Abbiegelicht_li_Anf 0;
BA_ "GenSigSendType" SG_ 917 AFS_Abbiegelicht_re_Anf 0;
BA_ "GenSigSendType" SG_ 917 AFS_Abbiegelicht_Dimm_Anf 0;
BA_ "GenSigStartValue" SG_ 917 AFS_Verfuegbarkeit_GLW 1;
BA_ "GenSigSendType" SG_ 917 AFS_Verfuegbarkeit_GLW 0;
BA_ "GenSigStartValue" SG_ 917 AFS_Status_adaptive_LV 1;
BA_ "GenSigSendType" SG_ 917 AFS_Status_adaptive_LV 0;
BA_ "GenSigSendType" SG_ 917 AFS_Fernlicht_li_defekt 0;
BA_ "GenSigSendType" SG_ 917 AFS_Fernlicht_re_defekt 0;
BA_ "GenSigSendType" SG_ 917 AFS_Fernlicht_Status 0;
BA_ "GenSigFuncType" SG_ 917 LWR_AFS_01_BZ 1;
BA_ "GenSigSendType" SG_ 917 LWR_AFS_01_BZ 0;
BA_ "GenSigSendType" SG_ 917 AFS_Lampe 0;
BA_ "GenSigSendType" SG_ 917 LWR_Lampe 0;
BA_ "GenSigSendType" SG_ 917 AFS_Fehlertext 0;
BA_ "GenSigSendType" SG_ 917 AFS_LED_Blinkmode 0;
BA_ "GenSigSendType" SG_ 917 LWR_Touristenmodus_aktiv 0;
BA_ "GenSigSendType" SG_ 917 AFS_Charisma_FahrPr 0;
BA_ "GenSigSendType" SG_ 917 AFS_Charisma_Status 0;
BA_ "GenSigSendType" SG_ 917 AFS_Charisma_Umschaltung 0;
BA_ "GenSigSendType" SG_ 917 AFS_Allwetterlicht 0;
BA_ "GenSigSendType" SG_ 917 LWR_Touristenmodus_verbaut 0;
BA_ "GenSigSendType" SG_ 917 AFS_adaptive_LV_verbaut 0;
BA_ "GenSigSendType" SG_ 917 LWR_Reisemodus_Texte 0;
BA_ "GenSigSendType" SG_ 917 GLW_Sensor_blockiert 0;
BA_ "Fehlerwert" SG_ 917 LWR_Pos_Schrittmotor 255;
BA_ "GenSigStartValue" SG_ 917 LWR_Pos_Schrittmotor 254;
BA_ "GenSigSendType" SG_ 917 LWR_Pos_Schrittmotor 0;
BA_ "Fehlerwert" SG_ 917 LWR_Hoehenwert_VL 255;
BA_ "GenSigStartValue" SG_ 917 LWR_Hoehenwert_VL 254;
BA_ "GenSigSendType" SG_ 917 LWR_Hoehenwert_VL 0;
BA_ "Fehlerwert" SG_ 917 LWR_Hoehenwert_HL 255;
BA_ "GenSigStartValue" SG_ 917 LWR_Hoehenwert_HL 254;
BA_ "GenSigSendType" SG_ 917 LWR_Hoehenwert_HL 0;
BA_ "GenSigSendType" SG_ 917 AFS_Ersatzlicht_Links 0;
BA_ "GenSigSendType" SG_ 917 AFS_Ersatzlicht_Rechts 0;
BA_ "GenSigSendType" SG_ 917 LWR_AFS_Grundeinstellung 0;
BA_ "GenSigSendType" SG_ 917 LWR_AFS_Parametrisierung 0;
BA_ "GenSigSendType" SG_ 917 LWR_Initialisierungslauf 0;
BA_ "GenSigSendType" SG_ 917 LWR_Sicherheitsposition 0;
BA_ "GenSigSendType" SG_ 917 LWR_Modus 0;
BA_ "GenSigSendType" SG_ 917 LWR_KD_Fehler 0;
BA_ "GenSigSwitchedByIgnition" SG_ 1704 KBI_Aussenspiegel_absenken_auto 0;
BA_ "GenSigSendType" SG_ 1704 KBI_Aussenspiegel_absenken_auto 3;
BA_ "GenSigSwitchedByIgnition" SG_ 1704 KBI_Aussenspiegel_einklapp_auto 0;
BA_ "GenSigSendType" SG_ 1704 KBI_Aussenspiegel_einklapp_auto 3;
BA_ "GenSigSwitchedByIgnition" SG_ 1704 KBI_Schaltpkt_Anz_ein 0;
BA_ "GenSigSendType" SG_ 1704 KBI_Schaltpkt_Anz_ein 3;
BA_ "GenSigSwitchedByIgnition" SG_ 1704 KBI_FULL_AFS_Tourist 0;
BA_ "NWM-WakeupAllowed" SG_ 1704 KBI_FULL_AFS_Tourist 1;
BA_ "GenSigSendType" SG_ 1704 KBI_FULL_AFS_Tourist 3;
BA_ "GenSigSwitchedByIgnition" SG_ 1704 KBI_Einstiegshilfe_aktiv 0;
BA_ "GenSigSendType" SG_ 1704 KBI_Einstiegshilfe_aktiv 3;
BA_ "GenSigSwitchedByIgnition" SG_ 1704 KBI_Schneekettenmodus_Aktiv 0;
BA_ "GenSigSendType" SG_ 1704 KBI_Schneekettenmodus_Aktiv 3;
BA_ "GenSigSwitchedByIgnition" SG_ 1704 KBI_FLA_GLW_Aktiv 0;
BA_ "GenSigSendType" SG_ 1704 KBI_FLA_GLW_Aktiv 3;
BA_ "GenSigSwitchedByIgnition" SG_ 1704 KBI_Dimmung_OriLicht 0;
BA_ "GenSigSendType" SG_ 1704 KBI_Dimmung_OriLicht 3;
BA_ "GenSigSwitchedByIgnition" SG_ 1704 KBI_RS_d_akt 0;
BA_ "GenSigSendType" SG_ 1704 KBI_RS_d_akt 3;
BA_ "GenSigSwitchedByIgnition" SG_ 1704 KBI_Nachleucht_IL 0;
BA_ "GenSigSendType" SG_ 1704 KBI_Nachleucht_IL 3;
BA_ "GenSigSwitchedByIgnition" SG_ 1704 KBI_Erw_BelueftFeld 0;
BA_ "GenSigSendType" SG_ 1704 KBI_Erw_BelueftFeld 3;
BA_ "GenSigSwitchedByIgnition" SG_ 1704 KBI_Auto_Umluft 0;
BA_ "GenSigSendType" SG_ 1704 KBI_Auto_Umluft 3;
BA_ "GenSigSwitchedByIgnition" SG_ 1704 KBI_Heckrollo_b_R 0;
BA_ "NWM-WakeupAllowed" SG_ 1704 KBI_Heckrollo_b_R 1;
BA_ "GenSigSendType" SG_ 1704 KBI_Heckrollo_b_R 3;
BA_ "GenSigSwitchedByIgnition" SG_ 1704 KBI_Nachleucht 0;
BA_ "GenSigSendType" SG_ 1704 KBI_Nachleucht 3;
BA_ "GenSigSwitchedByIgnition" SG_ 1704 KBI_TFL_akt 0;
BA_ "GenSigSendType" SG_ 1704 KBI_TFL_akt 3;
BA_ "GenSigSwitchedByIgnition" SG_ 1704 KBI_Heckw_b_R 0;
BA_ "GenSigSendType" SG_ 1704 KBI_Heckw_b_R 3;
BA_ "GenSigSwitchedByIgnition" SG_ 1704 KBI_WV_Entr 0;
BA_ "GenSigSendType" SG_ 1704 KBI_WV_Entr 3;
BA_ "GenSigSwitchedByIgnition" SG_ 1704 KBI_Tuerentr_T 0;
BA_ "GenSigSendType" SG_ 1704 KBI_Tuerentr_T 3;
BA_ "GenSigSwitchedByIgnition" SG_ 1704 KBI_Carjack 0;
BA_ "GenSigSendType" SG_ 1704 KBI_Carjack 3;
BA_ "GenSigSwitchedByIgnition" SG_ 1704 KBI_WV_Entr_Kof 0;
BA_ "GenSigSendType" SG_ 1704 KBI_WV_Entr_Kof 3;
BA_ "GenSigSwitchedByIgnition" SG_ 1704 KBI_Automem_Inaktiv 0;
BA_ "GenSigSendType" SG_ 1704 KBI_Automem_Inaktiv 3;
BA_ "GenSigSwitchedByIgnition" SG_ 1704 KBI_Jokerkey_Hupe_Aktiv 0;
BA_ "GenSigSendType" SG_ 1704 KBI_Jokerkey_Hupe_Aktiv 3;
BA_ "GenSigSwitchedByIgnition" SG_ 1704 KBI_LDW_aktiv 0;
BA_ "GenSigSendType" SG_ 1704 KBI_LDW_aktiv 3;
BA_ "GenSigSwitchedByIgnition" SG_ 1704 KBI_PTC_Zuheizer 0;
BA_ "GenSigSendType" SG_ 1704 KBI_PTC_Zuheizer 3;
BA_ "GenSigSwitchedByIgnition" SG_ 1704 KBI_Steigerung_Luftmenge_Fond 0;
BA_ "GenSigSendType" SG_ 1704 KBI_Steigerung_Luftmenge_Fond 3;
BA_ "GenSigSwitchedByIgnition" SG_ 1704 KBI_Klimastyles 0;
BA_ "GenSigSendType" SG_ 1704 KBI_Klimastyles 3;
BA_ "GenSigSwitchedByIgnition" SG_ 1704 KBI_Mittenduesentemp 0;
BA_ "GenSigSendType" SG_ 1704 KBI_Mittenduesentemp 3;
BA_ "GenSigMissingSourceValue" SG_ 1704 KBI_Dimmung_AmbLicht 255;
BA_ "Fehlerwert" SG_ 1704 KBI_Dimmung_AmbLicht 127;
BA_ "GenSigSwitchedByIgnition" SG_ 1704 KBI_Dimmung_AmbLicht 0;
BA_ "GenSigStartValue" SG_ 1704 KBI_Dimmung_AmbLicht 126;
BA_ "GenSigSendType" SG_ 1704 KBI_Dimmung_AmbLicht 0;
BA_ "GenSigSwitchedByIgnition" SG_ 1704 KBI_Innenlicht_per_Tuerkontakt 0;
BA_ "GenSigSendType" SG_ 1704 KBI_Innenlicht_per_Tuerkontakt 3;
BA_ "GenSigSwitchedByIgnition" SG_ 1471 MFL_Tastencode_1 0;
BA_ "GenSigSendType" SG_ 1471 MFL_Tastencode_1 9;
BA_ "GenSigSwitchedByIgnition" SG_ 1471 MFL_Tastencode_2 0;
BA_ "GenSigSendType" SG_ 1471 MFL_Tastencode_2 9;
BA_ "GenSigSwitchedByIgnition" SG_ 1471 MFL_Eventcode_1 0;
BA_ "GenSigSendType" SG_ 1471 MFL_Eventcode_1 9;
BA_ "GenSigSwitchedByIgnition" SG_ 1471 MFL_Eventcode_2 0;
BA_ "GenSigSendType" SG_ 1471 MFL_Eventcode_2 9;
BA_ "GenSigSwitchedByIgnition" SG_ 1471 MFL_Marke 0;
BA_ "GenSigFuncType" SG_ 1471 MFL_Marke 8;
BA_ "GenSigSwitchedByIgnition" SG_ 1471 MFL_Variante 0;
BA_ "GenSigFuncType" SG_ 1471 MFL_Variante 8;
BA_ "GenSigSwitchedByIgnition" SG_ 193 Miko_KD_Fehler 0;
BA_ "GenSigSendType" SG_ 193 Miko_KD_Fehler 0;
BA_ "GenSigSwitchedByIgnition" SG_ 193 Miko_T_Defrost 0;
BA_ "NWM-WakeupAllowed" SG_ 193 Miko_T_Defrost 1;
BA_ "GenSigSendType" SG_ 193 Miko_T_Defrost 4;
BA_ "GenSigSwitchedByIgnition" SG_ 193 Miko_T_Auto 0;
BA_ "NWM-WakeupAllowed" SG_ 193 Miko_T_Auto 1;
BA_ "GenSigSendType" SG_ 193 Miko_T_Auto 4;
BA_ "GenSigSwitchedByIgnition" SG_ 193 Miko_T_Source 0;
BA_ "NWM-WakeupAllowed" SG_ 193 Miko_T_Source 1;
BA_ "GenSigSendType" SG_ 193 Miko_T_Source 4;
BA_ "GenSigSwitchedByIgnition" SG_ 193 Miko_T_AC_Menue 0;
BA_ "NWM-WakeupAllowed" SG_ 193 Miko_T_AC_Menue 1;
BA_ "GenSigSendType" SG_ 193 Miko_T_AC_Menue 4;
BA_ "GenSigSwitchedByIgnition" SG_ 193 Miko_T_Phone 0;
BA_ "NWM-WakeupAllowed" SG_ 193 Miko_T_Phone 1;
BA_ "GenSigSendType" SG_ 193 Miko_T_Phone 4;
BA_ "GenSigSwitchedByIgnition" SG_ 193 Miko_T_Media 0;
BA_ "NWM-WakeupAllowed" SG_ 193 Miko_T_Media 1;
BA_ "GenSigSendType" SG_ 193 Miko_T_Media 4;
BA_ "GenSigSwitchedByIgnition" SG_ 193 Miko_T_Tuner 0;
BA_ "NWM-WakeupAllowed" SG_ 193 Miko_T_Tuner 1;
BA_ "GenSigSendType" SG_ 193 Miko_T_Tuner 4;
BA_ "GenSigSwitchedByIgnition" SG_ 193 Miko_T_Back 0;
BA_ "NWM-WakeupAllowed" SG_ 193 Miko_T_Back 1;
BA_ "GenSigSendType" SG_ 193 Miko_T_Back 4;
BA_ "GenSigSwitchedByIgnition" SG_ 193 Miko_T_Option 0;
BA_ "NWM-WakeupAllowed" SG_ 193 Miko_T_Option 1;
BA_ "GenSigSendType" SG_ 193 Miko_T_Option 4;
BA_ "GenSigSwitchedByIgnition" SG_ 193 Miko_T_Car 0;
BA_ "NWM-WakeupAllowed" SG_ 193 Miko_T_Car 1;
BA_ "GenSigSendType" SG_ 193 Miko_T_Car 4;
BA_ "GenSigSwitchedByIgnition" SG_ 193 Miko_T_Info 0;
BA_ "NWM-WakeupAllowed" SG_ 193 Miko_T_Info 1;
BA_ "GenSigSendType" SG_ 193 Miko_T_Info 4;
BA_ "GenSigSwitchedByIgnition" SG_ 193 Miko_T_Navi 0;
BA_ "NWM-WakeupAllowed" SG_ 193 Miko_T_Navi 1;
BA_ "GenSigSendType" SG_ 193 Miko_T_Navi 4;
BA_ "GenSigSwitchedByIgnition" SG_ 193 Miko_T_Umluft 0;
BA_ "NWM-WakeupAllowed" SG_ 193 Miko_T_Umluft 1;
BA_ "GenSigSendType" SG_ 193 Miko_T_Umluft 4;
BA_ "GenSigSwitchedByIgnition" SG_ 193 Miko_T_AC 0;
BA_ "NWM-WakeupAllowed" SG_ 193 Miko_T_AC 1;
BA_ "GenSigSendType" SG_ 193 Miko_T_AC 4;
BA_ "GenSigSwitchedByIgnition" SG_ 193 Miko_T_Acmax 0;
BA_ "NWM-WakeupAllowed" SG_ 193 Miko_T_Acmax 1;
BA_ "GenSigSendType" SG_ 193 Miko_T_Acmax 4;
BA_ "GenSigSwitchedByIgnition" SG_ 193 Miko_Volume 0;
BA_ "NWM-WakeupAllowed" SG_ 193 Miko_Volume 1;
BA_ "GenSigSendType" SG_ 193 Miko_Volume 5;
BA_ "GenSigSwitchedByIgnition" SG_ 193 Miko_Volume_Err 0;
BA_ "NWM-WakeupAllowed" SG_ 193 Miko_Volume_Err 1;
BA_ "GenSigSendType" SG_ 193 Miko_Volume_Err 3;
BA_ "GenSigSwitchedByIgnition" SG_ 193 Miko_Volume_dir 0;
BA_ "NWM-WakeupAllowed" SG_ 193 Miko_Volume_dir 1;
BA_ "GenSigSendType" SG_ 193 Miko_Volume_dir 3;
BA_ "Fehlerwert" SG_ 193 Miko_Volume_press 3;
BA_ "GenSigSwitchedByIgnition" SG_ 193 Miko_Volume_press 0;
BA_ "NWM-WakeupAllowed" SG_ 193 Miko_Volume_press 1;
BA_ "GenSigSendType" SG_ 193 Miko_Volume_press 3;
BA_ "GenSigSwitchedByIgnition" SG_ 193 Miko_MMI 0;
BA_ "NWM-WakeupAllowed" SG_ 193 Miko_MMI 1;
BA_ "GenSigSendType" SG_ 193 Miko_MMI 5;
BA_ "GenSigSwitchedByIgnition" SG_ 193 Miko_MMI_fast 0;
BA_ "NWM-WakeupAllowed" SG_ 193 Miko_MMI_fast 1;
BA_ "GenSigSendType" SG_ 193 Miko_MMI_fast 3;
BA_ "GenSigSwitchedByIgnition" SG_ 193 Miko_MMI_Err 0;
BA_ "NWM-WakeupAllowed" SG_ 193 Miko_MMI_Err 1;
BA_ "GenSigSendType" SG_ 193 Miko_MMI_Err 3;
BA_ "GenSigSwitchedByIgnition" SG_ 193 Miko_MMI_dir 0;
BA_ "NWM-WakeupAllowed" SG_ 193 Miko_MMI_dir 1;
BA_ "GenSigSendType" SG_ 193 Miko_MMI_dir 3;
BA_ "Fehlerwert" SG_ 193 Miko_MMI_press 3;
BA_ "GenSigSwitchedByIgnition" SG_ 193 Miko_MMI_press 0;
BA_ "NWM-WakeupAllowed" SG_ 193 Miko_MMI_press 1;
BA_ "GenSigSendType" SG_ 193 Miko_MMI_press 3;
BA_ "GenSigSwitchedByIgnition" SG_ 193 Miko_Clima 0;
BA_ "NWM-WakeupAllowed" SG_ 193 Miko_Clima 1;
BA_ "GenSigSendType" SG_ 193 Miko_Clima 5;
BA_ "GenSigSwitchedByIgnition" SG_ 193 Miko_Clima_fast 0;
BA_ "NWM-WakeupAllowed" SG_ 193 Miko_Clima_fast 1;
BA_ "GenSigSendType" SG_ 193 Miko_Clima_fast 3;
BA_ "GenSigSwitchedByIgnition" SG_ 193 Miko_Clima_Err 0;
BA_ "NWM-WakeupAllowed" SG_ 193 Miko_Clima_Err 1;
BA_ "GenSigSendType" SG_ 193 Miko_Clima_Err 3;
BA_ "GenSigSwitchedByIgnition" SG_ 193 Miko_Clima_dir 0;
BA_ "NWM-WakeupAllowed" SG_ 193 Miko_Clima_dir 1;
BA_ "GenSigSendType" SG_ 193 Miko_Clima_dir 3;
BA_ "Fehlerwert" SG_ 193 Miko_Clima_press 3;
BA_ "GenSigSwitchedByIgnition" SG_ 193 Miko_Clima_press 0;
BA_ "NWM-WakeupAllowed" SG_ 193 Miko_Clima_press 1;
BA_ "GenSigSendType" SG_ 193 Miko_Clima_press 3;
BA_ "GenSigSwitchedByIgnition" SG_ 193 Miko_ADR_Reset 0;
BA_ "NWM-WakeupAllowed" SG_ 193 Miko_ADR_Reset 1;
BA_ "GenSigSendType" SG_ 193 Miko_ADR_Reset 0;
BA_ "GenSigSwitchedByIgnition" SG_ 193 Miko_ADR_UltralongPress 0;
BA_ "NWM-WakeupAllowed" SG_ 193 Miko_ADR_UltralongPress 1;
BA_ "GenSigSendType" SG_ 193 Miko_ADR_UltralongPress 0;
BA_ "GenSigSwitchedByIgnition" SG_ 193 Miko_T_Blower 0;
BA_ "NWM-WakeupAllowed" SG_ 193 Miko_T_Blower 1;
BA_ "GenSigSendType" SG_ 193 Miko_T_Blower 4;
BA_ "GenSigSwitchedByIgnition" SG_ 193 Miko_T_Temp_left 0;
BA_ "NWM-WakeupAllowed" SG_ 193 Miko_T_Temp_left 1;
BA_ "GenSigSendType" SG_ 193 Miko_T_Temp_left 4;
BA_ "GenSigSwitchedByIgnition" SG_ 193 Miko_T_Temp_right 0;
BA_ "NWM-WakeupAllowed" SG_ 193 Miko_T_Temp_right 1;
BA_ "GenSigSendType" SG_ 193 Miko_T_Temp_right 4;
BA_ "GenSigSwitchedByIgnition" SG_ 126 Motor_02_CHK_sek 0;
BA_ "GenSigFuncType" SG_ 126 Motor_02_CHK_sek 4;
BA_ "GenSigSendType" SG_ 126 Motor_02_CHK_sek 0;
BA_ "GenSigSwitchedByIgnition" SG_ 126 Motor_02_BZ_sek 0;
BA_ "GenSigFuncType" SG_ 126 Motor_02_BZ_sek 1;
BA_ "GenSigSendType" SG_ 126 Motor_02_BZ_sek 0;
BA_ "GenSigSwitchedByIgnition" SG_ 126 MO_Faktor_Momente_sek 0;
BA_ "GenSigFuncType" SG_ 126 MO_Faktor_Momente_sek 8;
BA_ "GenSigSendType" SG_ 126 MO_Faktor_Momente_sek 0;
BA_ "Fehlerwert" SG_ 126 Enrgfluss_State_BN 3;
BA_ "GenSigSwitchedByIgnition" SG_ 126 Enrgfluss_State_BN 0;
BA_ "GenSigSendType" SG_ 126 Enrgfluss_State_BN 0;
BA_ "Fehlerwert" SG_ 126 Enrgfluss_State_sek 3;
BA_ "GenSigSwitchedByIgnition" SG_ 126 Enrgfluss_State_sek 0;
BA_ "GenSigSendType" SG_ 126 Enrgfluss_State_sek 0;
BA_ "Fehlerwert" SG_ 126 MO_Mom_Soll_sek 1023;
BA_ "GenSigSwitchedByIgnition" SG_ 126 MO_Mom_Soll_sek 0;
BA_ "GenSigStartValue" SG_ 126 MO_Mom_Soll_sek 1022;
BA_ "GenSigSendType" SG_ 126 MO_Mom_Soll_sek 0;
BA_ "Fehlerwert" SG_ 126 MO_Mom_Ist_sek 1023;
BA_ "GenSigSwitchedByIgnition" SG_ 126 MO_Mom_Ist_sek 0;
BA_ "GenSigStartValue" SG_ 126 MO_Mom_Ist_sek 1022;
BA_ "GenSigSendType" SG_ 126 MO_Mom_Ist_sek 0;
BA_ "Fehlerwert" SG_ 126 MO_Faktor_Getriebe 255;
BA_ "GenSigSwitchedByIgnition" SG_ 126 MO_Faktor_Getriebe 0;
BA_ "GenSigStartValue" SG_ 126 MO_Faktor_Getriebe 254;
BA_ "GenSigSendType" SG_ 126 MO_Faktor_Getriebe 0;
BA_ "Fehlerwert" SG_ 263 MO_rel_Ladedruck 255;
BA_ "GenSigSwitchedByIgnition" SG_ 263 MO_rel_Ladedruck 0;
BA_ "GenSigSendType" SG_ 263 MO_rel_Ladedruck 0;
BA_ "GenSigSwitchedByIgnition" SG_ 263 MO_Istgang 0;
BA_ "GenSigSendType" SG_ 263 MO_Istgang 0;
BA_ "GenSigSwitchedByIgnition" SG_ 263 MO_Sollgang 0;
BA_ "GenSigSendType" SG_ 263 MO_Sollgang 0;
BA_ "Fehlerwert" SG_ 263 MO_Oeldruck 255;
BA_ "GenSigSwitchedByIgnition" SG_ 263 MO_Oeldruck 0;
BA_ "GenSigStartValue" SG_ 263 MO_Oeldruck 254;
BA_ "GenSigSendType" SG_ 263 MO_Oeldruck 0;
BA_ "Fehlerwert" SG_ 263 MO_Anzeigedrehz 4095;
BA_ "GenSigSwitchedByIgnition" SG_ 263 MO_Anzeigedrehz 0;
BA_ "GenSigSendType" SG_ 263 MO_Anzeigedrehz 0;
BA_ "GenSigSwitchedByIgnition" SG_ 263 MO_Effizienzmodus 0;
BA_ "GenSigSendType" SG_ 263 MO_Effizienzmodus 0;
BA_ "GenSigSwitchedByIgnition" SG_ 263 MO_Schaltempf_verfbar 0;
BA_ "GenSigFuncType" SG_ 263 MO_Schaltempf_verfbar 8;
BA_ "GenSigSendType" SG_ 263 MO_Schaltempf_verfbar 0;
BA_ "Fehlerwert" SG_ 263 MO_Ladedruck 511;
BA_ "GenSigSwitchedByIgnition" SG_ 263 MO_Ladedruck 0;
BA_ "GenSigSendType" SG_ 263 MO_Ladedruck 0;
BA_ "GenSigSwitchedByIgnition" SG_ 263 MO_KVS 0;
BA_ "GenSigSendType" SG_ 263 MO_KVS 0;
BA_ "GenSigSwitchedByIgnition" SG_ 263 MO_KVS_Ueberlauf 0;
BA_ "GenSigSendType" SG_ 263 MO_KVS_Ueberlauf 0;
BA_ "GenSigSwitchedByIgnition" SG_ 782 Motor_05_CHK 0;
BA_ "GenSigFuncType" SG_ 782 Motor_05_CHK 3;
BA_ "GenSigSendType" SG_ 782 Motor_05_CHK 0;
BA_ "GenSigSwitchedByIgnition" SG_ 782 Motor_05_BZ 0;
BA_ "GenSigFuncType" SG_ 782 Motor_05_BZ 1;
BA_ "GenSigSendType" SG_ 782 Motor_05_BZ 0;
BA_ "GenSigSwitchedByIgnition" SG_ 782 MO_EKlKomLeiRed 0;
BA_ "GenSigSendType" SG_ 782 MO_EKlKomLeiRed 0;
BA_ "GenSigSwitchedByIgnition" SG_ 782 MO_Freig_Reku 0;
BA_ "GenSigSendType" SG_ 782 MO_Freig_Reku 0;
BA_ "GenSigSwitchedByIgnition" SG_ 782 MO_Klima_Eingr 0;
BA_ "GenSigSendType" SG_ 782 MO_Klima_Eingr 0;
BA_ "GenSigSwitchedByIgnition" SG_ 782 MO_Status_Normalbetrieb_02 0;
BA_ "GenSigSendType" SG_ 782 MO_Status_Normalbetrieb_02 0;
BA_ "GenSigSwitchedByIgnition" SG_ 782 MO_Schaltbeeinfl_Leistungsbegr 0;
BA_ "GenSigSendType" SG_ 782 MO_Schaltbeeinfl_Leistungsbegr 0;
BA_ "GenSigSwitchedByIgnition" SG_ 782 MO_Schaltbeeinfl_Partikelfilter 0;
BA_ "GenSigSendType" SG_ 782 MO_Schaltbeeinfl_Partikelfilter 0;
BA_ "GenSigSwitchedByIgnition" SG_ 782 MO_Prio_MIN_Wunschdrehzahl 0;
BA_ "GenSigSendType" SG_ 782 MO_Prio_MIN_Wunschdrehzahl 0;
BA_ "GenSigSwitchedByIgnition" SG_ 782 MO_Freig_Anlass 0;
BA_ "GenSigSendType" SG_ 782 MO_Freig_Anlass 0;
BA_ "GenSigSwitchedByIgnition" SG_ 782 MO_Aussp_Anlass 0;
BA_ "GenSigSendType" SG_ 782 MO_Aussp_Anlass 0;
BA_ "Fehlerwert" SG_ 782 MO_MAX_Wunschdrehzahl 511;
BA_ "GenSigSwitchedByIgnition" SG_ 782 MO_MAX_Wunschdrehzahl 0;
BA_ "GenSigSendType" SG_ 782 MO_MAX_Wunschdrehzahl 0;
BA_ "GenSigSwitchedByIgnition" SG_ 782 MO_Prio_MAX_Wunschdrehzahl 0;
BA_ "GenSigSendType" SG_ 782 MO_Prio_MAX_Wunschdrehzahl 0;
BA_ "GenSigSwitchedByIgnition" SG_ 782 MO_Luftpfad_aktiv 0;
BA_ "GenSigSendType" SG_ 782 MO_Luftpfad_aktiv 0;
BA_ "GenSigSwitchedByIgnition" SG_ 782 MO_v_Begrenz_Aktiv 0;
BA_ "GenSigSendType" SG_ 782 MO_v_Begrenz_Aktiv 0;
BA_ "GenSigSwitchedByIgnition" SG_ 782 MO_v_Begrenz_Aktivierbar 0;
BA_ "GenSigSendType" SG_ 782 MO_v_Begrenz_Aktivierbar 0;
BA_ "GenSigSwitchedByIgnition" SG_ 782 MO_Verbot_EKP 0;
BA_ "GenSigSendType" SG_ 782 MO_Verbot_EKP 0;
BA_ "GenSigSwitchedByIgnition" SG_ 782 MO_Anf_Pruefimpuls 0;
BA_ "GenSigSendType" SG_ 782 MO_Anf_Pruefimpuls 0;
BA_ "GenSigSwitchedByIgnition" SG_ 782 MO_Anf_KL75 0;
BA_ "GenSigStartValue" SG_ 782 MO_Anf_KL75 1;
BA_ "GenSigSendType" SG_ 782 MO_Anf_KL75 0;
BA_ "GenSigSwitchedByIgnition" SG_ 782 MO_Charisma_FahrPr 0;
BA_ "GenSigSendType" SG_ 782 MO_Charisma_FahrPr 0;
BA_ "GenSigSwitchedByIgnition" SG_ 782 MO_Charisma_Status 0;
BA_ "GenSigSendType" SG_ 782 MO_Charisma_Status 0;
BA_ "GenSigSwitchedByIgnition" SG_ 782 MO_Charisma_Umschaltung 0;
BA_ "GenSigSendType" SG_ 782 MO_Charisma_Umschaltung 0;
BA_ "GenSigSwitchedByIgnition" SG_ 782 MO_Handshake_STH 0;
BA_ "GenSigSendType" SG_ 782 MO_Handshake_STH 0;
BA_ "Fehlerwert" SG_ 782 MO_MIN_Wunschdrehzahl 255;
BA_ "GenSigSwitchedByIgnition" SG_ 782 MO_MIN_Wunschdrehzahl 0;
BA_ "GenSigSendType" SG_ 782 MO_MIN_Wunschdrehzahl 0;
BA_ "GenSigSwitchedByIgnition" SG_ 782 MO_Drehzahlbeeinflussung 0;
BA_ "GenSigSendType" SG_ 782 MO_Drehzahlbeeinflussung 0;
BA_ "GenSigSwitchedByIgnition" SG_ 1088 MO_Kuehlerluefter_MUX 0;
BA_ "GenSigSendType" SG_ 1088 MO_Kuehlerluefter_MUX 0;
BA_ "Fehlerwert" SG_ 1088 MO_Kuehlerluefter_1 127;
BA_ "GenSigSwitchedByIgnition" SG_ 1088 MO_Kuehlerluefter_1 0;
BA_ "GenSigStartValue" SG_ 1088 MO_Kuehlerluefter_1 126;
BA_ "Fehlerwert" SG_ 1088 MO_Kuehlerluefter_2 127;
BA_ "GenSigSwitchedByIgnition" SG_ 1088 MO_Kuehlerluefter_2 0;
BA_ "GenSigStartValue" SG_ 1088 MO_Kuehlerluefter_2 126;
BA_ "GenSigSwitchedByIgnition" SG_ 1088 MO_HYB_Status_HV_Ladung 0;
BA_ "GenSigSendType" SG_ 1088 MO_HYB_Status_HV_Ladung 0;
BA_ "GenSigSwitchedByIgnition" SG_ 1088 MO_ITM_Warnung_Pumpe 0;
BA_ "GenSigSendType" SG_ 1088 MO_ITM_Warnung_Pumpe 0;
BA_ "GenSigSwitchedByIgnition" SG_ 1088 WIV_Anzeige_aktiv 0;
BA_ "GenSigSendType" SG_ 1088 WIV_Anzeige_aktiv 0;
BA_ "GenSigSwitchedByIgnition" SG_ 1088 WIV_Oelmin_Warn 0;
BA_ "GenSigSendType" SG_ 1088 WIV_Oelmin_Warn 0;
BA_ "GenSigSwitchedByIgnition" SG_ 1088 WIV_Sensorfehler 0;
BA_ "GenSigSendType" SG_ 1088 WIV_Sensorfehler 0;
BA_ "GenSigSwitchedByIgnition" SG_ 1088 WIV_Schieflage 0;
BA_ "GenSigSendType" SG_ 1088 WIV_Schieflage 0;
BA_ "GenSigSwitchedByIgnition" SG_ 1088 WIV_Oelstand 0;
BA_ "GenSigSendType" SG_ 1088 WIV_Oelstand 0;
BA_ "GenSigSwitchedByIgnition" SG_ 1088 MO_Zustand_HWP 0;
BA_ "GenSigStartValue" SG_ 1088 MO_Zustand_HWP 1;
BA_ "GenSigSendType" SG_ 1088 MO_Zustand_HWP 0;
BA_ "GenSigSwitchedByIgnition" SG_ 1088 MO_Kat_Warnung 0;
BA_ "GenSigSendType" SG_ 1088 MO_Kat_Warnung 0;
BA_ "GenSigSwitchedByIgnition" SG_ 1088 WIV_Oelsystem_aktiv 0;
BA_ "GenSigSendType" SG_ 1088 WIV_Oelsystem_aktiv 0;
BA_ "GenSigSwitchedByIgnition" SG_ 1088 WIV_nicht_betriebswarm 0;
BA_ "GenSigSendType" SG_ 1088 WIV_nicht_betriebswarm 0;
BA_ "GenSigSwitchedByIgnition" SG_ 1088 WIV_Ueberfuell_Warn 0;
BA_ "GenSigSendType" SG_ 1088 WIV_Ueberfuell_Warn 0;
BA_ "GenSigSwitchedByIgnition" SG_ 1088 WIV_laufender_Motor 0;
BA_ "GenSigSendType" SG_ 1088 WIV_laufender_Motor 0;
BA_ "GenSigSwitchedByIgnition" SG_ 1088 MO_HYB_Text_1 0;
BA_ "GenSigSendType" SG_ 1088 MO_HYB_Text_1 0;
BA_ "GenSigSwitchedByIgnition" SG_ 1088 MO_HYB_Text_2 0;
BA_ "GenSigSendType" SG_ 1088 MO_HYB_Text_2 0;
BA_ "GenSigSwitchedByIgnition" SG_ 1088 MO_HYB_Text_3 0;
BA_ "GenSigSendType" SG_ 1088 MO_HYB_Text_3 0;
BA_ "GenSigSwitchedByIgnition" SG_ 1088 MO_HYB_Text_4 0;
BA_ "GenSigSendType" SG_ 1088 MO_HYB_Text_4 0;
BA_ "GenSigSwitchedByIgnition" SG_ 1088 MO_Text_Motorstart 0;
BA_ "GenSigSendType" SG_ 1088 MO_Text_Motorstart 0;
BA_ "GenSigSwitchedByIgnition" SG_ 1088 MO_HYB_Text_5 0;
BA_ "GenSigSendType" SG_ 1088 MO_HYB_Text_5 0;
BA_ "GenSigSwitchedByIgnition" SG_ 1088 MO_HYB_Text_6 0;
BA_ "GenSigSendType" SG_ 1088 MO_HYB_Text_6 0;
BA_ "GenSigSwitchedByIgnition" SG_ 1088 MO_HYB_Text_7 0;
BA_ "GenSigSendType" SG_ 1088 MO_HYB_Text_7 0;
BA_ "GenSigSwitchedByIgnition" SG_ 1088 WIV_Oeldyn_avl 0;
BA_ "GenSigSendType" SG_ 1088 WIV_Oeldyn_avl 0;
BA_ "GenSigSwitchedByIgnition" SG_ 1088 MO_Text_MSG_Werkstatt 0;
BA_ "GenSigSendType" SG_ 1088 MO_Text_MSG_Werkstatt 0;
BA_ "GenSigSwitchedByIgnition" SG_ 1088 MO_Text_Partikelfil_Reg 0;
BA_ "GenSigSendType" SG_ 1088 MO_Text_Partikelfil_Reg 0;
BA_ "GenSigSwitchedByIgnition" SG_ 1088 MO_Text_Fehler_Kraftstoffsys 0;
BA_ "GenSigSendType" SG_ 1088 MO_Text_Fehler_Kraftstoffsys 0;
BA_ "GenSigSwitchedByIgnition" SG_ 1088 WIV_Oelmenge 0;
BA_ "GenSigSendType" SG_ 1088 WIV_Oelmenge 0;
BA_ "GenSigSwitchedByIgnition" SG_ 1088 MO_Systemlampe 0;
BA_ "GenSigSendType" SG_ 1088 MO_Systemlampe 0;
BA_ "GenSigSwitchedByIgnition" SG_ 1088 MO_OBD2_Lampe 0;
BA_ "GenSigSendType" SG_ 1088 MO_OBD2_Lampe 0;
BA_ "GenSigSwitchedByIgnition" SG_ 1088 MO_Heissleuchte 0;
BA_ "GenSigSendType" SG_ 1088 MO_Heissleuchte 0;
BA_ "GenSigSwitchedByIgnition" SG_ 1088 MO_Partikel_Lampe 0;
BA_ "GenSigSendType" SG_ 1088 MO_Partikel_Lampe 0;
BA_ "GenSigSwitchedByIgnition" SG_ 1088 MO_Winterfahrprog 0;
BA_ "GenSigSendType" SG_ 1088 MO_Winterfahrprog 0;
BA_ "GenSigSwitchedByIgnition" SG_ 1088 WIV_Oelstand_nicht_vorhanden 0;
BA_ "GenSigSendType" SG_ 1088 WIV_Oelstand_nicht_vorhanden 0;
BA_ "GenSigSwitchedByIgnition" SG_ 1088 WIV_nachfuellanzeige_ein 0;
BA_ "GenSigSendType" SG_ 1088 WIV_nachfuellanzeige_ein 0;
BA_ "GenSigSwitchedByIgnition" SG_ 1088 WIV_Ueberfuell_deaktiv 0;
BA_ "GenSigSendType" SG_ 1088 WIV_Ueberfuell_deaktiv 0;
BA_ "GenSigSwitchedByIgnition" SG_ 1088 WIV_Unterfuell_Warn 0;
BA_ "GenSigSendType" SG_ 1088 WIV_Unterfuell_Warn 0;
BA_ "GenSigSwitchedByIgnition" SG_ 1088 MO_Tankdeckel_Lampe 0;
BA_ "GenSigSendType" SG_ 1088 MO_Tankdeckel_Lampe 0;
BA_ "GenSigSwitchedByIgnition" SG_ 1088 MO_Text_Tankdeckelwarn 0;
BA_ "GenSigSendType" SG_ 1088 MO_Text_Tankdeckelwarn 0;
BA_ "GenSigSwitchedByIgnition" SG_ 1088 WIV_Enable_Oeldr_Motor 0;
BA_ "GenSigSendType" SG_ 1088 WIV_Enable_Oeldr_Motor 0;
BA_ "GenSigSwitchedByIgnition" SG_ 1088 WIV_Oeldr_Warn_Motor 0;
BA_ "GenSigSendType" SG_ 1088 WIV_Oeldr_Warn_Motor 0;
BA_ "GenSigSwitchedByIgnition" SG_ 1088 MO_Avus_Motorschutz 0;
BA_ "GenSigSendType" SG_ 1088 MO_Avus_Motorschutz 0;
BA_ "GenSigSwitchedByIgnition" SG_ 1088 MO_HYB_Fahrbereitschaft 0;
BA_ "GenSigSendType" SG_ 1088 MO_HYB_Fahrbereitschaft 0;
BA_ "GenSigSwitchedByIgnition" SG_ 1600 MO_QBit_Ansaugluft_Temp 0;
BA_ "GenSigStartValue" SG_ 1600 MO_QBit_Ansaugluft_Temp 1;
BA_ "GenSigSendType" SG_ 1600 MO_QBit_Ansaugluft_Temp 0;
BA_ "GenSigSwitchedByIgnition" SG_ 1600 MO_QBit_Oel_Temp 0;
BA_ "GenSigStartValue" SG_ 1600 MO_QBit_Oel_Temp 1;
BA_ "GenSigSendType" SG_ 1600 MO_QBit_Oel_Temp 0;
BA_ "GenSigSwitchedByIgnition" SG_ 1600 MO_QBit_Kuehlmittel_Temp 0;
BA_ "GenSigStartValue" SG_ 1600 MO_QBit_Kuehlmittel_Temp 1;
BA_ "GenSigSendType" SG_ 1600 MO_QBit_Kuehlmittel_Temp 0;
BA_ "GenSigSwitchedByIgnition" SG_ 1600 MO_HYB_Fehler_HV_Netz 0;
BA_ "GenSigSendType" SG_ 1600 MO_HYB_Fehler_HV_Netz 0;
BA_ "GenSigSwitchedByIgnition" SG_ 1600 MO_aktives_Getriebeheizen 0;
BA_ "GenSigSendType" SG_ 1600 MO_aktives_Getriebeheizen 0;
BA_ "GenSigSwitchedByIgnition" SG_ 1600 MO_Absperrventil_oeffnen 0;
BA_ "GenSigSendType" SG_ 1600 MO_Absperrventil_oeffnen 0;
BA_ "Fehlerwert" SG_ 1600 MO_Ansaugluft_Temp 255;
BA_ "GenSigSwitchedByIgnition" SG_ 1600 MO_Ansaugluft_Temp 0;
BA_ "GenSigStartValue" SG_ 1600 MO_Ansaugluft_Temp 254;
BA_ "GenSigSendType" SG_ 1600 MO_Ansaugluft_Temp 0;
BA_ "Fehlerwert" SG_ 1600 MO_Oel_Temp 255;
BA_ "GenSigSwitchedByIgnition" SG_ 1600 MO_Oel_Temp 0;
BA_ "GenSigStartValue" SG_ 1600 MO_Oel_Temp 254;
BA_ "GenSigSendType" SG_ 1600 MO_Oel_Temp 0;
BA_ "Fehlerwert" SG_ 1600 MO_Kuehlmittel_Temp 255;
BA_ "GenSigSwitchedByIgnition" SG_ 1600 MO_Kuehlmittel_Temp 0;
BA_ "GenSigStartValue" SG_ 1600 MO_Kuehlmittel_Temp 254;
BA_ "GenSigSendType" SG_ 1600 MO_Kuehlmittel_Temp 0;
BA_ "Fehlerwert" SG_ 1600 MO_Hoeheninfo 255;
BA_ "GenSigSwitchedByIgnition" SG_ 1600 MO_Hoeheninfo 0;
BA_ "GenSigSendType" SG_ 1600 MO_Hoeheninfo 0;
BA_ "GenSigSwitchedByIgnition" SG_ 1600 MO_Kennfeldk 0;
BA_ "GenSigSendType" SG_ 1600 MO_Kennfeldk 0;
BA_ "GenSigSwitchedByIgnition" SG_ 1600 MO_Versionsinfo 0;
BA_ "GenSigFuncType" SG_ 1600 MO_Versionsinfo 8;
BA_ "GenSigSendType" SG_ 1600 MO_Versionsinfo 0;
BA_ "GenSigSwitchedByIgnition" SG_ 1600 MO_Getriebe_kuehlen 0;
BA_ "GenSigSendType" SG_ 1600 MO_Getriebe_kuehlen 0;
BA_ "GenSigSwitchedByIgnition" SG_ 1600 MO_Mom_Traegheit_02 0;
BA_ "GenSigSendType" SG_ 1600 MO_Mom_Traegheit_02 0;
BA_ "Fehlerwert" SG_ 1600 MO_Heizungspumpenansteuerung 13;
BA_ "GenSigSwitchedByIgnition" SG_ 1600 MO_Heizungspumpenansteuerung 0;
BA_ "GenSigStartValue" SG_ 1600 MO_Heizungspumpenansteuerung 14;
BA_ "GenSigSendType" SG_ 1600 MO_Heizungspumpenansteuerung 0;
BA_ "GenSigSwitchedByIgnition" SG_ 1600 MO_SpannungsAnf 0;
BA_ "GenSigSendType" SG_ 1600 MO_SpannungsAnf 0;
BA_ "GenSigSwitchedByIgnition" SG_ 1600 MO_Nachlaufzeit_Heizungspumpe 0;
BA_ "GenSigSendType" SG_ 1600 MO_Nachlaufzeit_Heizungspumpe 0;
BA_ "Fehlerwert" SG_ 933 Enrgfluss_State 255;
BA_ "GenSigSwitchedByIgnition" SG_ 933 Enrgfluss_State 0;
BA_ "GenSigSendType" SG_ 933 Enrgfluss_State 0;
BA_ "Fehlerwert" SG_ 933 Ladezustand 255;
BA_ "GenSigSwitchedByIgnition" SG_ 933 Ladezustand 0;
BA_ "GenSigSendType" SG_ 933 Ladezustand 0;
BA_ "Fehlerwert" SG_ 933 Energiefluss 255;
BA_ "GenSigSwitchedByIgnition" SG_ 933 Energiefluss 0;
BA_ "GenSigStartValue" SG_ 933 Energiefluss 128;
BA_ "GenSigSendType" SG_ 933 Energiefluss 0;
BA_ "Fehlerwert" SG_ 933 Enrgrueckfluss 255;
BA_ "GenSigSwitchedByIgnition" SG_ 933 Enrgrueckfluss 0;
BA_ "GenSigSendType" SG_ 933 Enrgrueckfluss 0;
BA_ "GenSigSwitchedByIgnition" SG_ 933 MO_Powermeter 0;
BA_ "GenSigStartValue" SG_ 933 MO_Powermeter 4093;
BA_ "GenSigSendType" SG_ 933 MO_Powermeter 0;
BA_ "GenSigSwitchedByIgnition" SG_ 933 MO_Overboost 0;
BA_ "GenSigSendType" SG_ 933 MO_Overboost 0;
BA_ "GenSigSwitchedByIgnition" SG_ 933 MO_Anf_Abgasklappe 0;
BA_ "GenSigSendType" SG_ 933 MO_Anf_Abgasklappe 3;
BA_ "GenSigSwitchedByIgnition" SG_ 933 MO_LED_Abgasklappe 0;
BA_ "GenSigSendType" SG_ 933 MO_LED_Abgasklappe 3;
BA_ "GenSigSwitchedByIgnition" SG_ 933 MO_Fehler_MSpG 0;
BA_ "GenSigSendType" SG_ 933 MO_Fehler_MSpG 0;
BA_ "Fehlerwert" SG_ 933 MO_Temp_MotRaum 63;
BA_ "GenSigSwitchedByIgnition" SG_ 933 MO_Temp_MotRaum 0;
BA_ "GenSigStartValue" SG_ 933 MO_Temp_MotRaum 62;
BA_ "GenSigSendType" SG_ 933 MO_Temp_MotRaum 0;
BA_ "GenSigSwitchedByIgnition" SG_ 933 MO_Hoch_Anz_Nmax 0;
BA_ "GenSigSendType" SG_ 933 MO_Hoch_Anz_Nmax 3;
BA_ "GenSigSwitchedByIgnition" SG_ 933 MO_Hoch_Anz_Eco 0;
BA_ "GenSigSendType" SG_ 933 MO_Hoch_Anz_Eco 3;
BA_ "Fehlerwert" SG_ 933 MO_Oel_Temp_Radsatz 255;
BA_ "GenSigSwitchedByIgnition" SG_ 933 MO_Oel_Temp_Radsatz 0;
BA_ "GenSigStartValue" SG_ 933 MO_Oel_Temp_Radsatz 254;
BA_ "GenSigSendType" SG_ 933 MO_Oel_Temp_Radsatz 0;
BA_ "GenSigSwitchedByIgnition" SG_ 1601 Motor_Code_01_CHK 0;
BA_ "GenSigFuncType" SG_ 1601 Motor_Code_01_CHK 3;
BA_ "GenSigSendType" SG_ 1601 Motor_Code_01_CHK 0;
BA_ "GenSigSwitchedByIgnition" SG_ 1601 Motor_Code_01_BZ 0;
BA_ "GenSigFuncType" SG_ 1601 Motor_Code_01_BZ 1;
BA_ "GenSigSendType" SG_ 1601 Motor_Code_01_BZ 0;
BA_ "GenSigSwitchedByIgnition" SG_ 1601 MO_Faktor_Momente 0;
BA_ "GenSigFuncType" SG_ 1601 MO_Faktor_Momente 8;
BA_ "GenSigSendType" SG_ 1601 MO_Faktor_Momente 0;
BA_ "GenSigSwitchedByIgnition" SG_ 1601 MO_Hybridfahrzeug 0;
BA_ "GenSigFuncType" SG_ 1601 MO_Hybridfahrzeug 8;
BA_ "GenSigSendType" SG_ 1601 MO_Hybridfahrzeug 0;
BA_ "GenSigSwitchedByIgnition" SG_ 1601 MO_Code 0;
BA_ "GenSigFuncType" SG_ 1601 MO_Code 8;
BA_ "GenSigSendType" SG_ 1601 MO_Code 0;
BA_ "GenSigSwitchedByIgnition" SG_ 1601 MO_Getriebe_Code 0;
BA_ "GenSigFuncType" SG_ 1601 MO_Getriebe_Code 8;
BA_ "GenSigSendType" SG_ 1601 MO_Getriebe_Code 0;
BA_ "GenSigSwitchedByIgnition" SG_ 1601 MO_StartStopp_Codiert 0;
BA_ "GenSigFuncType" SG_ 1601 MO_StartStopp_Codiert 8;
BA_ "GenSigSendType" SG_ 1601 MO_StartStopp_Codiert 0;
BA_ "GenSigSwitchedByIgnition" SG_ 1601 MO_Anzahl_Zyl 0;
BA_ "GenSigFuncType" SG_ 1601 MO_Anzahl_Zyl 8;
BA_ "GenSigSendType" SG_ 1601 MO_Anzahl_Zyl 0;
BA_ "GenSigSwitchedByIgnition" SG_ 1601 MO_Kraftstoffart 0;
BA_ "GenSigFuncType" SG_ 1601 MO_Kraftstoffart 8;
BA_ "GenSigSendType" SG_ 1601 MO_Kraftstoffart 0;
BA_ "GenSigSwitchedByIgnition" SG_ 1601 MO_Hubraum 0;
BA_ "GenSigFuncType" SG_ 1601 MO_Hubraum 8;
BA_ "GenSigSendType" SG_ 1601 MO_Hubraum 0;
BA_ "GenSigSwitchedByIgnition" SG_ 1601 MO_Ansaugsystem 0;
BA_ "GenSigFuncType" SG_ 1601 MO_Ansaugsystem 8;
BA_ "GenSigSendType" SG_ 1601 MO_Ansaugsystem 0;
BA_ "GenSigSwitchedByIgnition" SG_ 1601 MO_Leistung 0;
BA_ "GenSigFuncType" SG_ 1601 MO_Leistung 8;
BA_ "GenSigSendType" SG_ 1601 MO_Leistung 0;
BA_ "GenSigSwitchedByIgnition" SG_ 1601 MO_Abgastyp 0;
BA_ "GenSigFuncType" SG_ 1601 MO_Abgastyp 8;
BA_ "GenSigSendType" SG_ 1601 MO_Abgastyp 0;
BA_ "GenSigSwitchedByIgnition" SG_ 1601 MO_Einspritzart 0;
BA_ "GenSigFuncType" SG_ 1601 MO_Einspritzart 8;
BA_ "GenSigSendType" SG_ 1601 MO_Einspritzart 0;
BA_REL_ "GenSigTimeoutTime" BU_SG_REL_ GW_App_PAG_PF SG_ 1706 KBI_STH_Std 5000;
BA_REL_ "GenSigTimeoutTime" BU_SG_REL_ GW_App_PAG_PF SG_ 1706 KBI_STH_Std 5000;
BA_REL_ "GenSigTimeoutTime" BU_SG_REL_ GW_App_PAG_PF SG_ 1706 KBI_STH_Min 5000;
BA_REL_ "GenSigTimeoutTime" BU_SG_REL_ GW_App_PAG_PF SG_ 1706 KBI_STH_Min 5000;
BA_REL_ "GenSigTimeoutTime" BU_SG_REL_ GW_App_PAG_PF SG_ 1706 KBI_STH_TT 5000;
BA_REL_ "GenSigTimeoutTime" BU_SG_REL_ GW_App_PAG_PF SG_ 1706 KBI_STH_TT 5000;
BA_REL_ "GenSigTimeoutTime" BU_SG_REL_ GW_App_PAG_PF SG_ 1706 KBI_STH_MM 5000;
BA_REL_ "GenSigTimeoutTime" BU_SG_REL_ GW_App_PAG_PF SG_ 1706 KBI_STH_MM 5000;
BA_REL_ "GenSigTimeoutTime" BU_SG_REL_ GW_App_PAG_PF SG_ 1706 KBI_STH_JJ 5000;
BA_REL_ "GenSigTimeoutTime" BU_SG_REL_ GW_App_PAG_PF SG_ 1706 KBI_STH_JJ 5000;
BA_REL_ "GenSigTimeoutTime" BU_SG_REL_ GW_App_PAG_PF SG_ 1706 KBI_STH_Timer_Status 5000;
BA_REL_ "GenSigTimeoutTime" BU_SG_REL_ GW_App_PAG_PF SG_ 1706 KBI_STH_Timer_Status 5000;
BA_REL_ "GenSigTimeoutTime" BU_SG_REL_ Klima_PAG_PF SG_ 1706 KBI_Menu1_Pos1 5000;
BA_REL_ "GenSigTimeoutTime" BU_SG_REL_ Klima_PAG_PF SG_ 1706 KBI_Menu1_Pos2 5000;
BA_REL_ "GenSigTimeoutTime" BU_SG_REL_ Klima_PAG_PF SG_ 1706 KBI_Menu1_Pos3 5000;
BA_REL_ "GenSigTimeoutTime" BU_SG_REL_ Klima_PAG_PF SG_ 1706 KBI_Menu1_Pos4 5000;
BA_REL_ "GenSigTimeoutTime" BU_SG_REL_ Klima_PAG_PF SG_ 1706 KBI_Menu1_Pos5 5000;
BA_REL_ "GenSigTimeoutTime" BU_SG_REL_ Klima_PAG_PF SG_ 1706 KBI_Menu1_Pos6 5000;
BA_REL_ "GenSigTimeoutTime" BU_SG_REL_ Klima_PAG_PF SG_ 1706 KBI_Menu1_Pos7 5000;
BA_REL_ "GenSigTimeoutTime" BU_SG_REL_ Klima_PAG_PF SG_ 1706 KBI_Menu1_Pos8 5000;
BA_REL_ "GenSigTimeoutTime" BU_SG_REL_ Klima_PAG_PF SG_ 1706 KBI_Menu2_Pos1 5000;
BA_REL_ "GenSigTimeoutTime" BU_SG_REL_ Klima_PAG_PF SG_ 1706 KBI_Menu2_Pos2 5000;
BA_REL_ "GenSigTimeoutTime" BU_SG_REL_ Klima_PAG_PF SG_ 1706 KBI_Menu2_Pos3 5000;
BA_REL_ "GenSigTimeoutTime" BU_SG_REL_ Klima_PAG_PF SG_ 1706 KBI_Menu2_Pos4 5000;
BA_REL_ "GenSigTimeoutTime" BU_SG_REL_ Klima_PAG_PF SG_ 1706 KBI_Menu2_Pos5 5000;
BA_REL_ "GenSigTimeoutTime" BU_SG_REL_ Klima_PAG_PF SG_ 1706 KBI_Menu2_Pos6 5000;
BA_REL_ "GenSigTimeoutTime" BU_SG_REL_ Klima_PAG_PF SG_ 1706 KBI_Menu2_Pos7 5000;
BA_REL_ "GenSigTimeoutTime" BU_SG_REL_ Klima_PAG_PF SG_ 1706 KBI_Menu2_Pos8 5000;
BA_REL_ "GenSigTimeoutTime" BU_SG_REL_ Klima_PAG_PF SG_ 1706 KBI_Menu3_Pos1 5000;
BA_REL_ "GenSigTimeoutTime" BU_SG_REL_ Klima_PAG_PF SG_ 1706 KBI_Menu3_Pos2 5000;
BA_REL_ "GenSigTimeoutTime" BU_SG_REL_ Klima_PAG_PF SG_ 1706 KBI_Menu3_Pos3 5000;
BA_REL_ "GenSigTimeoutTime" BU_SG_REL_ Klima_PAG_PF SG_ 1706 KBI_Menu3_Pos4 5000;
BA_REL_ "GenSigTimeoutTime" BU_SG_REL_ Klima_PAG_PF SG_ 1706 KBI_Menu3_Pos5 5000;
BA_REL_ "GenSigTimeoutTime" BU_SG_REL_ Klima_PAG_PF SG_ 1706 KBI_Menu3_Pos6 5000;
BA_REL_ "GenSigTimeoutTime" BU_SG_REL_ Klima_PAG_PF SG_ 1706 KBI_Menu3_Pos7 5000;
BA_REL_ "GenSigTimeoutTime" BU_SG_REL_ Klima_PAG_PF SG_ 1706 KBI_Menu3_Pos8 5000;
BA_REL_ "GenSigTimeoutTime" BU_SG_REL_ ADR_PAG_X2 SG_ 282 KBI_Reichw_anz 500;
BA_REL_ "GenSigTimeoutTime" BU_SG_REL_ OCU_PAG_PF SG_ 282 KBI_Reichw_anz 500;
BA_REL_ "GenSigTimeoutTime" BU_SG_REL_ ADR_PAG_X2 SG_ 282 KBI_E_Restreichweite 500;
BA_REL_ "GenSigTimeoutTime" BU_SG_REL_ OCU_PAG_PF SG_ 282 KBI_E_Restreichweite 500;
BA_REL_ "GenSigTimeoutTime" BU_SG_REL_ ADR_PAG_X2 SG_ 1331 KBI_Trip_Reset_Min 2500;
BA_REL_ "GenSigTimeoutTime" BU_SG_REL_ OCU_PAG_PF SG_ 1331 KBI_Trip_Reset_Min 2500;
BA_REL_ "GenSigTimeoutTime" BU_SG_REL_ ADR_PAG_X2 SG_ 1331 KBI_Trip_Reset_Std 2500;
BA_REL_ "GenSigTimeoutTime" BU_SG_REL_ OCU_PAG_PF SG_ 1331 KBI_Trip_Reset_Std 2500;
BA_REL_ "GenSigTimeoutTime" BU_SG_REL_ ADR_PAG_X2 SG_ 922 KBI_Trip_DS_Verbr_1 1000;
BA_REL_ "GenSigTimeoutTime" BU_SG_REL_ OCU_PAG_PF SG_ 922 KBI_Trip_DS_Verbr_1 1000;
BA_REL_ "GenSigTimeoutTime" BU_SG_REL_ ADR_PAG_X2 SG_ 922 KBI_Trip_Min_1 1000;
BA_REL_ "GenSigTimeoutTime" BU_SG_REL_ OCU_PAG_PF SG_ 922 KBI_Trip_Min_1 1000;
BA_REL_ "GenSigTimeoutTime" BU_SG_REL_ ADR_PAG_X2 SG_ 922 KBI_Trip_Std_1 1000;
BA_REL_ "GenSigTimeoutTime" BU_SG_REL_ OCU_PAG_PF SG_ 922 KBI_Trip_Std_1 1000;
BA_REL_ "GenSigTimeoutTime" BU_SG_REL_ ADR_PAG_X2 SG_ 922 KBI_Trip_Strecke_1 1000;
BA_REL_ "GenSigTimeoutTime" BU_SG_REL_ OCU_PAG_PF SG_ 922 KBI_Trip_Strecke_1 1000;
BA_REL_ "GenSigTimeoutTime" BU_SG_REL_ ADR_PAG_X2 SG_ 922 KBI_Trip_DS_V_1 1000;
BA_REL_ "GenSigTimeoutTime" BU_SG_REL_ OCU_PAG_PF SG_ 922 KBI_Trip_DS_V_1 1000;
BA_REL_ "GenSigTimeoutTime" BU_SG_REL_ ADR_PAG_X2 SG_ 923 KBI_Trip_DS_Verbr_2 1000;
BA_REL_ "GenSigTimeoutTime" BU_SG_REL_ OCU_PAG_PF SG_ 923 KBI_Trip_DS_Verbr_2 1000;
BA_REL_ "GenSigTimeoutTime" BU_SG_REL_ ADR_PAG_X2 SG_ 923 KBI_Trip_Min_2 1000;
BA_REL_ "GenSigTimeoutTime" BU_SG_REL_ OCU_PAG_PF SG_ 923 KBI_Trip_Min_2 1000;
BA_REL_ "GenSigTimeoutTime" BU_SG_REL_ ADR_PAG_X2 SG_ 923 KBI_Trip_Std_2 1000;
BA_REL_ "GenSigTimeoutTime" BU_SG_REL_ OCU_PAG_PF SG_ 923 KBI_Trip_Std_2 1000;
BA_REL_ "GenSigTimeoutTime" BU_SG_REL_ ADR_PAG_X2 SG_ 923 KBI_Trip_Strecke_2 1000;
BA_REL_ "GenSigTimeoutTime" BU_SG_REL_ OCU_PAG_PF SG_ 923 KBI_Trip_Strecke_2 1000;
BA_REL_ "GenSigTimeoutTime" BU_SG_REL_ ADR_PAG_X2 SG_ 923 KBI_Trip_DS_V_2 1000;
BA_REL_ "GenSigTimeoutTime" BU_SG_REL_ OCU_PAG_PF SG_ 923 KBI_Trip_DS_V_2 1000;
BA_REL_ "GenSigTimeoutTime" BU_SG_REL_ ADR_PAG_X2 SG_ 1535 KBI_Trip_E_Min 5000;
BA_REL_ "GenSigTimeoutTime" BU_SG_REL_ ADR_PAG_X2 SG_ 1535 KBI_Trip_E_Std 5000;
BA_REL_ "GenSigTimeoutTime" BU_SG_REL_ ADR_PAG_X2 SG_ 1343 KBI_Trip_E_Verbr_fortl 1000;
BA_REL_ "GenSigTimeoutTime" BU_SG_REL_ OCU_PAG_PF SG_ 1343 KBI_Trip_E_Verbr_fortl 1000;
BA_REL_ "GenSigTimeoutTime" BU_SG_REL_ ADR_PAG_X2 SG_ 1343 KBI_Trip_E_Verbr_seit 1000;
BA_REL_ "GenSigTimeoutTime" BU_SG_REL_ OCU_PAG_PF SG_ 1343 KBI_Trip_E_Verbr_seit 1000;
BA_REL_ "GenSigTimeoutTime" BU_SG_REL_ ADR_PAG_X2 SG_ 1343 KBI_Trip_E_Strecke_fortl 1000;
BA_REL_ "GenSigTimeoutTime" BU_SG_REL_ OCU_PAG_PF SG_ 1343 KBI_Trip_E_Strecke_fortl 1000;
BA_REL_ "GenSigTimeoutTime" BU_SG_REL_ ADR_PAG_X2 SG_ 1343 KBI_Trip_E_Strecke_seit 1000;
BA_REL_ "GenSigTimeoutTime" BU_SG_REL_ OCU_PAG_PF SG_ 1343 KBI_Trip_E_Strecke_seit 1000;
BA_REL_ "GenSigTimeoutTime" BU_SG_REL_ ADR_PAG_X2 SG_ 1662 LAD_Warnzustand 5000;
BA_REL_ "GenSigTimeoutTime" BU_SG_REL_ Kombi_PAG_PF SG_ 1662 LAD_Warnzustand 5000;
BA_REL_ "GenSigTimeoutTime" BU_SG_REL_ ADR_PAG_X2 SG_ 1662 LAD_Fehlerzustand 5000;
BA_REL_ "GenSigTimeoutTime" BU_SG_REL_ Kombi_PAG_PF SG_ 1662 LAD_Fehlerzustand 5000;
BA_REL_ "GenSigTimeoutTime" BU_SG_REL_ Kombi_PAG_PF SG_ 810 EPS_Warnungen 500;
BA_REL_ "GenSigTimeoutTime" BU_SG_REL_ Kombi_PAG_PF SG_ 1137 LH_Bremsl_li_def 1000;
BA_REL_ "GenSigTimeoutTime" BU_SG_REL_ Kombi_PAG_PF SG_ 1137 LH_Schlusslicht_li_def 1000;
BA_REL_ "GenSigTimeoutTime" BU_SG_REL_ Kombi_PAG_PF SG_ 1137 LH_Rueckf_li_def 1000;
BA_REL_ "GenSigTimeoutTime" BU_SG_REL_ Kombi_PAG_PF SG_ 1137 LH_Nebel_li_def 1000;
BA_REL_ "GenSigTimeoutTime" BU_SG_REL_ Kombi_PAG_PF SG_ 1137 LH_Schluss_Brems_Nebel_li_def 1000;
BA_REL_ "GenSigTimeoutTime" BU_SG_REL_ Kombi_PAG_PF SG_ 1137 LH_Schluss_Brems_Nebel_re_def 1000;
BA_REL_ "GenSigTimeoutTime" BU_SG_REL_ Kombi_PAG_PF SG_ 1137 LH_Bremsl_re_def 1000;
BA_REL_ "GenSigTimeoutTime" BU_SG_REL_ Kombi_PAG_PF SG_ 1137 LH_Schlusslicht_re_def 1000;
BA_REL_ "GenSigTimeoutTime" BU_SG_REL_ Kombi_PAG_PF SG_ 1137 LH_Rueckf_re_def 1000;
BA_REL_ "GenSigTimeoutTime" BU_SG_REL_ Kombi_PAG_PF SG_ 1137 LH_Nebel_re_def 1000;
BA_REL_ "GenSigTimeoutTime" BU_SG_REL_ Kombi_PAG_PF SG_ 1137 LH_Kennzl_def 1000;
BA_REL_ "GenSigTimeoutTime" BU_SG_REL_ Kombi_PAG_PF SG_ 1137 LH_3_Bremsl_def 1000;
BA_REL_ "GenSigTimeoutTime" BU_SG_REL_ ADR_PAG_X2 SG_ 1321 Lift_Status 2000;
BA_REL_ "GenSigTimeoutTime" BU_SG_REL_ Kombi_PAG_PF SG_ 1321 Lift_Status 2000;
BA_REL_ "GenSigTimeoutTime" BU_SG_REL_ Kombi_PAG_PF SG_ 917 LWR_KD_Fehler 1000;
BA_REL_ "GenSigTimeoutTime" BU_SG_REL_ Kombi_PAG_PF SG_ 1704 KBI_Schaltpkt_Anz_ein 5000;
BA_REL_ "GenSigTimeoutTime" BU_SG_REL_ Klima_PAG_PF SG_ 1704 KBI_Erw_BelueftFeld 5000;
BA_REL_ "GenSigTimeoutTime" BU_SG_REL_ Klima_PAG_PF SG_ 1704 KBI_Auto_Umluft 5000;
BA_REL_ "GenSigTimeoutTime" BU_SG_REL_ Klima_PAG_PF SG_ 1704 KBI_Automem_Inaktiv 5000;
BA_REL_ "GenSigTimeoutTime" BU_SG_REL_ Klima_PAG_PF SG_ 1704 KBI_Jokerkey_Hupe_Aktiv 5000;
BA_REL_ "GenSigTimeoutTime" BU_SG_REL_ Klima_PAG_PF SG_ 1704 KBI_PTC_Zuheizer 5000;
BA_REL_ "GenSigTimeoutTime" BU_SG_REL_ Klima_PAG_PF SG_ 1704 KBI_Klimastyles 5000;
BA_REL_ "GenSigTimeoutTime" BU_SG_REL_ Klima_PAG_PF SG_ 1704 KBI_Mittenduesentemp 5000;
BA_REL_ "GenSigTimeoutTime" BU_SG_REL_ Miko_PAG_X2 SG_ 1704 KBI_Innenlicht_per_Tuerkontakt 5000;
BA_REL_ "GenSigTimeoutTime" BU_SG_REL_ ADR_PAG_X2 SG_ 1471 MFL_Tastencode_1 5000;
BA_REL_ "GenSigTimeoutTime" BU_SG_REL_ Klima_PAG_PF SG_ 1471 MFL_Tastencode_1 5000;
BA_REL_ "GenSigTimeoutTime" BU_SG_REL_ Kombi_PAG_PF SG_ 1471 MFL_Tastencode_1 5000;
BA_REL_ "GenSigTimeoutTime" BU_SG_REL_ Miko_PAG_X2 SG_ 1471 MFL_Tastencode_1 5000;
BA_REL_ "GenSigTimeoutTime" BU_SG_REL_ ADR_PAG_X2 SG_ 1471 MFL_Tastencode_2 5000;
BA_REL_ "GenSigTimeoutTime" BU_SG_REL_ Klima_PAG_PF SG_ 1471 MFL_Tastencode_2 5000;
BA_REL_ "GenSigTimeoutTime" BU_SG_REL_ Kombi_PAG_PF SG_ 1471 MFL_Tastencode_2 5000;
BA_REL_ "GenSigTimeoutTime" BU_SG_REL_ ADR_PAG_X2 SG_ 1471 MFL_Eventcode_1 5000;
BA_REL_ "GenSigTimeoutTime" BU_SG_REL_ Klima_PAG_PF SG_ 1471 MFL_Eventcode_1 5000;
BA_REL_ "GenSigTimeoutTime" BU_SG_REL_ Kombi_PAG_PF SG_ 1471 MFL_Eventcode_1 5000;
BA_REL_ "GenSigTimeoutTime" BU_SG_REL_ ADR_PAG_X2 SG_ 1471 MFL_Eventcode_2 5000;
BA_REL_ "GenSigTimeoutTime" BU_SG_REL_ Klima_PAG_PF SG_ 1471 MFL_Eventcode_2 5000;
BA_REL_ "GenSigTimeoutTime" BU_SG_REL_ Kombi_PAG_PF SG_ 1471 MFL_Eventcode_2 5000;
BA_REL_ "GenSigTimeoutTime" BU_SG_REL_ ADR_PAG_X2 SG_ 1471 MFL_Marke 5000;
BA_REL_ "GenSigTimeoutTime" BU_SG_REL_ Klima_PAG_PF SG_ 1471 MFL_Marke 5000;
BA_REL_ "GenSigTimeoutTime" BU_SG_REL_ ADR_PAG_X2 SG_ 1471 MFL_Variante 5000;
BA_REL_ "GenSigTimeoutTime" BU_SG_REL_ Klima_PAG_PF SG_ 1471 MFL_Variante 5000;
BA_REL_ "GenSigTimeoutTime" BU_SG_REL_ ADR_PAG_X2 SG_ 193 Miko_T_Source 5000;
BA_REL_ "GenSigTimeoutTime" BU_SG_REL_ ADR_PAG_X2 SG_ 193 Miko_T_AC_Menue 5000;
BA_REL_ "GenSigTimeoutTime" BU_SG_REL_ ADR_PAG_X2 SG_ 193 Miko_T_Phone 5000;
BA_REL_ "GenSigTimeoutTime" BU_SG_REL_ ADR_PAG_X2 SG_ 193 Miko_T_Media 5000;
BA_REL_ "GenSigTimeoutTime" BU_SG_REL_ ADR_PAG_X2 SG_ 193 Miko_T_Tuner 5000;
BA_REL_ "GenSigTimeoutTime" BU_SG_REL_ ADR_PAG_X2 SG_ 193 Miko_T_Back 5000;
BA_REL_ "GenSigTimeoutTime" BU_SG_REL_ ADR_PAG_X2 SG_ 193 Miko_T_Option 5000;
BA_REL_ "GenSigTimeoutTime" BU_SG_REL_ ADR_PAG_X2 SG_ 193 Miko_T_Car 5000;
BA_REL_ "GenSigTimeoutTime" BU_SG_REL_ ADR_PAG_X2 SG_ 193 Miko_T_Info 5000;
BA_REL_ "GenSigTimeoutTime" BU_SG_REL_ ADR_PAG_X2 SG_ 193 Miko_T_Navi 5000;
BA_REL_ "GenSigTimeoutTime" BU_SG_REL_ ADR_PAG_X2 SG_ 193 Miko_Volume 5000;
BA_REL_ "GenSigTimeoutTime" BU_SG_REL_ ADR_PAG_X2 SG_ 193 Miko_Volume_Err 5000;
BA_REL_ "GenSigTimeoutTime" BU_SG_REL_ ADR_PAG_X2 SG_ 193 Miko_Volume_dir 5000;
BA_REL_ "GenSigTimeoutTime" BU_SG_REL_ ADR_PAG_X2 SG_ 193 Miko_Volume_press 5000;
BA_REL_ "GenSigTimeoutTime" BU_SG_REL_ ADR_PAG_X2 SG_ 193 Miko_MMI 5000;
BA_REL_ "GenSigTimeoutTime" BU_SG_REL_ ADR_PAG_X2 SG_ 193 Miko_MMI_fast 5000;
BA_REL_ "GenSigTimeoutTime" BU_SG_REL_ ADR_PAG_X2 SG_ 193 Miko_MMI_Err 5000;
BA_REL_ "GenSigTimeoutTime" BU_SG_REL_ ADR_PAG_X2 SG_ 193 Miko_MMI_dir 5000;
BA_REL_ "GenSigTimeoutTime" BU_SG_REL_ ADR_PAG_X2 SG_ 193 Miko_ADR_Reset 5000;
BA_REL_ "GenSigTimeoutTime" BU_SG_REL_ ADR_PAG_X2 SG_ 193 Miko_ADR_UltralongPress 5000;
BA_REL_ "GenSigTimeoutTime" BU_SG_REL_ Klima_PAG_PF SG_ 193 Miko_T_Blower 5000;
BA_REL_ "GenSigTimeoutTime" BU_SG_REL_ Klima_PAG_PF SG_ 193 Miko_T_Temp_left 5000;
BA_REL_ "GenSigTimeoutTime" BU_SG_REL_ Klima_PAG_PF SG_ 193 Miko_T_Temp_right 5000;
BA_REL_ "GenSigTimeoutTime" BU_SG_REL_ ADR_PAG_X2 SG_ 126 Enrgfluss_State_BN 500;
BA_REL_ "GenSigTimeoutTime" BU_SG_REL_ Kombi_PAG_PF SG_ 126 Enrgfluss_State_BN 500;
BA_REL_ "GenSigTimeoutTime" BU_SG_REL_ ADR_PAG_X2 SG_ 126 Enrgfluss_State_sek 500;
BA_REL_ "GenSigTimeoutTime" BU_SG_REL_ Kombi_PAG_PF SG_ 126 Enrgfluss_State_sek 500;
BA_REL_ "GenSigTimeoutTime" BU_SG_REL_ Kombi_PAG_PF SG_ 263 MO_Oeldruck 500;
BA_REL_ "GenSigTimeoutTime" BU_SG_REL_ Kombi_PAG_PF SG_ 263 MO_Anzeigedrehz 500;
BA_REL_ "GenSigTimeoutTime" BU_SG_REL_ Kombi_PAG_PF SG_ 263 MO_KVS 500;
BA_REL_ "GenSigTimeoutTime" BU_SG_REL_ Kombi_PAG_PF SG_ 263 MO_KVS_Ueberlauf 500;
BA_REL_ "GenSigTimeoutTime" BU_SG_REL_ Klimakomp_Dash_PAG_PF SG_ 782 MO_Klima_Eingr 500;
BA_REL_ "GenSigTimeoutTime" BU_SG_REL_ Kombi_PAG_PF SG_ 782 MO_MAX_Wunschdrehzahl 500;
BA_REL_ "GenSigTimeoutTime" BU_SG_REL_ Kombi_PAG_PF SG_ 1088 WIV_Oelmin_Warn 1000;
BA_REL_ "GenSigTimeoutTime" BU_SG_REL_ Kombi_PAG_PF SG_ 1088 WIV_Sensorfehler 1000;
BA_REL_ "GenSigTimeoutTime" BU_SG_REL_ Kombi_PAG_PF SG_ 1088 WIV_Oelstand 1000;
BA_REL_ "GenSigTimeoutTime" BU_SG_REL_ Kombi_PAG_PF SG_ 1088 WIV_Oelsystem_aktiv 1000;
BA_REL_ "GenSigTimeoutTime" BU_SG_REL_ Kombi_PAG_PF SG_ 1088 WIV_Ueberfuell_Warn 1000;
BA_REL_ "GenSigTimeoutTime" BU_SG_REL_ Kombi_PAG_PF SG_ 1088 MO_HYB_Text_1 1000;
BA_REL_ "GenSigTimeoutTime" BU_SG_REL_ Kombi_PAG_PF SG_ 1088 MO_HYB_Text_2 1000;
BA_REL_ "GenSigTimeoutTime" BU_SG_REL_ Kombi_PAG_PF SG_ 1088 MO_HYB_Text_3 1000;
BA_REL_ "GenSigTimeoutTime" BU_SG_REL_ ADR_PAG_X2 SG_ 1088 MO_HYB_Text_4 1000;
BA_REL_ "GenSigTimeoutTime" BU_SG_REL_ Kombi_PAG_PF SG_ 1088 MO_HYB_Text_4 1000;
BA_REL_ "GenSigTimeoutTime" BU_SG_REL_ Kombi_PAG_PF SG_ 1088 MO_HYB_Text_5 1000;
BA_REL_ "GenSigTimeoutTime" BU_SG_REL_ Kombi_PAG_PF SG_ 1088 MO_HYB_Text_6 1000;
BA_REL_ "GenSigTimeoutTime" BU_SG_REL_ Kombi_PAG_PF SG_ 1088 MO_HYB_Text_7 1000;
BA_REL_ "GenSigTimeoutTime" BU_SG_REL_ Kombi_PAG_PF SG_ 1088 MO_Text_MSG_Werkstatt 1000;
BA_REL_ "GenSigTimeoutTime" BU_SG_REL_ Kombi_PAG_PF SG_ 1088 MO_OBD2_Lampe 1000;
BA_REL_ "GenSigTimeoutTime" BU_SG_REL_ Kombi_PAG_PF SG_ 1088 MO_Heissleuchte 1000;
BA_REL_ "GenSigTimeoutTime" BU_SG_REL_ Kombi_PAG_PF SG_ 1088 WIV_Oelstand_nicht_vorhanden 1000;
BA_REL_ "GenSigTimeoutTime" BU_SG_REL_ Kombi_PAG_PF SG_ 1088 WIV_Unterfuell_Warn 1000;
BA_REL_ "GenSigTimeoutTime" BU_SG_REL_ Kombi_PAG_PF SG_ 1088 MO_Tankdeckel_Lampe 1000;
BA_REL_ "GenSigTimeoutTime" BU_SG_REL_ Kombi_PAG_PF SG_ 1088 MO_Text_Tankdeckelwarn 1000;
BA_REL_ "GenSigTimeoutTime" BU_SG_REL_ Kombi_PAG_PF SG_ 1088 WIV_Enable_Oeldr_Motor 1000;
BA_REL_ "GenSigTimeoutTime" BU_SG_REL_ Kombi_PAG_PF SG_ 1088 WIV_Oeldr_Warn_Motor 1000;
BA_REL_ "GenSigTimeoutTime" BU_SG_REL_ Kombi_PAG_PF SG_ 1088 MO_Avus_Motorschutz 1000;
BA_REL_ "GenSigTimeoutTime" BU_SG_REL_ Kombi_PAG_PF SG_ 1088 MO_HYB_Fahrbereitschaft 1000;
BA_REL_ "GenSigTimeoutTime" BU_SG_REL_ Kombi_PAG_PF SG_ 1600 MO_QBit_Oel_Temp 5000;
BA_REL_ "GenSigTimeoutTime" BU_SG_REL_ Kombi_PAG_PF SG_ 1600 MO_QBit_Kuehlmittel_Temp 5000;
BA_REL_ "GenSigTimeoutTime" BU_SG_REL_ Klima_PAG_PF SG_ 1600 MO_Absperrventil_oeffnen 5000;
BA_REL_ "GenSigTimeoutTime" BU_SG_REL_ Kombi_PAG_PF SG_ 1600 MO_Oel_Temp 5000;
BA_REL_ "GenSigTimeoutTime" BU_SG_REL_ Kombi_PAG_PF SG_ 1600 MO_Kuehlmittel_Temp 5000;
BA_REL_ "GenSigTimeoutTime" BU_SG_REL_ ADR_PAG_X2 SG_ 933 Enrgfluss_State 1000;
BA_REL_ "GenSigTimeoutTime" BU_SG_REL_ Kombi_PAG_PF SG_ 933 Enrgfluss_State 1000;
BA_REL_ "GenSigTimeoutTime" BU_SG_REL_ ADR_PAG_X2 SG_ 933 Ladezustand 1000;
BA_REL_ "GenSigTimeoutTime" BU_SG_REL_ Kombi_PAG_PF SG_ 933 Ladezustand 1000;
BA_REL_ "GenSigTimeoutTime" BU_SG_REL_ Kombi_PAG_PF SG_ 933 Energiefluss 1000;
BA_REL_ "GenSigTimeoutTime" BU_SG_REL_ Kombi_PAG_PF SG_ 933 Enrgrueckfluss 1000;
BA_REL_ "GenSigTimeoutTime" BU_SG_REL_ Klima_PAG_PF SG_ 933 MO_LED_Abgasklappe 1000;
BA_REL_ "GenSigTimeoutTime" BU_SG_REL_ Kombi_PAG_PF SG_ 933 MO_Hoch_Anz_Nmax 1000;
BA_REL_ "GenSigTimeoutTime" BU_SG_REL_ Kombi_PAG_PF SG_ 933 MO_Hoch_Anz_Eco 1000;
VAL_ 1706 KBI_STH_Status 0 "keine EIN/AUS-Anforderung" 1 "Standheizung EIN" 2 "Standheizung AUS" 3 "reserviert" ;
VAL_ 1706 KBI_STH_Timer_Status 0 "kein Timer aktiv" 1 "Timer aktiv" ;
VAL_ 1706 KBI_Menu1_Pos1 0 "Funktion nicht gewählt " 1 "Funktion gewählt" ;
VAL_ 1706 KBI_Menu1_Pos2 0 "Funktion nicht gewählt " 1 "Funktion gewählt" ;
VAL_ 1706 KBI_Menu1_Pos3 0 "Funktion nicht gewählt " 1 "Funktion gewählt" ;
VAL_ 1706 KBI_Menu1_Pos4 0 "Funktion nicht gewählt " 1 "Funktion gewählt" ;
VAL_ 1706 KBI_Menu1_Pos5 0 "Funktion nicht gewählt " 1 "Funktion gewählt" ;
VAL_ 1706 KBI_Menu1_Pos6 0 "Funktion nicht gewählt " 1 "Funktion gewählt" ;
VAL_ 1706 KBI_Menu1_Pos7 0 "Funktion nicht gewählt " 1 "Funktion gewählt" ;
VAL_ 1706 KBI_Menu1_Pos8 0 "Funktion nicht gewählt " 1 "Funktion gewählt" ;
VAL_ 1706 KBI_Menu2_Pos1 0 "Funktion nicht gewählt " 1 "Funktion gewählt" ;
VAL_ 1706 KBI_Menu2_Pos2 0 "Funktion nicht gewählt " 1 "Funktion gewählt" ;
VAL_ 1706 KBI_Menu2_Pos3 0 "Funktion nicht gewählt " 1 "Funktion gewählt" ;
VAL_ 1706 KBI_Menu2_Pos4 0 "Funktion nicht gewählt " 1 "Funktion gewählt" ;
VAL_ 1706 KBI_Menu2_Pos5 0 "Funktion nicht gewählt " 1 "Funktion gewählt" ;
VAL_ 1706 KBI_Menu2_Pos6 0 "Funktion nicht gewählt " 1 "Funktion gewählt" ;
VAL_ 1706 KBI_Menu2_Pos7 0 "Funktion nicht gewählt " 1 "Funktion gewählt" ;
VAL_ 1706 KBI_Menu2_Pos8 0 "Funktion nicht gewählt " 1 "Funktion gewählt" ;
VAL_ 1706 KBI_Menu3_Pos1 0 "Funktion nicht gewählt " 1 "Funktion gewählt" ;
VAL_ 1706 KBI_Menu3_Pos2 0 "Funktion nicht gewählt " 1 "Funktion gewählt" ;
VAL_ 1706 KBI_Menu3_Pos3 0 "Funktion nicht gewählt " 1 "Funktion gewählt" ;
VAL_ 1706 KBI_Menu3_Pos4 0 "Funktion nicht gewählt " 1 "Funktion gewählt" ;
VAL_ 1706 KBI_Menu3_Pos5 0 "Funktion nicht gewählt " 1 "Funktion gewählt" ;
VAL_ 1706 KBI_Menu3_Pos6 0 "Funktion nicht gewählt " 1 "Funktion gewählt" ;
VAL_ 1706 KBI_Menu3_Pos7 0 "Funktion nicht gewählt " 1 "Funktion gewählt" ;
VAL_ 1706 KBI_Menu3_Pos8 0 "Funktion nicht gewählt " 1 "Funktion gewählt" ;
VAL_ 282 KBI_Uhrzeit_SU 0 "keine_Uhrzeitanzeige" 1 "Uhrzeitanzeige_erlaubt" ;
VAL_ 282 KBI_E_Restreichweite 4094 "Init" 4095 "Fehler" ;
VAL_ 282 KBI_Uhrzeit_Kompass 0 "keine_Uhrzeit_anzeige_im_Kompass" 1 "Uhrzeitanzeige_im_Kompass" ;
VAL_ 1331 KBI_Chrono_Akt 0 "Inaktiv" 1 "Aktiv" ;
VAL_ 1331 KBI_Trip_Reset_Min 63 "Fehler" ;
VAL_ 1331 KBI_Trip_Reset_Std 31 "Fehler" ;
VAL_ 1329 KBI_St_Disp 0 "aus" 1 "an" ;
VAL_ 1534 KBI_Set_Timer_MUX 0 "leer" 1 "Timer_1" 2 "Timer_2" 3 "Timer_3" 4 "Timer_4" 5 "reserviert" 6 "reserviert" 7 "reserviert" ;
VAL_ 1534 KBI_Set_Timer_1_Jahr 126 "Init" 127 "reserviert" ;
VAL_ 1534 KBI_Set_Timer_2_Jahr 126 "Init" 127 "reserviert" ;
VAL_ 1534 KBI_Set_Timer_3_Jahr 126 "Init" 127 "reserviert" ;
VAL_ 1534 KBI_Set_Timer_4_Jahr 126 "Init" 127 "reserviert" ;
VAL_ 1534 KBI_Set_Timer_1_Minute 60 "reserviert" 61 "reserviert" 62 "Init" 63 "Fehler" ;
VAL_ 1534 KBI_Set_Timer_2_Minute 60 "reserviert" 61 "reserviert" 62 "Init" 63 "Fehler" ;
VAL_ 1534 KBI_Set_Timer_1_Monat 0 "Init" 14 "reserviert" 15 "Fehler" ;
VAL_ 1534 KBI_Set_Timer_2_Monat 0 "Init" 14 "reserviert" 15 "Fehler" ;
VAL_ 1534 KBI_Set_Timer_3_Monat 0 "Init" 14 "reserviert" 15 "Fehler" ;
VAL_ 1534 KBI_Set_Timer_4_Monat 0 "Init" 14 "reserviert" 15 "Fehler" ;
VAL_ 1534 KBI_Set_Timer_1_Stunde 24 "reserviert" 25 "reserviert" 26 "reserviert" 27 "reserviert" 28 "reserviert" 29 "reserviert" 30 "Init" 31 "Fehler" ;
VAL_ 1534 KBI_Set_Timer_2_Stunde 24 "reserviert" 25 "reserviert" 26 "reserviert" 27 "reserviert" 28 "reserviert" 29 "reserviert" 30 "Init" 31 "Fehler" ;
VAL_ 1534 KBI_Set_Timer_3_Stunde 24 "reserviert" 25 "reserviert" 26 "reserviert" 27 "reserviert" 28 "reserviert" 29 "reserviert" 30 "Init" 31 "Fehler" ;
VAL_ 1534 KBI_Set_Timer_4_Stunde 24 "reserviert" 25 "reserviert" 26 "reserviert" 27 "reserviert" 28 "reserviert" 29 "reserviert" 30 "Init" 31 "Fehler" ;
VAL_ 1534 KBI_Set_Timer_1_Tag 0 "Init" ;
VAL_ 1534 KBI_Set_Timer_2_Tag 0 "Init" ;
VAL_ 1534 KBI_Set_Timer_3_Tag 0 "Init" ;
VAL_ 1534 KBI_Set_Timer_4_Tag 0 "Init" ;
VAL_ 1534 KBI_Set_Timer_1_Laden 0 "Timer_nicht_aktiv" 1 "Timer_aktiv" ;
VAL_ 1534 KBI_Set_Timer_2_Laden 0 "Timer_nicht_aktiv" 1 "Timer_aktiv" ;
VAL_ 1534 KBI_Set_Timer_3_Laden 0 "Timer_nicht_aktiv" 1 "Timer_aktiv" ;
VAL_ 1534 KBI_Set_Timer_4_Laden 0 "Timer_nicht_aktiv" 1 "Timer_aktiv" ;
VAL_ 1534 KBI_Set_Timer_1_Vorklima 0 "Timer_nicht_aktiv" 1 "Timer_aktiv" ;
VAL_ 1534 KBI_Set_Timer_2_Vorklima 0 "Timer_nicht_aktiv" 1 "Timer_aktiv" ;
VAL_ 1534 KBI_Set_Timer_3_Vorklima 0 "Timer_nicht_aktiv" 1 "Timer_aktiv" ;
VAL_ 1534 KBI_Set_Timer_4_Vorklima 0 "Timer_nicht_aktiv" 1 "Timer_aktiv" ;
VAL_ 1534 KBI_Set_Timer_1_Zyklus_Mo 0 "Timer_am_Wochentag_nicht_aktiv" 1 "Timer_am_Wochentag_aktiv" ;
VAL_ 1534 KBI_Set_Timer_2_Zyklus_Mo 0 "Timer_am_Wochentag_nicht_aktiv" 1 "Timer_am_Wochentag_aktiv" ;
VAL_ 1534 KBI_Set_Timer_3_Zyklus_Mo 0 "Timer_am_Wochentag_nicht_aktiv" 1 "Timer_am_Wochentag_aktiv" ;
VAL_ 1534 KBI_Set_Timer_4_Zyklus_Mo 0 "Timer_am_Wochentag_nicht_aktiv" 1 "Timer_am_Wochentag_aktiv" ;
VAL_ 1534 KBI_Set_Timer_1_Zyklus_Di 0 "Timer_am_Wochentag_nicht_aktiv" 1 "Timer_am_Wochentag_aktiv" ;
VAL_ 1534 KBI_Set_Timer_2_Zyklus_Di 0 "Timer_am_Wochentag_nicht_aktiv" 1 "Timer_am_Wochentag_aktiv" ;
VAL_ 1534 KBI_Set_Timer_3_Zyklus_Di 0 "Timer_am_Wochentag_nicht_aktiv" 1 "Timer_am_Wochentag_aktiv" ;
VAL_ 1534 KBI_Set_Timer_4_Zyklus_Di 0 "Timer_am_Wochentag_nicht_aktiv" 1 "Timer_am_Wochentag_aktiv" ;
VAL_ 1534 KBI_Set_Timer_1_Zyklus_Mi 0 "Timer_am_Wochentag_nicht_aktiv" 1 "Timer_am_Wochentag_aktiv" ;
VAL_ 1534 KBI_Set_Timer_2_Zyklus_Mi 0 "Timer_am_Wochentag_nicht_aktiv" 1 "Timer_am_Wochentag_aktiv" ;
VAL_ 1534 KBI_Set_Timer_3_Zyklus_Mi 0 "Timer_am_Wochentag_nicht_aktiv" 1 "Timer_am_Wochentag_aktiv" ;
VAL_ 1534 KBI_Set_Timer_4_Zyklus_Mi 0 "Timer_am_Wochentag_nicht_aktiv" 1 "Timer_am_Wochentag_aktiv" ;
VAL_ 1534 KBI_Set_Timer_1_Zyklus_Do 0 "Timer_am_Wochentag_nicht_aktiv" 1 "Timer_am_Wochentag_aktiv" ;
VAL_ 1534 KBI_Set_Timer_2_Zyklus_Do 0 "Timer_am_Wochentag_nicht_aktiv" 1 "Timer_am_Wochentag_aktiv" ;
VAL_ 1534 KBI_Set_Timer_3_Zyklus_Do 0 "Timer_am_Wochentag_nicht_aktiv" 1 "Timer_am_Wochentag_aktiv" ;
VAL_ 1534 KBI_Set_Timer_4_Zyklus_Do 0 "Timer_am_Wochentag_nicht_aktiv" 1 "Timer_am_Wochentag_aktiv" ;
VAL_ 1534 KBI_Set_Timer_1_Zyklus_Fr 0 "Timer_am_Wochentag_nicht_aktiv" 1 "Timer_am_Wochentag_aktiv" ;
VAL_ 1534 KBI_Set_Timer_2_Zyklus_Fr 0 "Timer_am_Wochentag_nicht_aktiv" 1 "Timer_am_Wochentag_aktiv" ;
VAL_ 1534 KBI_Set_Timer_3_Zyklus_Fr 0 "Timer_am_Wochentag_nicht_aktiv" 1 "Timer_am_Wochentag_aktiv" ;
VAL_ 1534 KBI_Set_Timer_4_Zyklus_Fr 0 "Timer_am_Wochentag_nicht_aktiv" 1 "Timer_am_Wochentag_aktiv" ;
VAL_ 1534 KBI_Set_Timer_1_Zyklus_Sa 0 "Timer_am_Wochentag_nicht_aktiv" 1 "Timer_am_Wochentag_aktiv" ;
VAL_ 1534 KBI_Set_Timer_2_Zyklus_Sa 0 "Timer_am_Wochentag_nicht_aktiv" 1 "Timer_am_Wochentag_aktiv" ;
VAL_ 1534 KBI_Set_Timer_3_Zyklus_Sa 0 "Timer_am_Wochentag_nicht_aktiv" 1 "Timer_am_Wochentag_aktiv" ;
VAL_ 1534 KBI_Set_Timer_4_Zyklus_Sa 0 "Timer_am_Wochentag_nicht_aktiv" 1 "Timer_am_Wochentag_aktiv" ;
VAL_ 1534 KBI_Set_Timer_1_Zyklus_So 0 "Timer_am_Wochentag_nicht_aktiv" 1 "Timer_am_Wochentag_aktiv" ;
VAL_ 1534 KBI_Set_Timer_2_Zyklus_So 0 "Timer_am_Wochentag_nicht_aktiv" 1 "Timer_am_Wochentag_aktiv" ;
VAL_ 1534 KBI_Set_Timer_3_Zyklus_So 0 "Timer_am_Wochentag_nicht_aktiv" 1 "Timer_am_Wochentag_aktiv" ;
VAL_ 1534 KBI_Set_Timer_4_Zyklus_So 0 "Timer_am_Wochentag_nicht_aktiv" 1 "Timer_am_Wochentag_aktiv" ;
VAL_ 1534 KBI_Set_Timer_1_Zyklus_WH 0 "zyklisch" 1 "einmalig" ;
VAL_ 1534 KBI_Set_Timer_2_Zyklus_WH 0 "zyklisch" 1 "einmalig" ;
VAL_ 1534 KBI_Set_Timer_3_Zyklus_WH 0 "zyklisch" 1 "einmalig" ;
VAL_ 1534 KBI_Set_Timer_4_Zyklus_WH 0 "zyklisch" 1 "einmalig" ;
VAL_ 1535 KBI_Service_km 1022 "Init" 1023 "Fehler" ;
VAL_ 1535 KBI_Service_Typ 0 "Init" 1 "naechste_Wartung_ist_Zwischenwartung" 2 "naechste_Wartung_ist_Hauptwartung" 3 "naechste_Wartung_ist_Oelservice" ;
VAL_ 1535 KBI_Service_Zeit 2046 "Init" 2047 "Fehler" ;
VAL_ 1343 KBI_Trip_E_Verbr_fortl 1022 "Init" 1023 "Fehler" ;
VAL_ 1343 KBI_Trip_E_Verbr_seit 1022 "Init" 1023 "Fehler" ;
VAL_ 1343 KBI_Trip_E_Strecke_fortl 131070 "Init" 131071 "Fehler" ;
VAL_ 1343 KBI_Trip_E_Strecke_seit 131070 "Init" 131071 "Fehler" ;
VAL_ 1662 LAD_Abregelung_Temperatur 0 "keine_Begrenzung" 1 "Abregelung_Temp" ;
VAL_ 1662 LAD_Abregelung_IU_Ein_Aus 0 "keine_Abregelung" 1 "Abregelung_UI" ;
VAL_ 1662 LAD_Abregelung_BuchseTemp 0 "keine_Abregelung" 1 "Abregelung_Buchsentemp" ;
VAL_ 1662 LAD_MaxLadLeistung_HV 510 "Init" 511 "Fehler" ;
VAL_ 1662 LAD_CP_Stromlimit 126 "Init" 127 "Fehler" ;
VAL_ 1662 LAD_PRX_Stromlimit 0 "13_Ampere" 1 "20_Ampere" 2 "32_Ampere" 3 "63_Ampere" 6 "Init" 7 "Fehler" ;
VAL_ 1662 LAD_CP_Erkennung 0 "CP_nicht_erkannt" 1 "CP_erkannt" ;
VAL_ 1662 LAD_Stecker_Verriegelt 0 "nicht_verriegelt" 1 "verriegelt" ;
VAL_ 1662 LAD_Stecker_Gesteckt 0 "kein_Stecker_erkannt" 1 "Stecker_erkannt" ;
VAL_ 1662 LAD_Kuehlbedarf 0 "kein_Kuehlbedarf" 1 "geringer_Kuehlbedarf" 2 "mittlerer_Kuehlbedarf" 3 "hoher_Kuehlbedarf" ;
VAL_ 1662 LAD_Warnzustand 0 "keine_Warnung" 1 "Warnung_aktiv" ;
VAL_ 1662 LAD_Fehlerzustand 0 "kein_Fehler_aktiv" 1 "Fehler_aktiv_Laden_beendet" ;
VAL_ 810 EPS_SpannungsAnf 0 "keine_Anforderung" 1 "Anforderung_Stufe1" 2 "Anforderung_Stufe2" 3 "Anforderung_Stufe3" ;
VAL_ 810 EPS_Akustiksignal 0 "Akustiksignal_nicht_aktiv" 1 "Akustiksignal_aktiv" ;
VAL_ 810 EPS_Fehlerlampe 0 "Lampe_aus" 1 "Lampe_ein" ;
VAL_ 810 EPS_KD_Fehler 0 "kein_KD_Fehler" 1 "KD_Fehler" ;
VAL_ 810 EPS_Warnungen 0 "kein_Text" 1 "Text_1" 2 "Text_2" 3 "Text_3" 4 "Text_4" 5 "Text_5" ;
VAL_ 810 EPS_Charisma_FahrPr 0 "nicht_belegt" 1 "Programm_1" 2 "Programm_2" 3 "Programm_3" 4 "Programm_4" 5 "Programm_5" 6 "Programm_6" 7 "Programm_7" ;
VAL_ 810 EPS_Charisma_Status 0 "Init" 1 "verfuegbar" 2 "nicht_verfuegbar" 3 "asynchron_durch_Fahrerwunsch" ;
VAL_ 810 EPS_Charisma_Umschaltung 0 "Idle" 1 "Erkennung_Umschaltaufforderung" 2 "Steuerbotschaft_nicht_definiert" 3 "Umschaltung_verzoegert" ;
VAL_ 810 EPS_Lenkerposition 0 "unbekannt" 1 "Linkslenker" 2 "Rechtslenker" ;
VAL_ 810 EPS_Anf_KL 0 "keine_Anforderung" 1 "Anforderung_Kuehlung" ;
VAL_ 1137 BCM2_Bremsl_durch_ECD 0 "Bremslicht_ist_aus" 1 "Bremslicht_durch_ECD_aktiv" ;
VAL_ 1137 LH_Aussenlicht_def 0 "OK" 1 "defekt" ;
VAL_ 1137 LH_Standlicht_H_aktiv 1 "Standlicht hinten aktiv" ;
VAL_ 1137 LH_Parklicht_HL_aktiv 0 "nicht aktiv" 1 "Parklicht hinten links aktiv" ;
VAL_ 1137 LH_Parklicht_HR_aktiv 0 "nicht aktiv" 1 "Parklicht hinten rechts aktiv" ;
VAL_ 1137 LH_Bremslicht_H_aktiv 1 "Bremslicht hinten aktiv" ;
VAL_ 1137 LH_Nebelschluss_aktiv 0 "nicht aktiv" 1 "aktiv" ;
VAL_ 1137 LH_Rueckfahrlicht_aktiv 0 "nicht aktiv" 1 "aktiv" ;
VAL_ 1137 LH_Blinker_HL_akt 1 "Blinker hinten links aktiv" ;
VAL_ 1137 LH_Blinker_HR_akt 1 "Blinker hinten rechts aktiv" ;
VAL_ 1137 LH_Blinker_li_def 0 "OK" 1 "Blinker hinten links defekt" ;
VAL_ 1137 LH_Bremsl_li_def 0 "OK" 1 "mindestens ein Bremslicht hinten links defekt" ;
VAL_ 1137 LH_Schlusslicht_li_def 0 "OK" 1 "mindestens ein Schlusslicht hinten links defekt" ;
VAL_ 1137 LH_Rueckf_li_def 0 "OK" 1 "Rückfahrlicht hinten links defekt" ;
VAL_ 1137 LH_Nebel_li_def 0 "OK" 1 " Nebelschlusslicht hinten links defekt" ;
VAL_ 1137 LH_Schluss_Brems_Nebel_li_def 0 "iO" 1 "defekt" ;
VAL_ 1137 LH_Schluss_Brems_Nebel_re_def 0 "iO" 1 "defekt" ;
VAL_ 1137 LH_Schluss_Brems_li_def 0 "OK" 1 "defekt" ;
VAL_ 1137 LH_Schluss_Nebel_li_def 0 "OK" 1 "defekt" ;
VAL_ 1137 LH_SL_BRL_BLK_li_def 0 "OK" 1 "defekt" ;
VAL_ 1137 LH_Brems_Blk_li_def 0 "OK" 1 "defekt" ;
VAL_ 1137 LH_Blinker_re_def 0 "OK" 1 "Blinker hinten rechts defekt" ;
VAL_ 1137 LH_Bremsl_re_def 0 "OK" 1 "mindestens ein Bremslicht hinten rechts defekt" ;
VAL_ 1137 LH_Schlusslicht_re_def 0 "OK" 1 "mindestens ein Schlusslicht hinten rechts defekt" ;
VAL_ 1137 LH_Rueckf_re_def 0 "OK" 1 "Rückfahrlicht hinten rechts defekt" ;
VAL_ 1137 LH_Nebel_re_def 0 "OK" 1 "Nebelschlusslicht hinten rechts defekt" ;
VAL_ 1137 LH_Schluss_Brems_re_def 0 "OK" 1 "defekt" ;
VAL_ 1137 LH_Schluss_Nebel_re_def 0 "OK" 1 "defekt" ;
VAL_ 1137 LH_SL_BRL_BLK_re_def 0 "OK" 1 "defekt" ;
VAL_ 1137 LH_Brems_Blk_re_def 0 "OK" 1 "defekt" ;
VAL_ 1137 LH_Kennzl_def 0 "OK" 1 "Kennzeichenbeleuchtung hinten defekt" ;
VAL_ 1137 LH_3_Bremsl_def 0 "OK" 1 "hochgesetzte  Bremsleuchte defekt" ;
VAL_ 1137 LH_Nebel_mi_def 0 "OK" 1 " Nebelschlusslicht hinten Mitte defekt" ;
VAL_ 1137 LH_Rueckf_mi_def 0 "OK" 1 "Rückfahllicht Mitte defekt" ;
VAL_ 1137 LH_Bremsl_li_ges_def 0 "OK" 1 "Alle Bremslichter hinten links defekt" ;
VAL_ 1137 LH_Bremsl_re_ges_def 0 "OK" 1 "Alle Bremslichter hinten rechts defekt" ;
VAL_ 1321 Lift_Status 0 "Lift_in_Endlage_unten" 1 "Lift_in_Endlage_oben" 2 "Ausfuehrung_Hebevorgang" 3 "Ausfuehrung_Senkvorgang" 4 "System_voruebergehend_nicht_verfuegbar" 5 "Warnung_Vorderwagen_nicht_abgesenkt" 6 "tbd" 7 "Fehler" ;
VAL_ 1321 Lift_Charisma_FahrPr 0 "nicht_belegt" 1 "Programm_1" 2 "Programm_2" 3 "Programm_3" 4 "Programm_4" 5 "Programm_5" 6 "Programm_6" 7 "Programm_7" ;
VAL_ 1321 Lift_Charisma_Status 0 "Init" 1 "verfuegbar" 2 "nicht_verfuegbar" 3 "asynchron_durch_Fahrerwunsch" ;
VAL_ 1321 Lift_Charisma_Umschaltung 0 "Idle" 1 "Erkennung_Umschaltaufforderung" 2 "Steuerbotschaft_nicht_definiert" 3 "Umschaltung_verzoegert" ;
VAL_ 1321 Lift_KD_Fehler 0 "kein_KD_Fehler" 1 "KD_Fehler" ;
VAL_ 917 AFS_Abbiegelicht_li_Anf 0 "Abbiegelicht_aus" 1 "Abbiegelicht_ein" ;
VAL_ 917 AFS_Abbiegelicht_re_Anf 0 "Abbiegelicht_aus" 1 "Abbiegelicht_ein" ;
VAL_ 917 AFS_Abbiegelicht_Dimm_Anf 0 "Dimmung_angefordert" 1 "keine_Dimmung" ;
VAL_ 917 AFS_Verfuegbarkeit_GLW 0 "GLW_nicht_verfuegbar" 1 "GLW_verfuegbar" ;
VAL_ 917 AFS_Status_adaptive_LV 0 "adaptive_Lichtverteilung_aus" 1 "adaptive_Lichtverteilung_an" ;
VAL_ 917 AFS_Fernlicht_li_defekt 0 "Fernlicht_in_Ordnung" 1 "Fernlicht_defekt" ;
VAL_ 917 AFS_Fernlicht_re_defekt 0 "Fernlicht_in_Ordnung" 1 "Fernlicht_defekt" ;
VAL_ 917 AFS_Fernlicht_Status 0 "Fernlicht_aus" 1 "Fernlicht_ein" ;
VAL_ 917 AFS_Lampe 0 "Aus" 1 "Ein" ;
VAL_ 917 LWR_Lampe 0 "LWR Fehlerlampe aus" 1 "LWR Fehlerlampe ein" ;
VAL_ 917 AFS_Fehlertext 0 "kein Text" 1 "AFS ohne Funktion" ;
VAL_ 917 AFS_LED_Blinkmode 0 "kein Blinkmode angefordert" 1 "Blinkmode angefordert" ;
VAL_ 917 LWR_Touristenmodus_aktiv 0 "Touristenmodus inaktiv" 1 "Touristenmodus aktiv" ;
VAL_ 917 AFS_Charisma_FahrPr 0 "nicht_belegt" 1 "Programm_1" 2 "Programm_2" 3 "Programm_3" 4 "Programm_4" 5 "Programm_5" 6 "Programm_6" 7 "Programm_7" ;
VAL_ 917 AFS_Charisma_Status 0 "Init" 1 "verfuegbar" 2 "nicht_verfuegbar" 3 "asynchron_durch_Fahrerwunsch" ;
VAL_ 917 AFS_Charisma_Umschaltung 0 "Idle" 1 "Erkennung_Umschaltaufforderung" 2 "Steuerbotschaft_nicht_definiert" 3 "Umschaltung_verzoegert" ;
VAL_ 917 AFS_Allwetterlicht 0 "Allwetterlicht_nicht_aktiv" 1 "Allwetterlicht_aktiv" ;
VAL_ 917 LWR_Touristenmodus_verbaut 0 "Touristenmodus_nicht_verbaut" 1 "Touristenmodus_verbaut" ;
VAL_ 917 AFS_adaptive_LV_verbaut 0 "adaptive_Lichtverteilung_nicht_verbaut" 1 "adaptive_Lichtverteilung_verbaut" ;
VAL_ 917 LWR_Reisemodus_Texte 0 "keine_Anzeige" 1 "Umschaltung_auf_Linksverkehr_aktiv" 2 "Umschaltung_auf_Rechtsverkehr_aktiv" ;
VAL_ 917 GLW_Sensor_blockiert 0 "Kamera_Sensor_nicht_blockiert" 1 "Kamera_Sensor_blockiert" ;
VAL_ 917 LWR_Pos_Schrittmotor 254 "Init" 255 "Fehler" ;
VAL_ 917 LWR_Hoehenwert_VL 254 "nicht_initialisiert" 255 "Fehler" ;
VAL_ 917 LWR_Hoehenwert_HL 254 "nicht_initialisiert" 255 "Fehler" ;
VAL_ 917 AFS_Ersatzlicht_Links 0 "keine Ersatzlichtfunktion links" 1 "Ersatzlichtfunktion links" ;
VAL_ 917 AFS_Ersatzlicht_Rechts 0 "keine Ersatzlichtfunktion rechts" 1 "Ersatzlichtfunktion rechts" ;
VAL_ 917 LWR_AFS_Grundeinstellung 0 "Grundeinstellung nicht erfolgt" 1 "Grundeinstellung erfolgt" ;
VAL_ 917 LWR_AFS_Parametrisierung 0 "Parametrisierung nicht erfolgt" 1 "Parametrisierung erfolgt" ;
VAL_ 917 LWR_Initialisierungslauf 0 "Initialisierungslauf nicht erfolgt" 1 "Initialisierungslauf erfolgt" ;
VAL_ 917 LWR_Sicherheitsposition 0 "Sicherheitsposition aus" 1 "Sicherheitsposition ein" ;
VAL_ 917 LWR_Modus 0 "LWR statisch" 1 "LWR dynamisch" ;
VAL_ 917 LWR_KD_Fehler 0 "kein_KD_Fehler" 1 "KD_Fehler" ;
VAL_ 1704 KBI_Aussenspiegel_absenken_auto 0 "aus" 1 "ein" ;
VAL_ 1704 KBI_Aussenspiegel_einklapp_auto 0 "aus" 1 "ein" ;
VAL_ 1704 KBI_Schaltpkt_Anz_ein 0 "aus" 1 "ein" ;
VAL_ 1704 KBI_FULL_AFS_Tourist 0 "Basiscodierung" 1 "Basiscodierung invertiert" ;
VAL_ 1704 KBI_Einstiegshilfe_aktiv 0 "Inaktiv" 1 "Aktiv" ;
VAL_ 1704 KBI_Schneekettenmodus_Aktiv 0 "inaktiv" 1 "aktiv" ;
VAL_ 1704 KBI_FLA_GLW_Aktiv 0 "Einstellung_FLA_GLW_inaktiv" 1 "Einstellung_FLA_GLW_aktiv" ;
VAL_ 1704 KBI_RS_d_akt 0 "Autoaktiv" 1 "nicht Autoaktiv" ;
VAL_ 1704 KBI_Auto_Umluft 0 "Inaktiv" 1 "Aktiv" ;
VAL_ 1704 KBI_Heckrollo_b_R 0 "Inaktiv" 1 "Aktiv" ;
VAL_ 1704 KBI_TFL_akt 0 "Inaktiv" 1 "Aktiv" ;
VAL_ 1704 KBI_Heckw_b_R 0 "inaktiv" 1 "aktiv" 2 "nicht definiert" 3 "nicht definiert" ;
VAL_ 1704 KBI_Tuerentr_T 0 "beide Türen" 1 "nur Fahrertür" ;
VAL_ 1704 KBI_Carjack 0 "inaktiv" 1 "verr. bei KL15" 2 "verr. bei v> 0 km/h" 3 "verr. bei KL15 oder v>0km/h" ;
VAL_ 1704 KBI_WV_Entr_Kof 0 "Tueren werden nicht entriegelt" 1 "10 Sek." 2 "15 Sek." 3 "20 Sek." 4 "25 Sek" 5 "30 Sek." 6 "35 Sek." 7 "40 Sek." 8 "45 Sek." 9 "50 Sek." 10 "55 Sek." 11 "60 Sek." 12 "65 Sek." 13 "70 Sek." 14 "75 Sek." 15 "80 Sek." ;
VAL_ 1704 KBI_Automem_Inaktiv 0 "Automem_aktiv" 1 "Automem_nicht_aktiv" ;
VAL_ 1704 KBI_Jokerkey_Hupe_Aktiv 0 "Einstellung_Jokerkey_Hupe_Inaktiv" 1 "Einstellung_Jokerkey_Hupe_Aktiv" ;
VAL_ 1704 KBI_LDW_aktiv 0 "Inaktiv" 1 "Aktiv" ;
VAL_ 1704 KBI_PTC_Zuheizer 0 "PTC_Zuheizer_Aus" 1 "PTC_Zuheizer_An" ;
VAL_ 1704 KBI_Steigerung_Luftmenge_Fond 0 "Aus" 1 "Ein" ;
VAL_ 1704 KBI_Klimastyles 0 "soft" 1 "medium" 2 "strong" 3 "nicht definiert" ;
VAL_ 1704 KBI_Dimmung_AmbLicht 126 "Init" 127 "Fehler" ;
VAL_ 1704 KBI_Innenlicht_per_Tuerkontakt 0 "aus" 1 "ein" ;
VAL_ 1471 MFL_Tastencode_1 0 "Key_Released__No_Key" 1 "Menu" 2 "Menu_Up__Next_Screen" 3 "Menu_Down__Previous_Screen" 4 "Up" 5 "Down" 6 "Up__Down_ThumbWheel" 7 "OK__ThumbWheel_Button" 8 "Cancel__Escape" 16 "Volume_Up" 17 "Volume_Down" 18 "Volume_Up__Down_ThumbWheel" 19 "Volume_ThumbWheel_Button" 20 "Audio_Source" 21 "Arrow_A_Up__Right" 22 "Arrow_A_Down__Left" 23 "Arrow_B_Up__Right" 24 "Arrow_B_Down__Left" 25 "PTT__PushToTalk" 26 "PTT_Cancel" 27 "Route_Info" 28 "Hook" 29 "Hang_Up" 30 "Off_Hook" 31 "Light_On__Off" 32 "Mute" 33 "Joker1" 34 "Joker2" 240 "Startup_Reset" ;
VAL_ 1471 MFL_Tastencode_2 0 "Key_Released__No_Key" 1 "Menu" 2 "Menu_Up__Next_Screen" 3 "Menu_Down__Previous_Screen" 4 "Up" 5 "Down" 6 "Up__Down_ThumbWheel" 7 "OK__ThumbWheel_Button" 8 "Cancel__Escape" 16 "Volume_Up" 17 "Volume_Down" 18 "Volume_Up__Down_ThumbWheel" 19 "Volume_ThumbWheel_Button" 20 "Audio_Source" 21 "Arrow_A_Up__Right" 22 "Arrow_A_Down__Left" 23 "Arrow_B_Up__Right" 24 "Arrow_B_Down__Left" 25 "PTT__PushToTalk" 26 "PTT_Cancel" 27 "Route_Info" 28 "Hook" 29 "Hang_Up" 30 "Off_Hook" 31 "Light_On__Off" 32 "Mute" 33 "Joker1" 34 "Joker2" 240 "Startup_Reset" ;
VAL_ 1471 MFL_Eventcode_1 0 "Walze: no Event     | Taste: no Event" 1 "Walze: 1 Tick  up   | Taste: pressed" 2 "Walze: 2 Ticks up   | " 3 "Walze: 3 Ticks up   | Taste: double-click" 4 "Walze: 4 Ticks up   | Taste: long-press 1 [800ms]" 5 "Walze: 5 Ticks up   | Taste: long-press 2 [2s]" 6 "Walze: 6 Ticks up   | Taste: long-press 3 [3s]" 7 "Walze: 7 Ticks up   |" 9 "Walze: 7 Ticks down |" 10 "Walze: 6 Ticks down |" 11 "Walze: 5 Ticks down |" 12 "Walze: 4 Ticks down |" 13 "Walze: 3 Ticks down |" 14 "Walze: 2 Ticks down |" 15 "Walze: 1 Tick  down |" ;
VAL_ 1471 MFL_Eventcode_2 0 "Walze: no Event     | Taste: no Event" 1 "Walze: 1 Tick  up   | Taste: pressed" 2 "Walze: 2 Ticks up   |  " 3 "Walze: 3 Ticks up   | Taste: double-click" 4 "Walze: 4 Ticks up   | Taste: long-press 1 [800ms]" 5 "Walze: 5 Ticks up   | Taste: long-press 2 [2s]" 6 "Walze: 6 Ticks up   | Taste: long-press 3 [3s]" 7 "Walze: 7 Ticks up   |" 9 "Walze: 7 Ticks down |" 10 "Walze: 6 Ticks down |" 11 "Walze: 5 Ticks down |" 12 "Walze: 4 Ticks down |" 13 "Walze: 3 Ticks down |" 14 "Walze: 2 Ticks down |" 15 "Walze: 1 Tick  down |" ;
VAL_ 1471 MFL_Marke 0 "VW" 1 "Audi" 2 "Seat" 3 "Skoda" 4 "VW_Nutzf" 5 "Bugatti" 6 "Lamborghini" 7 "Bentley" 8 "Rolls Royce" 9 "Quattro" 10 "kein_Hersteller_1" 11 "kein_Hersteller_2" 12 "kein_Hersteller_3" 13 "kein_Hersteller_4" 14 "Ford" 15 "Porsche" ;
VAL_ 193 Miko_KD_Fehler 0 "kein_KD_Fehler" 1 "KD_Fehler" ;
VAL_ 193 Miko_T_Defrost 0 "Taster nicht betaetigt" 1 "Taster betaetigt" ;
VAL_ 193 Miko_T_Auto 0 "Taster nicht betaetigt" 1 "Taster betaetigt" ;
VAL_ 193 Miko_T_Source 0 "Taster nicht betaetigt" 1 "Taster betaetigt" ;
VAL_ 193 Miko_T_AC_Menue 0 "Taster nicht betaetigt" 1 "Taster betaetigt" ;
VAL_ 193 Miko_T_Phone 0 "Taster nicht betaetigt" 1 "Taster betaetigt" ;
VAL_ 193 Miko_T_Media 0 "Taster nicht betaetigt" 1 "Taster betaetigt" ;
VAL_ 193 Miko_T_Tuner 0 "Taster nicht betaetigt" 1 "Taster betaetigt" ;
VAL_ 193 Miko_T_Back 0 "Taster nicht betaetigt" 1 "Taster betaetigt" ;
VAL_ 193 Miko_T_Option 0 "Taster nicht betaetigt" 1 "Taster betaetigt" ;
VAL_ 193 Miko_T_Car 0 "Taster nicht betaetigt" 1 "Taster betaetigt" ;
VAL_ 193 Miko_T_Info 0 "Taster nicht betaetigt" 1 "Taster betaetigt" ;
VAL_ 193 Miko_T_Navi 0 "Taster nicht betaetigt" 1 "Taster betaetigt" ;
VAL_ 193 Miko_T_Umluft 0 "Taster nicht betaetigt" 1 "Taster betaetigt" ;
VAL_ 193 Miko_T_AC 0 "Taster nicht betaetigt" 1 "Taster betaetigt" ;
VAL_ 193 Miko_T_Acmax 0 "Taster nicht betaetigt" 1 "Taster betaetigt" ;
VAL_ 193 Miko_Volume_Err 0 "kein_Fehler" 1 "Fehler" ;
VAL_ 193 Miko_Volume_dir 0 "incrementieren" 1 "decrementieren" ;
VAL_ 193 Miko_Volume_press 0 "Nicht_betaetigt" 1 "Langdruck" 2 "Kurzdruck" 3 "Fehler" ;
VAL_ 193 Miko_MMI_fast 0 "keine Fast-Verstellung" 1 "Fast-Verstellung" ;
VAL_ 193 Miko_MMI_Err 0 "kein_Fehler" 1 "Fehler" ;
VAL_ 193 Miko_MMI_dir 0 "incrementieren" 1 "decrementieren" ;
VAL_ 193 Miko_MMI_press 0 "Nicht_betaetigt" 1 "Langdruck" 2 "Kurzdruck" 3 "Fehler" ;
VAL_ 193 Miko_Clima_fast 0 "keine Fast-Verstellung" 1 "Fast-Verstellung" ;
VAL_ 193 Miko_Clima_Err 0 "kein_Fehler" 1 "Fehler" ;
VAL_ 193 Miko_Clima_dir 0 "incrementieren" 1 "decrementieren" ;
VAL_ 193 Miko_Clima_press 0 "Nicht_betaetigt" 1 "Langdruck" 2 "Kurzdruck" 3 "Fehler" ;
VAL_ 193 Miko_ADR_Reset 0 "Taster nicht betaetigt" 1 "Taster betaetigt" ;
VAL_ 193 Miko_ADR_UltralongPress 0 "Taster nicht betaetigt" 1 "Taster betaetigt" ;
VAL_ 193 Miko_T_Blower 0 "Taster nicht betaetigt" 1 "Taster betaetigt" ;
VAL_ 193 Miko_T_Temp_left 0 "Taster nicht betaetigt" 1 "Taster betaetigt" ;
VAL_ 193 Miko_T_Temp_right 0 "Taster nicht betaetigt" 1 "Taster betaetigt" ;
VAL_ 126 MO_Faktor_Momente_sek 0 "nicht_belegt" 1 "Faktor_1_Nm" 2 "Faktor_2_Nm" 3 "Faktor_4_Nm" ;
VAL_ 126 Enrgfluss_State_BN 0 "NV_Bordnetz_nicht_geladen" 1 "NV_Bordnetz_wird_geladen" 2 "reserviert" 3 "Fehler" ;
VAL_ 126 Enrgfluss_State_sek 0 "no_torques" 1 "pos_tor_EE" 2 "neg_tor_EE" 3 "Fehler" ;
VAL_ 126 MO_Mom_Soll_sek 1022 "Init" 1023 "Fehler" ;
VAL_ 126 MO_Mom_Ist_sek 1022 "Init" 1023 "Fehler" ;
VAL_ 126 MO_Faktor_Getriebe 254 "Init" 255 "Fehler" ;
VAL_ 263 MO_rel_Ladedruck 255 "Fehler" ;
VAL_ 263 MO_Istgang 0 "kein_Gang_eingelegt" 1 "Gang_1" 2 "Gang_2" 3 "Gang_3" 4 "Gang_4" 5 "Gang_5" 6 "Gang_6" 7 "Gang_7" 8 "Gang_8" 9 "Gang_9" ;
VAL_ 263 MO_Sollgang 0 "keine_Empfehlung" 1 "Gang_1" 2 "Gang_2" 3 "Gang_3" 4 "Gang_4" 5 "Gang_5" 6 "Gang_6" 7 "Gang_7" 8 "Gang_8" 9 "Gang_9" ;
VAL_ 263 MO_Oeldruck 254 "Init" 255 "Fehler" ;
VAL_ 263 MO_Anzeigedrehz 4095 "Fehler" ;
VAL_ 263 MO_Effizienzmodus 0 "nicht_im_Effizienz_Modus" 1 "Effizienz_Modus" ;
VAL_ 263 MO_Schaltempf_verfbar 0 "nicht_verfuegbar" 1 "verfuegbar" ;
VAL_ 263 MO_Ladedruck 511 "Fehler" ;
VAL_ 263 MO_KVS_Ueberlauf 0 "kein Ueberlauf" 1 "Kraftstoffverbrauchsignale mindestens 1x übergelaufen" ;
VAL_ 782 MO_EKlKomLeiRed 0 "keine_Leistungsbegr" 1 "Leistungsbegr_75" 2 "Leistungsbegr_50" 3 "Leistungsbegr_25" ;
VAL_ 782 MO_Freig_Reku 0 "Rekuperations-Modus aus" 1 "Empfehlung Spannungsanhebung" 2 "Empfehlung Spannungsabsenkung" 3 "Rekuperationsmodus aktiv, Spannungsvariation nicht notwendig" ;
VAL_ 782 MO_Klima_Eingr 0 "kein Eingriff" 1 "Klimakompressor ausschalten" 2 "Klimakompressor Leistungsreduzierung" 3 "Klimakompressor aufgrund der Heissleuchtenvorwarnung ausschalten" ;
VAL_ 782 MO_Status_Normalbetrieb_02 0 "kein Normalbetrieb" 1 "Normalbetrieb erreicht" ;
VAL_ 782 MO_Prio_MIN_Wunschdrehzahl 0 "Wunsch" 1 "Zwang" ;
VAL_ 782 MO_Freig_Anlass 0 "Start_nicht_zulaessig" 1 "Startfreigabe" ;
VAL_ 782 MO_Aussp_Anlass 0 "Anlasser_darf_angesteuert_werden" 1 "Anlasser_ausspuren__Ansteuerung_nicht_moeglich" ;
VAL_ 782 MO_MAX_Wunschdrehzahl 511 "Fehler" ;
VAL_ 782 MO_Prio_MAX_Wunschdrehzahl 0 "Wunsch" 1 "Zwang" ;
VAL_ 782 MO_Luftpfad_aktiv 0 "kein Eingriff oder nur Eingriff über Zündpfad" 1 "Eingriff über Luftpfad" ;
VAL_ 782 MO_v_Begrenz_Aktiv 0 "inaktiv" 1 "aktiv" ;
VAL_ 782 MO_v_Begrenz_Aktivierbar 0 "V-Begrenzung nicht möglich" 1 "V-Begrenzung möglich" ;
VAL_ 782 MO_Verbot_EKP 0 "Ansteuerung zugelassen" 1 "Ansteuerung verboten" ;
VAL_ 782 MO_Anf_Pruefimpuls 0 "keine Anforderung" 1 "Anforderung" ;
VAL_ 782 MO_Anf_KL75 0 "Anforderung KL75 ausschalten" 1 "Anforderung KL75 einschalten" ;
VAL_ 782 MO_Charisma_FahrPr 0 "nicht_belegt" 1 "Programm_1" 2 "Programm_2" 3 "Programm_3" 4 "Programm_4" 5 "Programm_5" 6 "Programm_6" 7 "Programm_7" ;
VAL_ 782 MO_Charisma_Status 0 "Init" 1 "verfuegbar" 2 "nicht_verfuegbar" 3 "asynchron_durch_Fahrerwunsch" ;
VAL_ 782 MO_Charisma_Umschaltung 0 "Idle" 1 "Erkennung_Umschaltaufforderung" 2 "Steuerbotschaft_nicht_definiert" 3 "Umschaltung_verzoegert" ;
VAL_ 782 MO_Handshake_STH 0 "keine EKP-Ansteuerung durch STH-Anforderung" 1 "EKP-Ansteuerung durch STH-Anforderung" ;
VAL_ 782 MO_MIN_Wunschdrehzahl 255 "Fehler" ;
VAL_ 1088 MO_Kuehlerluefter_MUX 0 "Kuehlerluefter_1" 1 "Kuehlerluefter_2" ;
VAL_ 1088 MO_Kuehlerluefter_1 126 "Init" 127 "Fehler" ;
VAL_ 1088 MO_Kuehlerluefter_2 126 "Init" 127 "Fehler" ;
VAL_ 1088 MO_HYB_Status_HV_Ladung 0 "HV-Ladung_nicht_notwendig" 1 "HV-Ladung_notwendig_Freigaben_erforderlich" 2 "HV-Ladung laeuf" 3 "HV-Ladung_erfolgreich_Motorstart_moeglich" 4 "HV_Ladung_abgebrochen" ;
VAL_ 1088 MO_ITM_Warnung_Pumpe 0 "keine_Warnung" 1 "ITM_Warnung" ;
VAL_ 1088 WIV_Anzeige_aktiv 0 "Anzeige aus" 1 "WIV Anzeige aktiv" ;
VAL_ 1088 WIV_Oelmin_Warn 0 "in_Ordnung" 1 "Warnung" ;
VAL_ 1088 WIV_Sensorfehler 0 "in_Ordnung" 1 "Sensor_defekt" ;
VAL_ 1088 WIV_Schieflage 0 "Fahrzeug_gerade" 1 "Fahrzeug_in_Schieflage" ;
VAL_ 1088 MO_Zustand_HWP 0 "HWP_nicht_schaltbar" 1 "HWP_foerdert_nicht" 2 "HWP_foerdert" 3 "reserviert" ;
VAL_ 1088 MO_Kat_Warnung 0 "Lampe_aus" 1 "Lampe_ein" ;
VAL_ 1088 WIV_Oelsystem_aktiv 0 "Anzeige_aus" 1 "Anzeige_aktiv" ;
VAL_ 1088 WIV_nicht_betriebswarm 0 "Motor_warm" 1 "Motor_nicht_betriebswarm" ;
VAL_ 1088 WIV_Ueberfuell_Warn 0 "in_Ordnung" 1 "Ueberfuellwarnung" ;
VAL_ 1088 WIV_laufender_Motor 0 "Messung_moeglich" 1 "Messung_nicht_moeglich" ;
VAL_ 1088 MO_HYB_Text_1 0 "kein_Text" 1 "Text_anzeigen" ;
VAL_ 1088 MO_HYB_Text_2 0 "kein_Text" 1 "Text_anzeigen" ;
VAL_ 1088 MO_HYB_Text_3 0 "kein_Text" 1 "Text_anzeigen" ;
VAL_ 1088 MO_HYB_Text_4 0 "kein_Text" 1 "Text_anzeigen" ;
VAL_ 1088 MO_Text_Motorstart 0 "keine_Anzeige" 1 "Motor_im_Stoppbetrieb" 2 "StartStopp_sicherheitsbedingt_deaktiviert" 3 "System_fordert_Wiederstart" 5 "Motorlauf_noetig" 9 "Unerwuenschter_Motorstillstand" 12 "Motor_startet" 13 "Kupplung_betaetigen" 14 "Waehlhebel_in_PN_Position" 15 "Bremse_treten" ;
VAL_ 1088 MO_HYB_Text_5 0 "kein_Text" 1 "Text_anzeigen" ;
VAL_ 1088 MO_HYB_Text_6 0 "kein_Text" 1 "Text_anzeigen" ;
VAL_ 1088 MO_HYB_Text_7 0 "kein_Text" 1 "Text_anzeigen" ;
VAL_ 1088 WIV_Oeldyn_avl 0 "Oeldyn_nicht_vorhanden" 1 "Oeldyn_vorhanden" ;
VAL_ 1088 MO_Systemlampe 0 "Lampe aus" 1 "Lampe ein" ;
VAL_ 1088 MO_OBD2_Lampe 0 "Lampe aus" 1 "Lampe ein" ;
VAL_ 1088 MO_Heissleuchte 0 "Lampe aus" 1 "Lampe ein" ;
VAL_ 1088 MO_Partikel_Lampe 0 "Lampe aus" 1 "Lampe ein" ;
VAL_ 1088 WIV_Oelstand_nicht_vorhanden 0 "Ölstand vorhanden" 1 "Ölstand nicht vorhanden" ;
VAL_ 1088 WIV_nachfuellanzeige_ein 0 "keine_Nachfuellanzeige" 1 "Nachfuellanzeige" ;
VAL_ 1088 WIV_Ueberfuell_deaktiv 0 "Ueberfuellwarnung_am_Kombi_aktiv" 1 "Ueberfuellwarnung_am_Kombi_deaktiv" ;
VAL_ 1088 WIV_Unterfuell_Warn 0 "in_Ordnung" 1 "Unterfuellwarnung" ;
VAL_ 1088 MO_Tankdeckel_Lampe 0 "Lampe aus" 1 "Lampe ein" ;
VAL_ 1088 MO_Text_Tankdeckelwarn 0 "kein_Text" 1 "Anzeige_Text_Tankdeckelwarnung_im_Kombi" ;
VAL_ 1088 WIV_Enable_Oeldr_Motor 0 "Oeldruckauswertung_im_Kombi" 1 "Oeldruckauswertung_im_MSG" ;
VAL_ 1088 WIV_Oeldr_Warn_Motor 0 "keine_Warnung" 1 "niedrige_Oeldruckstufe_nicht_erreicht " ;
VAL_ 1088 MO_Avus_Motorschutz 0 "keine Warnung" 1 "Drehzahlwarnung Stufe 1" 2 "Drehzahlwarnung Stufe 2" 3 "Drehzahlwarnung Stufe 3" ;
VAL_ 1088 MO_HYB_Fahrbereitschaft 0 "keine_Fahrbereitschaft" 1 "Fahrbereitschaft" ;
VAL_ 1600 MO_QBit_Ansaugluft_Temp 0 "gueltiger_Wert" 1 "Ersatz_Init_oder_Fehlerwert" ;
VAL_ 1600 MO_QBit_Oel_Temp 0 "gueltiger_Wert" 1 "Ersatz_Init_oder_Fehlerwert" ;
VAL_ 1600 MO_QBit_Kuehlmittel_Temp 0 "gueltiger_Wert" 1 "Ersatz_Init_oder_Fehlerwert" ;
VAL_ 1600 MO_HYB_Fehler_HV_Netz 0 "i_O" 1 "kein_generatorischer_Betrieb_moeglich" ;
VAL_ 1600 MO_aktives_Getriebeheizen 0 "kein_Ventil_ansteuern" 1 "Ventil_muss_angesteuert_werden" ;
VAL_ 1600 MO_Absperrventil_oeffnen 0 "nicht_verfuegbar" 1 "Ansteuerung_Ventil_zulaessig" 2 "Ventil_oeffnen_oder_geoeffnet" 3 "Ventil_schliessen_oder_geschlossen" ;
VAL_ 1600 MO_Ansaugluft_Temp 254 "Init" 255 "Fehler" ;
VAL_ 1600 MO_Oel_Temp 253 "nicht_verbaut" 254 "Init" 255 "Fehler" ;
VAL_ 1600 MO_Kuehlmittel_Temp 254 "Init" 255 "Fehler" ;
VAL_ 1600 MO_Hoeheninfo 255 "Fehler" ;
VAL_ 1600 MO_Kennfeldk 0 "keine Kennfeldkühlung vorhanden" 1 "Kennfeldkühlung vorhanden" ;
VAL_ 1600 MO_Versionsinfo 0 "zum Projektbeginn 'aufgeräumter CAN' " 1 "Motor_03_mit_10ms" 16 "MQB_mit_neuer_Momentenschnittstelle" ;
VAL_ 1600 MO_Getriebe_kuehlen 0 "nicht_kuehlen" 1 "kuehlen" ;
VAL_ 1600 MO_Heizungspumpenansteuerung 13 "Fehler" 14 "Init" 15 "nicht_verbaut" ;
VAL_ 1600 MO_SpannungsAnf 0 "keine_Anforderung" 1 "Anforderung" ;
VAL_ 933 Enrgfluss_State 0 "Init" 1 "no_torques" 2 "pos_tor_EE" 3 "pos_tor_ICE" 4 "pos_tor_ICE_bat_charge" 5 "pos_tor_EE_ICE" 6 "neg_tor_EE_bar_charge" 7 "neg_tor_EE_bat_discharge" 8 "neg_tor_EE" 9 "ICE_charge_bat" 10 "neg_tor_EE_and_ICE" 11 "no_tor_sailing" 12 "no_tor_sailing_and_ICE" 255 "Fehler" ;
VAL_ 933 Ladezustand 255 "Fehler" ;
VAL_ 933 Energiefluss 255 "Fehler" ;
VAL_ 933 Enrgrueckfluss 255 "Fehler" ;
VAL_ 933 MO_Powermeter 4093 "Off" ;
VAL_ 933 MO_Overboost 0 "inaktiv" 1 "aktiv" ;
VAL_ 933 MO_Anf_Abgasklappe 0 "nicht angesteuert" 1 "angesteuert" ;
VAL_ 933 MO_LED_Abgasklappe 0 "LED aus" 1 "LED ein" ;
VAL_ 933 MO_Fehler_MSpG 0 "i.O." 1 "Gebläse defekt oder Motorraumtemp. zu hoch" ;
VAL_ 933 MO_Temp_MotRaum 63 "Fehler" ;
VAL_ 933 MO_Hoch_Anz_Nmax 0 "inaktiv" 1 "aktiv" ;
VAL_ 933 MO_Hoch_Anz_Eco 0 "inaktiv" 1 "aktiv" ;
VAL_ 933 MO_Oel_Temp_Radsatz 254 "Initialwert" 255 "Fehler" ;
VAL_ 1601 MO_Faktor_Momente 0 "nicht belegt" 1 "Faktor: x 0,5Nm" 2 "Faktor: x 1,0Nm" 3 "Faktor: x 2,0Nm" ;
VAL_ 1601 MO_Hybridfahrzeug 0 "kein_Hybridfahrzeug" 1 "Mild_Hybrid" 2 "Full_Hybrid" 3 "PlugIn_Hybrid" ;
VAL_ 1601 MO_Getriebe_Code 2 "DL501" 3 "DL800" 4 "VL381" 5 "DL382" 6 "DL382_Hybrid" 8 "AL552" 9 "AL552_Hybrid" 10 "AL651" 11 "AL551__AL951__AL1000_8A" 12 "PDK_PAG" 13 "AL551_Hybrid" 15 "Handschalter_konventionell" 16 "AQ250" 17 "AQ450" 18 "DQ200" 19 "DQ250" 20 "DQ500" 21 "SQ100" 22 "SQ200" 32 "Single_Gear__ohne_GSG_WH_am_MSG" ;
VAL_ 1601 MO_StartStopp_Codiert 0 "Start_Stopp_nicht_verbaut" 1 "Start_Stopp_verbaut" ;
VAL_ 1601 MO_Anzahl_Zyl 0 "kein_Zylinder" 1 "1_Zylinder" 2 "2_Zylinder" 3 "3_Zylinder" 4 "4_Zylinder" 5 "5_Zylinder" 6 "6_Zylinder" 7 "7_Zylinder" 8 "8_Zylinder" 9 "9_Zylinder" 10 "10_Zylinder" 11 "11_Zylinder" 12 "12_Zylinder" 13 "15_Zylinder" 14 "16_Zylinder" 15 "18_Zylinder" ;
VAL_ 1601 MO_Kraftstoffart 0 "Diesel" 1 "Benzin_inkl_E25_E85" 2 "CNG" 3 "LPG" 4 "Wasserstoff" 5 "E100_Ethanol" 15 "kein_Verbrennungskraftstoff" ;
VAL_ 1601 MO_Ansaugsystem 0 "Turbo" 1 "Sauger" ;
VAL_ 1601 MO_Einspritzart 0 "MPI" 1 "FSI_TDI" ;
